VERSION ""

NS_ :

BS_:

BU_: MLM IBU_HS ILCU_RH MFSW DPSU ILCU_LH PSB APSU DPSS SWRC CGW PTGM DLBCU SCM DAU WPC IAU eCall PFSU RDC PSM

BO_ 3221225472 VECTOR__INDEPENDENT_SIG_MSG: 0 Vector__XXX
 SG_ SCC_NSCCOnOffSta : 0|2@1+ (1,0) [0|0] "" Vector__XXX
 SG_ SCC_ObjSta : 0|3@1+ (1,0) [0|0] "" Vector__XXX
 SG_ SCC_SnstvtyModRetVal : 0|3@1+ (1,0) [0|0] "" Vector__XXX
 SG_ APSS_GST_Byte0 : 0|8@1+ (1,0) [0|0] "" Vector__XXX
 SG_ APSS_GST_Byte1 : 0|8@1+ (1,0) [0|0] "" Vector__XXX
 SG_ APSS_GST_Byte2 : 0|8@1+ (1,0) [0|0] "" Vector__XXX
 SG_ APSS_GST_Byte3 : 0|8@1+ (1,0) [0|0] "" Vector__XXX
 SG_ APSS_GST_Byte4 : 0|8@1+ (1,0) [0|0] "" Vector__XXX
 SG_ APSS_GST_Byte5 : 0|8@1+ (1,0) [0|0] "" Vector__XXX
 SG_ APSS_GST_Byte6 : 0|8@1+ (1,0) [0|0] "" Vector__XXX
 SG_ APSS_GST_Byte7 : 0|8@1+ (1,0) [0|0] "" Vector__XXX
 SG_ eCall_GST_Byte0 : 0|8@1+ (1,0) [0|0] "" Vector__XXX
 SG_ eCall_GST_Byte1 : 0|8@1+ (1,0) [0|0] "" Vector__XXX
 SG_ eCall_GST_Byte2 : 0|8@1+ (1,0) [0|0] "" Vector__XXX
 SG_ eCall_GST_Byte3 : 0|8@1+ (1,0) [0|0] "" Vector__XXX
 SG_ eCall_GST_Byte4 : 0|8@1+ (1,0) [0|0] "" Vector__XXX
 SG_ eCall_GST_Byte5 : 0|8@1+ (1,0) [0|0] "" Vector__XXX
 SG_ eCall_GST_Byte6 : 0|8@1+ (1,0) [0|0] "" Vector__XXX
 SG_ eCall_GST_Byte7 : 0|8@1+ (1,0) [0|0] "" Vector__XXX
 SG_ SCC_TrgtDstVal : 0|11@1+ (0.1,0) [0|0] "m" Vector__XXX
 SG_ DATC_Crc5Val : 0|16@1+ (1,0) [0|0] "" Vector__XXX
 SG_ DATC_AlvCnt5Val : 0|8@1+ (1,0) [0|0] "" Vector__XXX
 SG_ DATC_TempDispUnitSta : 0|2@1+ (1,0) [0|0] "" Vector__XXX
 SG_ DATC_IntakeSta : 0|2@1+ (1,0) [0|0] "" Vector__XXX
 SG_ SWRC_Crc3Val : 0|8@1+ (1,0) [0|0] "" Vector__XXX
 SG_ SWRC_AlvCnt3Val : 0|4@1+ (1,0) [0|0] "" Vector__XXX
 SG_ SWRC_CrsSwSta : 0|3@1+ (1,0) [0|0] "" Vector__XXX
 SG_ SWRC_CrsMainSwSta : 0|2@1+ (1,0) [0|0] "" Vector__XXX
 SG_ SWRC_LFASwSta : 0|2@1+ (1,0) [0|0] "" Vector__XXX
 SG_ SWRC_PaddleUpSwSta : 0|2@1+ (1,0) [0|0] "" Vector__XXX
 SG_ SWRC_PaddleDnSwSta : 0|2@1+ (1,0) [0|0] "" Vector__XXX
 SG_ SWRC_Info : 0|2@1+ (1,0) [0|0] "" Vector__XXX
 SG_ GST_SCM_Byte0 : 0|8@1+ (1,0) [0|0] "" Vector__XXX
 SG_ GST_SCM_Byte1 : 0|8@1+ (1,0) [0|0] "" Vector__XXX
 SG_ GST_SCM_Byte2 : 0|8@1+ (1,0) [0|0] "" Vector__XXX
 SG_ GST_SCM_Byte3 : 0|8@1+ (1,0) [0|0] "" Vector__XXX
 SG_ GST_SCM_Byte4 : 0|8@1+ (1,0) [0|0] "" Vector__XXX
 SG_ GST_SCM_Byte5 : 0|8@1+ (1,0) [0|0] "" Vector__XXX
 SG_ GST_SCM_Byte6 : 0|8@1+ (1,0) [0|0] "" Vector__XXX
 SG_ GST_SCM_Byte7 : 0|8@1+ (1,0) [0|0] "" Vector__XXX
 SG_ GST_SWRC_Byte0 : 0|8@1+ (1,0) [0|0] "" Vector__XXX
 SG_ GST_SWRC_Byte1 : 0|8@1+ (1,0) [0|0] "" Vector__XXX
 SG_ GST_SWRC_Byte2 : 0|8@1+ (1,0) [0|0] "" Vector__XXX
 SG_ GST_SWRC_Byte3 : 0|8@1+ (1,0) [0|0] "" Vector__XXX
 SG_ GST_SWRC_Byte4 : 0|8@1+ (1,0) [0|0] "" Vector__XXX
 SG_ GST_SWRC_Byte5 : 0|8@1+ (1,0) [0|0] "" Vector__XXX
 SG_ GST_SWRC_Byte6 : 0|8@1+ (1,0) [0|0] "" Vector__XXX
 SG_ GST_SWRC_Byte7 : 0|8@1+ (1,0) [0|0] "" Vector__XXX
 SG_ GST_MFSW_Byte0 : 0|8@1+ (1,0) [0|0] "" Vector__XXX
 SG_ GST_MFSW_Byte1 : 0|8@1+ (1,0) [0|0] "" Vector__XXX
 SG_ GST_MFSW_Byte2 : 0|8@1+ (1,0) [0|0] "" Vector__XXX
 SG_ GST_MFSW_Byte3 : 0|8@1+ (1,0) [0|0] "" Vector__XXX
 SG_ GST_MFSW_Byte4 : 0|8@1+ (1,0) [0|0] "" Vector__XXX
 SG_ GST_MFSW_Byte5 : 0|8@1+ (1,0) [0|0] "" Vector__XXX
 SG_ GST_MFSW_Byte6 : 0|8@1+ (1,0) [0|0] "" Vector__XXX
 SG_ GST_MFSW_Byte7 : 0|8@1+ (1,0) [0|0] "" Vector__XXX
 SG_ GST_DAU_Byte0 : 0|8@1+ (1,0) [0|0] "" Vector__XXX
 SG_ GST_DAU_Byte1 : 0|8@1+ (1,0) [0|0] "" Vector__XXX
 SG_ GST_DAU_Byte2 : 0|8@1+ (1,0) [0|0] "" Vector__XXX
 SG_ GST_DAU_Byte3 : 0|8@1+ (1,0) [0|0] "" Vector__XXX
 SG_ GST_DAU_Byte4 : 0|8@1+ (1,0) [0|0] "" Vector__XXX
 SG_ GST_DAU_Byte5 : 0|8@1+ (1,0) [0|0] "" Vector__XXX
 SG_ GST_DAU_Byte6 : 0|8@1+ (1,0) [0|0] "" Vector__XXX
 SG_ GST_DAU_Byte7 : 0|8@1+ (1,0) [0|0] "" Vector__XXX
 SG_ GST_IBU_HS_Byte0 : 0|8@1+ (1,0) [0|0] "" Vector__XXX
 SG_ GST_IBU_HS_Byte1 : 0|8@1+ (1,0) [0|0] "" Vector__XXX
 SG_ GST_IBU_HS_Byte2 : 0|8@1+ (1,0) [0|0] "" Vector__XXX
 SG_ GST_IBU_HS_Byte3 : 0|8@1+ (1,0) [0|0] "" Vector__XXX
 SG_ GST_IBU_HS_Byte4 : 0|8@1+ (1,0) [0|0] "" Vector__XXX
 SG_ GST_IBU_HS_Byte5 : 0|8@1+ (1,0) [0|0] "" Vector__XXX
 SG_ GST_IBU_HS_Byte6 : 0|8@1+ (1,0) [0|0] "" Vector__XXX
 SG_ GST_IBU_HS_Byte7 : 0|8@1+ (1,0) [0|0] "" Vector__XXX
 SG_ GST_PSM_PSU_Byte0 : 0|8@1+ (1,0) [0|0] "" Vector__XXX
 SG_ GST_PSM_PSU_Byte1 : 0|8@1+ (1,0) [0|0] "" Vector__XXX
 SG_ GST_PSM_PSU_Byte2 : 0|8@1+ (1,0) [0|0] "" Vector__XXX
 SG_ GST_PSM_PSU_Byte3 : 0|8@1+ (1,0) [0|0] "" Vector__XXX
 SG_ GST_PSM_PSU_Byte4 : 0|8@1+ (1,0) [0|0] "" Vector__XXX
 SG_ GST_PSM_PSU_Byte5 : 0|8@1+ (1,0) [0|0] "" Vector__XXX
 SG_ GST_PSM_PSU_Byte6 : 0|8@1+ (1,0) [0|0] "" Vector__XXX
 SG_ GST_PSM_PSU_Byte7 : 0|8@1+ (1,0) [0|0] "" Vector__XXX
 SG_ BCM_Crc3Val : 0|8@1+ (1,0) [0|0] "" Vector__XXX
 SG_ BCM_AlvCnt3Val : 0|4@1+ (1,0) [0|0] "" Vector__XXX
 SG_ SBR_StBltWrngBzrSta : 0|3@1+ (1,0) [0|0] "" Vector__XXX
 SG_ SBR_DrvStBltIndSta : 0|2@1+ (1,0) [0|0] "" Vector__XXX
 SG_ SBR_RrLftStBltWrngIndSta : 0|2@1+ (1,0) [0|0] "" Vector__XXX
 SG_ SBR_RrRtStBltWrngIndSta : 0|2@1+ (1,0) [0|0] "" Vector__XXX
 SG_ SBR_RrCtrStBltIndSta : 0|2@1+ (1,0) [0|0] "" Vector__XXX
 SG_ SBR_3rdLftStBltWrngIndSta : 0|2@1+ (1,0) [0|0] "" Vector__XXX
 SG_ SBR_3rdRtStBltWrngIndSta : 0|2@1+ (1,0) [0|0] "" Vector__XXX
 SG_ SCM_GST_Byte0 : 0|8@1+ (1,0) [0|0] "" Vector__XXX
 SG_ SCM_GST_Byte1 : 0|8@1+ (1,0) [0|0] "" Vector__XXX
 SG_ SCM_GST_Byte2 : 0|8@1+ (1,0) [0|0] "" Vector__XXX
 SG_ SCM_GST_Byte3 : 0|8@1+ (1,0) [0|0] "" Vector__XXX
 SG_ SCM_GST_Byte4 : 0|8@1+ (1,0) [0|0] "" Vector__XXX
 SG_ SCM_GST_Byte5 : 0|8@1+ (1,0) [0|0] "" Vector__XXX
 SG_ SCM_GST_Byte6 : 0|8@1+ (1,0) [0|0] "" Vector__XXX
 SG_ SCM_GST_Byte7 : 0|8@1+ (1,0) [0|0] "" Vector__XXX
 SG_ BCM_Crc2Val : 0|8@1+ (1,0) [0|0] "" Vector__XXX
 SG_ BCM_AlvCnt2Val : 0|4@1+ (1,0) [0|0] "" Vector__XXX
 SG_ BAlarm_BglrAlrmCurrentSta : 0|4@1+ (1,0) [0|0] "" Vector__XXX
 SG_ BAlarm_BglrAlrmSta : 0|2@1+ (1,0) [0|0] "" Vector__XXX
 SG_ BAlarm_PncAlrmSta : 0|2@1+ (1,0) [0|0] "" Vector__XXX
 SG_ BAlarm_BrglrHrnRlySta : 0|2@1+ (1,0) [0|0] "" Vector__XXX
 SG_ BCM_AccInSta : 0|2@1+ (1,0) [0|0] "" Vector__XXX
 SG_ BCM_Ign1InSta : 0|2@1+ (1,0) [0|0] "" Vector__XXX
 SG_ BCM_Ign2InSta : 0|2@1+ (1,0) [0|0] "" Vector__XXX
 SG_ BCM_IgnSwSta : 0|3@1+ (1,0) [0|0] "" Vector__XXX
 SG_ SWRC_GST_Byte0 : 0|8@1+ (1,0) [0|0] "" Vector__XXX
 SG_ SWRC_GST_Byte1 : 0|8@1+ (1,0) [0|0] "" Vector__XXX
 SG_ SWRC_GST_Byte2 : 0|8@1+ (1,0) [0|0] "" Vector__XXX
 SG_ SWRC_GST_Byte3 : 0|8@1+ (1,0) [0|0] "" Vector__XXX
 SG_ SWRC_GST_Byte4 : 0|8@1+ (1,0) [0|0] "" Vector__XXX
 SG_ SWRC_GST_Byte5 : 0|8@1+ (1,0) [0|0] "" Vector__XXX
 SG_ SWRC_GST_Byte6 : 0|8@1+ (1,0) [0|0] "" Vector__XXX
 SG_ SWRC_GST_Byte7 : 0|8@1+ (1,0) [0|0] "" Vector__XXX
 SG_ MFSW_GST_Byte0 : 0|8@1+ (1,0) [0|0] "" Vector__XXX
 SG_ MFSW_GST_Byte1 : 0|8@1+ (1,0) [0|0] "" Vector__XXX
 SG_ MFSW_GST_Byte2 : 0|8@1+ (1,0) [0|0] "" Vector__XXX
 SG_ MFSW_GST_Byte3 : 0|8@1+ (1,0) [0|0] "" Vector__XXX
 SG_ MFSW_GST_Byte4 : 0|8@1+ (1,0) [0|0] "" Vector__XXX
 SG_ MFSW_GST_Byte5 : 0|8@1+ (1,0) [0|0] "" Vector__XXX
 SG_ MFSW_GST_Byte6 : 0|8@1+ (1,0) [0|0] "" Vector__XXX
 SG_ MFSW_GST_Byte7 : 0|8@1+ (1,0) [0|0] "" Vector__XXX
 SG_ BCM_Crc4Val : 0|8@1+ (1,0) [0|0] "" Vector__XXX
 SG_ BCM_AlvCnt4Val : 0|4@1+ (1,0) [0|0] "" Vector__XXX
 SG_ Warn_BzrWrngSta : 0|4@1+ (1,0) [0|0] "" Vector__XXX
 SG_ Warn_BCMWrngSta : 0|4@1+ (1,0) [0|0] "" Vector__XXX
 SG_ Warn_RrStRmndOpt : 0|2@1+ (1,0) [0|0] "" Vector__XXX
 SG_ Warn_RrStRmndAlrmOnReq : 0|2@1+ (1,0) [0|0] "" Vector__XXX
 SG_ Warn_RrStRmndSysSta : 0|2@1+ (1,0) [0|0] "" Vector__XXX
 SG_ Warn_RrStRmndAlrmInfo : 0|3@1+ (1,0) [0|0] "" Vector__XXX
 SG_ DAU_GST_Byte0 : 0|8@1+ (1,0) [0|0] "" Vector__XXX
 SG_ DAU_GST_Byte1 : 0|8@1+ (1,0) [0|0] "" Vector__XXX
 SG_ DAU_GST_Byte2 : 0|8@1+ (1,0) [0|0] "" Vector__XXX
 SG_ DAU_GST_Byte3 : 0|8@1+ (1,0) [0|0] "" Vector__XXX
 SG_ DAU_GST_Byte4 : 0|8@1+ (1,0) [0|0] "" Vector__XXX
 SG_ DAU_GST_Byte5 : 0|8@1+ (1,0) [0|0] "" Vector__XXX
 SG_ DAU_GST_Byte6 : 0|8@1+ (1,0) [0|0] "" Vector__XXX
 SG_ DAU_GST_Byte7 : 0|8@1+ (1,0) [0|0] "" Vector__XXX
 SG_ BCM_Crc5Val : 0|8@1+ (1,0) [0|0] "" Vector__XXX
 SG_ BCM_AlvCnt5Val : 0|4@1+ (1,0) [0|0] "" Vector__XXX
 SG_ PDW_OptTyp : 0|3@1+ (1,0) [0|0] "" Vector__XXX
 SG_ PDW_SysChkSndSta : 0|3@1+ (1,0) [0|0] "" Vector__XXX
 SG_ PDW_SwIndOnReq : 0|2@1+ (1,0) [0|0] "" Vector__XXX
 SG_ PDW_SysOnSta : 0|3@1+ (1,0) [0|0] "" Vector__XXX
 SG_ PDW_FrCtrWrngLvlDis : 0|3@1+ (1,0) [0|0] "" Vector__XXX
 SG_ PDW_FrCtrWrngSndSta : 0|3@1+ (1,0) [0|0] "" Vector__XXX
 SG_ PDW_FrLftWrngLvlDis : 0|3@1+ (1,0) [0|0] "" Vector__XXX
 SG_ PDW_FrLftWrngSndSta : 0|3@1+ (1,0) [0|0] "" Vector__XXX
 SG_ PDW_FrRtWrngLvlDis : 0|3@1+ (1,0) [0|0] "" Vector__XXX
 SG_ PDW_FrRtWrngSndSta : 0|3@1+ (1,0) [0|0] "" Vector__XXX
 SG_ PDW_FrSnsrWrngLvlSta : 0|3@1+ (1,0) [0|0] "" Vector__XXX
 SG_ IBU_HS_GST_Byte0 : 0|8@1+ (1,0) [0|0] "" Vector__XXX
 SG_ IBU_HS_GST_Byte1 : 0|8@1+ (1,0) [0|0] "" Vector__XXX
 SG_ IBU_HS_GST_Byte2 : 0|8@1+ (1,0) [0|0] "" Vector__XXX
 SG_ IBU_HS_GST_Byte3 : 0|8@1+ (1,0) [0|0] "" Vector__XXX
 SG_ IBU_HS_GST_Byte4 : 0|8@1+ (1,0) [0|0] "" Vector__XXX
 SG_ IBU_HS_GST_Byte5 : 0|8@1+ (1,0) [0|0] "" Vector__XXX
 SG_ IBU_HS_GST_Byte6 : 0|8@1+ (1,0) [0|0] "" Vector__XXX
 SG_ IBU_HS_GST_Byte7 : 0|8@1+ (1,0) [0|0] "" Vector__XXX
 SG_ PSM_PSU_GST_Byte0 : 0|8@1+ (1,0) [0|0] "" Vector__XXX
 SG_ PSM_PSU_GST_Byte1 : 0|8@1+ (1,0) [0|0] "" Vector__XXX
 SG_ PSM_PSU_GST_Byte2 : 0|8@1+ (1,0) [0|0] "" Vector__XXX
 SG_ PSM_PSU_GST_Byte3 : 0|8@1+ (1,0) [0|0] "" Vector__XXX
 SG_ PSM_PSU_GST_Byte4 : 0|8@1+ (1,0) [0|0] "" Vector__XXX
 SG_ PSM_PSU_GST_Byte5 : 0|8@1+ (1,0) [0|0] "" Vector__XXX
 SG_ PSM_PSU_GST_Byte6 : 0|8@1+ (1,0) [0|0] "" Vector__XXX
 SG_ PSM_PSU_GST_Byte7 : 0|8@1+ (1,0) [0|0] "" Vector__XXX
 SG_ BCM_Crc6Val : 0|8@1+ (1,0) [0|0] "" Vector__XXX
 SG_ BCM_AlvCnt6Val : 0|4@1+ (1,0) [0|0] "" Vector__XXX
 SG_ PDW_RrCtrWrngLvlDis : 0|3@1+ (1,0) [0|0] "" Vector__XXX
 SG_ PDW_RrCtrWrngSndSta : 0|3@1+ (1,0) [0|0] "" Vector__XXX
 SG_ PDW_RrLftWrngLvlDis : 0|3@1+ (1,0) [0|0] "" Vector__XXX
 SG_ PDW_RrLftWrngSndSta : 0|3@1+ (1,0) [0|0] "" Vector__XXX
 SG_ PDW_RrRtWrngLvlDis : 0|3@1+ (1,0) [0|0] "" Vector__XXX
 SG_ PDW_RrRtWrngSndSta : 0|3@1+ (1,0) [0|0] "" Vector__XXX
 SG_ PDW_RrSnsrWrngLvlSta : 0|3@1+ (1,0) [0|0] "" Vector__XXX
 SG_ GST_APSU_Byte0 : 0|8@1+ (1,0) [0|0] "" Vector__XXX
 SG_ GST_APSU_Byte1 : 0|8@1+ (1,0) [0|0] "" Vector__XXX
 SG_ GST_APSU_Byte2 : 0|8@1+ (1,0) [0|0] "" Vector__XXX
 SG_ GST_APSU_Byte3 : 0|8@1+ (1,0) [0|0] "" Vector__XXX
 SG_ GST_APSU_Byte4 : 0|8@1+ (1,0) [0|0] "" Vector__XXX
 SG_ GST_APSU_Byte5 : 0|8@1+ (1,0) [0|0] "" Vector__XXX
 SG_ GST_APSU_Byte6 : 0|8@1+ (1,0) [0|0] "" Vector__XXX
 SG_ GST_APSU_Byte7 : 0|8@1+ (1,0) [0|0] "" Vector__XXX
 SG_ APSU_GST_Byte0 : 0|8@1+ (1,0) [0|0] "" Vector__XXX
 SG_ APSU_GST_Byte1 : 0|8@1+ (1,0) [0|0] "" Vector__XXX
 SG_ APSU_GST_Byte2 : 0|8@1+ (1,0) [0|0] "" Vector__XXX
 SG_ APSU_GST_Byte3 : 0|8@1+ (1,0) [0|0] "" Vector__XXX
 SG_ APSU_GST_Byte4 : 0|8@1+ (1,0) [0|0] "" Vector__XXX
 SG_ APSU_GST_Byte5 : 0|8@1+ (1,0) [0|0] "" Vector__XXX
 SG_ APSU_GST_Byte6 : 0|8@1+ (1,0) [0|0] "" Vector__XXX
 SG_ APSU_GST_Byte7 : 0|8@1+ (1,0) [0|0] "" Vector__XXX
 SG_ EPB_Crc1Val : 0|16@1+ (1,0) [0|0] "" Vector__XXX
 SG_ EPB_AlvCnt1Val : 0|8@1+ (1,0) [0|0] "" Vector__XXX
 SG_ EPB_LmpStaDis : 0|4@1+ (1,0) [0|0] "" Vector__XXX
 SG_ EPB_FlrLmpStaDis : 0|4@1+ (1,0) [0|0] "" Vector__XXX
 SG_ EPB_OutDataDis : 0|8@1+ (1,0) [0|0] "" Vector__XXX
 SG_ EPB_AlrmReq : 0|2@1+ (1,0) [0|0] "" Vector__XXX
 SG_ EPB_SwPosSta : 0|2@1+ (1,0) [0|0] "" Vector__XXX
 SG_ EPB_RrBrkLtActvReq : 0|2@1+ (1,0) [0|0] "" Vector__XXX
 SG_ EPB_FrcErrSta : 0|2@1+ (1,0) [0|0] "" Vector__XXX
 SG_ EPB_DynmBrkFrcReqSigSta : 0|2@1+ (1,0) [0|0] "" Vector__XXX
 SG_ EPB_FrcSta : 0|3@1+ (1,0) [0|0] "" Vector__XXX
 SG_ EPB_FlSta : 0|3@1+ (1,0) [0|0] "" Vector__XXX
 SG_ EPB_EscReqAckSta : 0|2@1+ (1,0) [0|0] "" Vector__XXX
 SG_ EPB_DynmBrkFrcReq : 0|2@1+ (1,0) [0|0] "" Vector__XXX
 SG_ EPB_ActlFrcVal : 0|12@1+ (1,-1000) [0|0] "" Vector__XXX
 SG_ EPB_DynmBrkFrcDclReq : 0|8@1+ (0.01,0) [0|0] "g" Vector__XXX
 SG_ MFSW_Crc2Val : 0|8@1+ (1,0) [0|0] "" Vector__XXX
 SG_ MFSW_AlvCnt2Val : 0|4@1+ (1,0) [0|0] "" Vector__XXX
 SG_ Wiper_FrWiperSwSta : 0|3@1+ (1,0) [0|0] "" Vector__XXX
 SG_ Wiper_IntStepSta : 0|3@1+ (1,0) [0|0] "" Vector__XXX
 SG_ Wiper_MstSwSta : 0|2@1+ (1,0) [0|0] "" Vector__XXX
 SG_ Wiper_RrWiperSwSta : 0|2@1+ (1,0) [0|0] "" Vector__XXX
 SG_ Wiper_FrWiperWshSwSta : 0|2@1+ (1,0) [0|0] "" Vector__XXX
 SG_ Wiper_RrWiperWshSwSta : 0|2@1+ (1,0) [0|0] "" Vector__XXX
 SG_ MFSW_Info : 0|2@1+ (1,0) [0|0] "" Vector__XXX
 SG_ RCCA_Deccel_Req : 0|4@1+ (0.04,0) [0|0] "Sec" Vector__XXX
 SG_ RCCA_BrkCmdSta : 0|2@1+ (1,0) [0|0] "" Vector__XXX
 SG_ RCCA_LftWrngSta : 0|2@1+ (1,0) [0|0] "" Vector__XXX
 SG_ RCCA_RtWrngSta : 0|2@1+ (1,0) [0|0] "" Vector__XXX
 SG_ RCCA_FuncStat : 0|2@1+ (1,0) [0|0] "" Vector__XXX
 SG_ RCCA_Sta : 0|4@1+ (1,0) [0|0] "" Vector__XXX
 SG_ SEA_Sta : 0|4@1+ (1,0) [0|0] "" Vector__XXX
 SG_ SEA_OnOffEquipSta : 0|2@1+ (1,0) [0|0] "" Vector__XXX
 SG_ SEA_LftWrngSta : 0|2@1+ (1,0) [0|0] "" Vector__XXX
 SG_ SEA_RtWrngSta : 0|2@1+ (1,0) [0|0] "" Vector__XXX
 SG_ RR_C_RDR_Equip : 0|3@1+ (1,0) [0|0] "" Vector__XXX
 SG_ MFSW_Crc1Val : 0|8@1+ (1,0) [0|0] "" Vector__XXX
 SG_ MFSW_AlvCnt1Val : 0|4@1+ (1,0) [0|0] "" Vector__XXX
 SG_ Lamp_HdLmpHiSwSta : 0|2@1+ (1,0) [0|0] "" Vector__XXX
 SG_ Lamp_LtSwSta : 0|2@1+ (1,0) [0|0] "" Vector__XXX
 SG_ Lamp_PassingLmpSwSta : 0|2@1+ (1,0) [0|0] "" Vector__XXX
 SG_ Lamp_RrFogLmpSwSta : 0|2@1+ (1,0) [0|0] "" Vector__XXX
 SG_ Lamp_TrnSigLftSwSta : 0|2@1+ (1,0) [0|0] "" Vector__XXX
 SG_ Lamp_TrnSigRtSwSta : 0|2@1+ (1,0) [0|0] "" Vector__XXX
 SG_ Lamp_LaneChgTrnSigLftSwSta : 0|2@1+ (1,0) [0|0] "" Vector__XXX
 SG_ Lamp_LaneChgTrnSigRtSwSta : 0|2@1+ (1,0) [0|0] "" Vector__XXX
 SG_ RR_C_RDR_Crc1Val : 0|16@1+ (1,0) [0|0] "" Vector__XXX
 SG_ RR_C_RDR_AlvCnt1Val : 0|8@1+ (1,0) [0|0] "" Vector__XXX
 SG_ RCCW_Sta : 0|4@1+ (1,0) [0|0] "" Vector__XXX
 SG_ RCCW_OnOffEquipSt : 0|2@1+ (1,0) [0|0] "" Vector__XXX
 SG_ RCCW_LftIndSta : 0|2@1+ (1,0) [0|0] "" Vector__XXX
 SG_ RCCW_RtIndSta : 0|2@1+ (1,0) [0|0] "" Vector__XXX
 SG_ RCCW_LftSndWrngSta : 0|2@1+ (1,0) [0|0] "" Vector__XXX
 SG_ RCCW_RtSndWrngSta : 0|2@1+ (1,0) [0|0] "" Vector__XXX
 SG_ RCCW_LftWrngIndBriLvlVal : 0|8@1+ (1,0) [0|0] "" Vector__XXX
 SG_ RCCW_RtWrngIndBriLvlVal : 0|8@1+ (1,0) [0|0] "" Vector__XXX
 SG_ Destination_MLM : 0|8@1+ (1,0) [0|0] "" Vector__XXX
 SG_ NMSleepFlag_MLM : 0|2@1+ (1,0) [0|0] "" Vector__XXX
 SG_ NMCommandCode_MLM : 0|3@1+ (1,0) [0|0] "" Vector__XXX
 SG_ Destination_IBU_HS : 0|8@1+ (1,0) [0|0] "" Vector__XXX
 SG_ NMSleepFlag_IBU_HS : 0|2@1+ (1,0) [0|0] "" Vector__XXX
 SG_ NMCommandCode_IBU_HS : 0|3@1+ (1,0) [0|0] "" Vector__XXX
 SG_ Destination_ILCU_RH : 0|8@1+ (1,0) [0|0] "" Vector__XXX
 SG_ NMSleepFlag_ILCU_RH : 0|2@1+ (1,0) [0|0] "" Vector__XXX
 SG_ NMCommandCode_ILCU_RH : 0|3@1+ (1,0) [0|0] "" Vector__XXX
 SG_ Destination_MFSW : 0|8@1+ (1,0) [0|0] "" Vector__XXX
 SG_ NMSleepFlag_MFSW : 0|2@1+ (1,0) [0|0] "" Vector__XXX
 SG_ NMCommandCode_MFSW : 0|3@1+ (1,0) [0|0] "" Vector__XXX
 SG_ Destination_ILCU_LH : 0|8@1+ (1,0) [0|0] "" Vector__XXX
 SG_ NMSleepFlag_ILCU_LH : 0|2@1+ (1,0) [0|0] "" Vector__XXX
 SG_ NMCommandCode_ILCU_LH : 0|3@1+ (1,0) [0|0] "" Vector__XXX
 SG_ Destination_PSB : 0|8@1+ (1,0) [0|0] "" Vector__XXX
 SG_ NMSleepFlag_PSB : 0|2@1+ (1,0) [0|0] "" Vector__XXX
 SG_ NMCommandCode_PSB : 0|3@1+ (1,0) [0|0] "" Vector__XXX
 SG_ Destination_APSU : 0|8@1+ (1,0) [0|0] "" Vector__XXX
 SG_ NMSleepFlag_APSU : 0|2@1+ (1,0) [0|0] "" Vector__XXX
 SG_ NMCommandCode_APSU : 0|3@1+ (1,0) [0|0] "" Vector__XXX
 SG_ Destination_DPSS : 0|8@1+ (1,0) [0|0] "" Vector__XXX
 SG_ NMSleepFlag_DPSS : 0|2@1+ (1,0) [0|0] "" Vector__XXX
 SG_ NMCommandCode_DPSS : 0|3@1+ (1,0) [0|0] "" Vector__XXX
 SG_ Destination_SWRC : 0|8@1+ (1,0) [0|0] "" Vector__XXX
 SG_ NMSleepFlag_SWRC : 0|2@1+ (1,0) [0|0] "" Vector__XXX
 SG_ NMCommandCode_SWRC : 0|3@1+ (1,0) [0|0] "" Vector__XXX
 SG_ Destination_CGW : 0|8@1+ (1,0) [0|0] "" Vector__XXX
 SG_ NMSleepFlag_CGW : 0|2@1+ (1,0) [0|0] "" Vector__XXX
 SG_ NMCommandCode_CGW : 0|3@1+ (1,0) [0|0] "" Vector__XXX
 SG_ Destination_PTGM : 0|8@1+ (1,0) [0|0] "" Vector__XXX
 SG_ NMSleepFlag_PTGM : 0|2@1+ (1,0) [0|0] "" Vector__XXX
 SG_ NMCommandCode_PTGM : 0|3@1+ (1,0) [0|0] "" Vector__XXX
 SG_ Destination_DLBCU : 0|8@1+ (1,0) [0|0] "" Vector__XXX
 SG_ NMSleepFlag_DLBCU : 0|2@1+ (1,0) [0|0] "" Vector__XXX
 SG_ NMCommandCode_DLBCU : 0|3@1+ (1,0) [0|0] "" Vector__XXX
 SG_ Destination_SCM : 0|8@1+ (1,0) [0|0] "" Vector__XXX
 SG_ NMSleepFlag_SCM : 0|2@1+ (1,0) [0|0] "" Vector__XXX
 SG_ NMCommandCode_SCM : 0|3@1+ (1,0) [0|0] "" Vector__XXX
 SG_ Destination_DAU : 0|8@1+ (1,0) [0|0] "" Vector__XXX
 SG_ NMSleepFlag_DAU : 0|2@1+ (1,0) [0|0] "" Vector__XXX
 SG_ NMCommandCode_DAU : 0|3@1+ (1,0) [0|0] "" Vector__XXX
 SG_ Destination_WPC : 0|8@1+ (1,0) [0|0] "" Vector__XXX
 SG_ NMSleepFlag_WPC : 0|2@1+ (1,0) [0|0] "" Vector__XXX
 SG_ NMCommandCode_WPC : 0|3@1+ (1,0) [0|0] "" Vector__XXX
 SG_ Destination_IAU : 0|8@1+ (1,0) [0|0] "" Vector__XXX
 SG_ NMSleepFlag_IAU : 0|2@1+ (1,0) [0|0] "" Vector__XXX
 SG_ NMCommandCode_IAU : 0|3@1+ (1,0) [0|0] "" Vector__XXX
 SG_ Destination_PFSU : 0|8@1+ (1,0) [0|0] "" Vector__XXX
 SG_ NMSleepFlag_PFSU : 0|2@1+ (1,0) [0|0] "" Vector__XXX
 SG_ NMCommandCode_PFSU : 0|3@1+ (1,0) [0|0] "" Vector__XXX
 SG_ Destination_PSM : 0|8@1+ (1,0) [0|0] "" Vector__XXX
 SG_ NMSleepFlag_PSM : 0|2@1+ (1,0) [0|0] "" Vector__XXX
 SG_ NMCommandCode_PSM : 0|3@1+ (1,0) [0|0] "" Vector__XXX

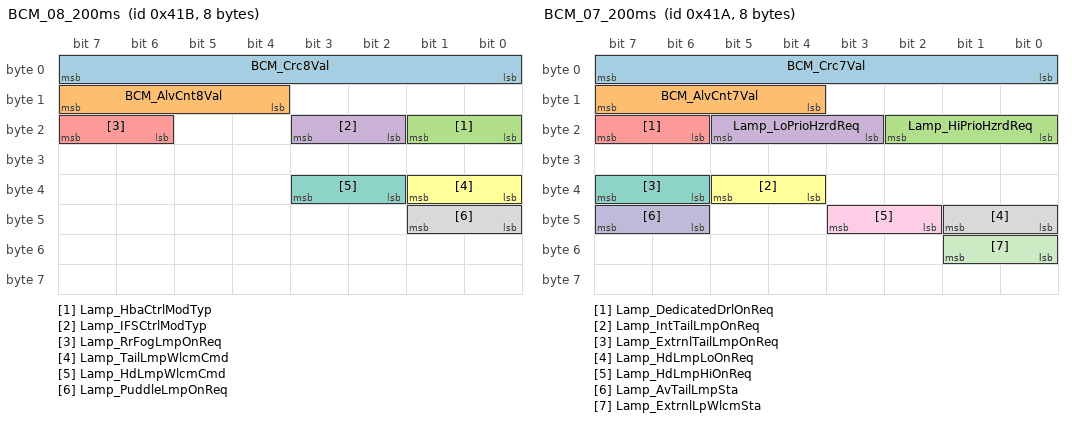
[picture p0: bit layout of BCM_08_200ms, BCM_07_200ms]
BO_ 1051 BCM_08_200ms: 8 IBU_HS
 SG_ BCM_Crc8Val : 0|8@1+ (1,0) [0|0] "" Vector__XXX
 SG_ BCM_AlvCnt8Val : 12|4@1+ (1,0) [0|0] "" Vector__XXX
 SG_ Lamp_HbaCtrlModTyp : 16|2@1+ (1,0) [0|0] ""  CGW
 SG_ Lamp_IFSCtrlModTyp : 18|2@1+ (1,0) [0|0] ""  ILCU_LH,ILCU_RH
 SG_ Lamp_RrFogLmpOnReq : 22|2@1+ (1,0) [0|0] ""  CGW
 SG_ Lamp_TailLmpWlcmCmd : 32|2@1+ (1,0) [0|0] ""  CGW
 SG_ Lamp_HdLmpWlcmCmd : 34|2@1+ (1,0) [0|0] ""  CGW
 SG_ Lamp_PuddleLmpOnReq : 40|2@1+ (1,0) [0|0] ""  DAU

BO_ 1050 BCM_07_200ms: 8 IBU_HS
 SG_ BCM_Crc7Val : 0|8@1+ (1,0) [0|0] ""  CGW
 SG_ BCM_AlvCnt7Val : 12|4@1+ (1,0) [0|0] ""  CGW
 SG_ Lamp_HiPrioHzrdReq : 16|3@1+ (1,0) [0|0] ""  CGW
 SG_ Lamp_LoPrioHzrdReq : 19|3@1+ (1,0) [0|0] ""  CGW
 SG_ Lamp_DedicatedDrlOnReq : 22|2@1+ (1,0) [0|0] ""  ILCU_LH,ILCU_RH
 SG_ Lamp_IntTailLmpOnReq : 36|2@1+ (1,0) [0|0] ""  MLM,CGW
 SG_ Lamp_ExtrnlTailLmpOnReq : 38|2@1+ (1,0) [0|0] ""  ILCU_LH,ILCU_RH,CGW
 SG_ Lamp_HdLmpLoOnReq : 40|2@1+ (1,0) [0|0] ""  ILCU_LH,ILCU_RH,CGW
 SG_ Lamp_HdLmpHiOnReq : 42|2@1+ (1,0) [0|0] ""  ILCU_LH,ILCU_RH,CGW
 SG_ Lamp_AvTailLmpSta : 46|2@1+ (1,0) [0|0] ""  CGW
 SG_ Lamp_ExtrnlLpWlcmSta : 48|2@1+ (1,0) [0|0] ""  ILCU_LH,ILCU_RH

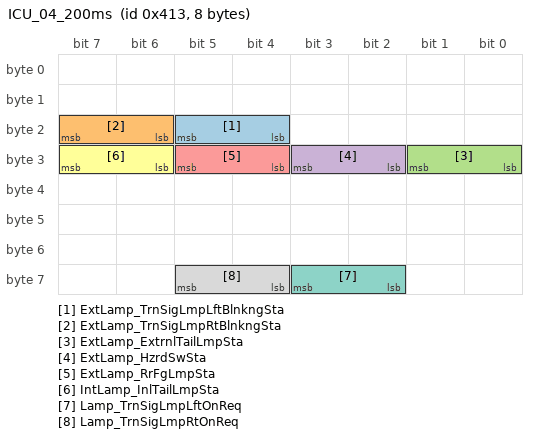
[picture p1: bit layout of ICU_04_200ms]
BO_ 1043 ICU_04_200ms: 8 CGW
 SG_ ExtLamp_TrnSigLmpLftBlnkngSta : 20|2@1+ (1,0) [0|0] "" Vector__XXX
 SG_ ExtLamp_TrnSigLmpRtBlnkngSta : 22|2@1+ (1,0) [0|0] "" Vector__XXX
 SG_ ExtLamp_ExtrnlTailLmpSta : 24|2@1+ (1,0) [0|0] "" Vector__XXX
 SG_ ExtLamp_HzrdSwSta : 26|2@1+ (1,0) [0|0] "" Vector__XXX
 SG_ ExtLamp_RrFgLmpSta : 28|2@1+ (1,0) [0|0] "" Vector__XXX
 SG_ IntLamp_InlTailLmpSta : 30|2@1+ (1,0) [0|0] ""  DAU,WPC,MFSW,SWRC
 SG_ Lamp_TrnSigLmpLftOnReq : 58|2@1+ (1,0) [0|0] ""  ILCU_LH,ILCU_RH
 SG_ Lamp_TrnSigLmpRtOnReq : 60|2@1+ (1,0) [0|0] ""  ILCU_LH,ILCU_RH

CM_ SG_ 3221225472 SCC_NSCCOnOffSta "SCC_NSCCOnOffStatus ##2G##SCC - SCC13 - NSCC_Zone_USM";
CM_ SG_ 3221225472 SCC_ObjSta "SCC_ObjectState";
CM_ SG_ 3221225472 SCC_SnstvtyModRetVal "SCC_SensitivityModeReturnValue ##2G##SCC - SCC13 - SCCDrvModeRValue";
CM_ SG_ 3221225472 SCC_TrgtDstVal "SCC_TargetDistanceValue";
CM_ SG_ 3221225472 DATC_Crc5Val "DATC_CyclicRedundancyCheck5Value";
CM_ SG_ 3221225472 DATC_AlvCnt5Val "DATC_AliveCounter5Value";
CM_ SG_ 3221225472 DATC_TempDispUnitSta "DATC_TemperatureDiplayUnitStatus";
CM_ SG_ 3221225472 DATC_IntakeSta "DATC_IntakeStatus";
CM_ SG_ 3221225472 SWRC_Crc3Val "SWRC_CyclicRedundancyCheck3Value";
CM_ SG_ 3221225472 SWRC_AlvCnt3Val "SWRC_AliveCounter3Value";
CM_ SG_ 3221225472 SWRC_CrsSwSta "SWRC_CruiseSwitchStatus";
CM_ SG_ 3221225472 SWRC_CrsMainSwSta "SWRC_CruiseMainSwitchStatus";
CM_ SG_ 3221225472 SWRC_LFASwSta "SWRC_LFASwitchStatus";
CM_ SG_ 3221225472 SWRC_PaddleUpSwSta "SWRC_PaddleUpSwitchStatus";
CM_ SG_ 3221225472 SWRC_PaddleDnSwSta "SWRC_PaddleDownSwitchStatus";
CM_ SG_ 3221225472 SWRC_Info "SWRC_Information_Type";
CM_ SG_ 3221225472 BCM_Crc3Val "BCM_CyclicRedundancyCheck3Value";
CM_ SG_ 3221225472 BCM_AlvCnt3Val "BCM_AliveCounter3Value";
CM_ SG_ 3221225472 SBR_StBltWrngBzrSta "SBR_SeatBeltWarningBuzzerStatus ##2G##BCM - BCMmsg32 - C_SeatBeltWngBuz";
CM_ SG_ 3221225472 SBR_DrvStBltIndSta "SBR_DriverSeatBeltIndicatorStatus ##2G##BCM - BCMmsg32 - C_DrvSeatBeltInd";
CM_ SG_ 3221225472 SBR_RrLftStBltWrngIndSta "SBR_RearLeftSeatBeltWarningIndicatorStatus ##2G##BCM - BCMmsg32 - C_RLSeatBeltInd";
CM_ SG_ 3221225472 SBR_RrRtStBltWrngIndSta "SBR_RearRightSeatBeltWarningIndicatorStatus ##2G##BCM - BCMmsg32 - C_RRSeatBeltInd";
CM_ SG_ 3221225472 SBR_RrCtrStBltIndSta "SBR_RearCenterSeatBeltIndicatorStatus ##2G##BCM - BCMmsg32 - C_RCSeatBeltInd";
CM_ SG_ 3221225472 SBR_3rdLftStBltWrngIndSta "SBR_3rdLeftSeatBeltWarningIndicatorStatus ##2G##BCM - BCMmsg32 - C_3LSeatBeltInd";
CM_ SG_ 3221225472 SBR_3rdRtStBltWrngIndSta "SBR_3rdRightSeatBeltWarningIndicatorStatus ##2G##BCM - BCMmsg32 - C_3RSeatBeltInd";
CM_ SG_ 3221225472 BCM_Crc2Val "BCM_CyclicRedundancyCheck2Value";
CM_ SG_ 3221225472 BCM_AlvCnt2Val "BCM_AliveCounter2Value";
CM_ SG_ 3221225472 BAlarm_BglrAlrmCurrentSta "BAlarm_BuglarAlarmCurrentStatus ##2G##BCM - BCMmsg17 - C_BAlarmState";
CM_ SG_ 3221225472 BAlarm_BglrAlrmSta "BAlarm_BuglarAlarmStatus ##2G##BCM - BCMmsg17 - C_BAState";
CM_ SG_ 3221225472 BAlarm_PncAlrmSta "BAlarm_PanicAlarmStatus ##2G##BCM - BCMmsg17 - C_PanicState";
CM_ SG_ 3221225472 BAlarm_BrglrHrnRlySta "BAlarm_BurglarHornRelayStatus ##2G##BCM - BCMmsg19 - C_BurglarHornRly";
CM_ SG_ 3221225472 BCM_AccInSta "BCM_AccInputStatus ##2G##BCM - BCMmsg17 - C_Acc";
CM_ SG_ 3221225472 BCM_Ign1InSta "BCM_Ignition1InputStatus ##2G##BCM - BCMmsg17 - C_Ign1";
CM_ SG_ 3221225472 BCM_Ign2InSta "BCM_Ignition1InputStatus ##2G##BCM - BCMmsg17 - C_Ign2";
CM_ SG_ 3221225472 BCM_IgnSwSta "BCM_IgnitionSwitchStatus ##2G##BCM - BCMmsg17 - C_IGNSw";
CM_ SG_ 3221225472 BCM_Crc4Val "BCM_CyclicRedundancyCheck4Value";
CM_ SG_ 3221225472 BCM_AlvCnt4Val "BCM_AliveCounter4Value";
CM_ SG_ 3221225472 Warn_BzrWrngSta "Warn_BuzzerWarningStatus ##2G##BCM - BCMmsg18 - C_WngBuz";
CM_ SG_ 3221225472 Warn_BCMWrngSta "Warn_BCMWarningStatus ##2G##BCM - BCMmsg19 - C_BCMWarning";
CM_ SG_ 3221225472 Warn_RrStRmndOpt "Warn_RearSeatReminderOption ##2G##BCM - BCMmsg22 - C_RrSeatRemindOpt";
CM_ SG_ 3221225472 Warn_RrStRmndAlrmOnReq "Warn_RearSeatReminderAlarmOnRequest ##2G##BCM - BCMmsg22 - C_RrSeatRemindAlarm";
CM_ SG_ 3221225472 Warn_RrStRmndSysSta "Warn_RearSeatReminderSystemStatus ##2G##BCM - BCMmsg22 - C_RrSeatRemindState";
CM_ SG_ 3221225472 Warn_RrStRmndAlrmInfo "Warn_RearSeatReminderAlarmInformaion ##2G##BCM - BCMmsg22 - C_RrSeatRemindInfo";
CM_ SG_ 3221225472 BCM_Crc5Val "BCM_CyclicRedundancyCheck5Value";
CM_ SG_ 3221225472 BCM_AlvCnt5Val "BCM_AliveCounter5Value";
CM_ SG_ 3221225472 PDW_OptTyp "PDW_OptionType ##2G##BCM - BCMmsg18 - C_PASOption";
CM_ SG_ 3221225472 PDW_SysChkSndSta "PDW_SystemCheckSoundStatus ##2G##BCM - BCMmsg18 - C_PASCheckSound";
CM_ SG_ 3221225472 PDW_SwIndOnReq "PDW_SwitchIndicatorOnRequest ##2G##BCM - BCMmsg18 - C_PASSwInd";
CM_ SG_ 3221225472 PDW_SysOnSta "PDW_SystemOnStatus ##2G##BCM - BCMmsg18 - C_PASSystemOn";
CM_ SG_ 3221225472 PDW_FrCtrWrngLvlDis "PDW_FrontCenterWarningLevelDisplay ##2G##BCM - BCMmsg18 - C_PASDisplayFCTR";
CM_ SG_ 3221225472 PDW_FrCtrWrngSndSta "PDW_FrontCenterWarningSoundStatus ##2G##BCM - BCMmsg23 - C_PasSpkrFCNTAlarm";
CM_ SG_ 3221225472 PDW_FrLftWrngLvlDis "PDW_FrontLeftWarningLevelDisplay ##2G##BCM - BCMmsg18 - C_PASDisplayFLH";
CM_ SG_ 3221225472 PDW_FrLftWrngSndSta "PDW_FrontLeftWarningSoundStatus ##2G##BCM - BCMmsg23 - C_PasSpkrFLHAlarm";
CM_ SG_ 3221225472 PDW_FrRtWrngLvlDis "PDW_FrontRightWarningLevelDisplay ##2G##BCM - BCMmsg18 - C_PASDisplayFRH";
CM_ SG_ 3221225472 PDW_FrRtWrngSndSta "PDW_FrontRightWarningSoundStatus ##2G##BCM - BCMmsg23 - C_PasSpkrFRHAlarm";
CM_ SG_ 3221225472 PDW_FrSnsrWrngLvlSta "PDW_FrontSensorWarningLevelStatus ##2G##BCM - BCMmsg18 - C_PASFsound";
CM_ SG_ 3221225472 BCM_Crc6Val "BCM_CyclicRedundancyCheck6Value";
CM_ SG_ 3221225472 BCM_AlvCnt6Val "BCM_AliveCounter6Value";
CM_ SG_ 3221225472 PDW_RrCtrWrngLvlDis "PDW_RearCenterWarningLevelDisplay ##2G##BCM - BCMmsg18 - C_PASDisplayRCTR";
CM_ SG_ 3221225472 PDW_RrCtrWrngSndSta "PDW_RearCenterWarningSoundStatus ##2G##BCM - BCMmsg23 - C_PasSpkrRCNTAlarm";
CM_ SG_ 3221225472 PDW_RrLftWrngLvlDis "PDW_RearLeftWarningLevelDisplay ##2G##BCM - BCMmsg18 - C_PASDisplayRLH";
CM_ SG_ 3221225472 PDW_RrLftWrngSndSta "PDW_RearLeftWarningSoundStatus ##2G##BCM - BCMmsg23 - C_PasSpkrRLHAlarm";
CM_ SG_ 3221225472 PDW_RrRtWrngLvlDis "PDW_RearRightWarningLevelDisplay ##2G##BCM - BCMmsg18 - C_PASDisplayRRH";
CM_ SG_ 3221225472 PDW_RrRtWrngSndSta "PDW_RearRightWarningSoundStatus ##2G##BCM - BCMmsg23 - C_PasSpkrRRHAlarm";
CM_ SG_ 3221225472 PDW_RrSnsrWrngLvlSta "PDW_RearSensorWarningLevelStatus ##2G##BCM - BCMmsg18 - C_PASRsound";
CM_ SG_ 3221225472 EPB_Crc1Val "EPB_CyclicRedundancyCheck1Value";
CM_ SG_ 3221225472 EPB_AlvCnt1Val "EPB_AliveCounter1Value";
CM_ SG_ 3221225472 EPB_LmpStaDis "EPB_LampStateDisplay ##2G##EPB - EPB11 - EPB_I_LAMP";
CM_ SG_ 3221225472 EPB_FlrLmpStaDis "EPB_FailureLampStateDisplay ##2G##EPB - EPB11 - EPB_F_LAMP";
CM_ SG_ 3221225472 EPB_OutDataDis "EPB_OutputDataDisplay ##2G##EPB - EPB11 - EPB_CLU";
CM_ SG_ 3221225472 EPB_AlrmReq "EPB_AlarmRequest ##2G##EPB - EPB11 - EPB_ALARM";
CM_ SG_ 3221225472 EPB_SwPosSta "EPB_SwitchPositionStatus ##2G##EPB - EPB11 - EPB_SWITCH";
CM_ SG_ 3221225472 EPB_RrBrkLtActvReq "EPB_RearBrakeLightActivationRequest ##2G##EPB - EPB11 - EPB_RBL";
CM_ SG_ 3221225472 EPB_FrcErrSta "EPB_ForceErrorStatus ##2G##EPB - EPB11 - EPB_FRC_ERR";
CM_ SG_ 3221225472 EPB_DynmBrkFrcReqSigSta "EPB_DynamicBrakingForceRequestSignalStatus ##2G##EPB - EPB11 - EPB_DBF_STAT";
CM_ SG_ 3221225472 EPB_FrcSta "EPB_ForceStatus ##2G##EPB - EPB11 - EPB_STATUS";
CM_ SG_ 3221225472 EPB_FlSta "EPB_FailStatus ##2G##EPB - EPB11 - EPB_FAIL";
CM_ SG_ 3221225472 EPB_EscReqAckSta "EPB_EscRequestAcknowledgeStatus ##2G##EPB - EPB11 - ESP_ACK";
CM_ SG_ 3221225472 EPB_DynmBrkFrcReq "EPB_DynamicBrakingForceRequest ##2G##EPB - EPB11 - EPB_DBF_REQ";
CM_ SG_ 3221225472 EPB_ActlFrcVal "EPB_ActualForceValue ##2G##EPB - EPB11 - EPB_FORCE";
CM_ SG_ 3221225472 EPB_DynmBrkFrcDclReq "EPB_DynamicBrakingForceDecelerationRequest ##2G##EPB - EPB11 - EPB_DBF_DECEL";
CM_ SG_ 3221225472 MFSW_Crc2Val "MFSW_CyclicRedundancyCheck2Value";
CM_ SG_ 3221225472 MFSW_AlvCnt2Val "MFSW_AliveCounter2Value";
CM_ SG_ 3221225472 Wiper_FrWiperSwSta "Wiper_FrontWiperSwitchStatus";
CM_ SG_ 3221225472 Wiper_IntStepSta "Wiper_IntermittentStepStatus";
CM_ SG_ 3221225472 Wiper_MstSwSta "Wiper_MistSwitchStatus";
CM_ SG_ 3221225472 Wiper_RrWiperSwSta "Wiper_RearWiperSwitchStatus";
CM_ SG_ 3221225472 Wiper_FrWiperWshSwSta "Wiper_FrontWiperWasherSwitchStatus";
CM_ SG_ 3221225472 Wiper_RrWiperWshSwSta "Wiper_RearWiperWasherSwitchStatus";
CM_ SG_ 3221225472 MFSW_Info "MFSW_Information_Type";
CM_ SG_ 3221225472 RCCA_Deccel_Req "RCCA_Deccel_Requirement ##2G##BCW - BCA11 - CF_RCCA_Decel_Req";
CM_ SG_ 3221225472 RCCA_BrkCmdSta "RCCA_BrakeCommandStatus ##2G##BCW - BCA11 - RCCA_Brake_Command";
CM_ SG_ 3221225472 RCCA_LftWrngSta "RCCA_LeftWarningStatus ##2G##BCW - BCA11 - CF_RCCA_WarnLh";
CM_ SG_ 3221225472 RCCA_RtWrngSta "RCCA_RightWarningStatus ##2G##BCW - BCA11 - CF_RCCA_WarnRh";
CM_ SG_ 3221225472 RCCA_FuncStat "RCCA_FunctionStatus ##2G##BCW - BCA11 - CF_RCCA_FuncState";
CM_ SG_ 3221225472 RCCA_Sta "RCCA_Status";
CM_ SG_ 3221225472 SEA_Sta "SEA_Status";
CM_ SG_ 3221225472 SEA_OnOffEquipSta "SEA_OnOffEquipmentStatus ##2G##BCW - BCW12 - CF_SEA_USM";
CM_ SG_ 3221225472 SEA_LftWrngSta "SEA_LeftWarningStatus ##2G##BCW - BCA11 - CF_SEA_Warn_Lh";
CM_ SG_ 3221225472 SEA_RtWrngSta "SEA_RightWarningStatus ##2G##BCW - BCA11 - CF_SEA_Warn_Rh";
CM_ SG_ 3221225472 RR_C_RDR_Equip "RR_C_RDR_Equip";
CM_ SG_ 3221225472 MFSW_Crc1Val "MFSW_CyclicRedundancyCheck1Value";
CM_ SG_ 3221225472 MFSW_AlvCnt1Val "MFSW_AliveCounter1Value";
CM_ SG_ 3221225472 Lamp_HdLmpHiSwSta "Lamp_HeadLampHighSwitchStatus";
CM_ SG_ 3221225472 Lamp_LtSwSta "Lamp_LightSwitchStatus";
CM_ SG_ 3221225472 Lamp_PassingLmpSwSta "Lamp_PassingLampSwitchStatus";
CM_ SG_ 3221225472 Lamp_RrFogLmpSwSta "Lamp_RearFogLampSwitchStatus";
CM_ SG_ 3221225472 Lamp_TrnSigLftSwSta "Lamp_TurnSignalLeftSwitchStatus";
CM_ SG_ 3221225472 Lamp_TrnSigRtSwSta "Lamp_TurnSignalRightSwitchStatus";
CM_ SG_ 3221225472 Lamp_LaneChgTrnSigLftSwSta "Lamp_LaneChangeTurnSignalLeftSwitchStatus";
CM_ SG_ 3221225472 Lamp_LaneChgTrnSigRtSwSta "Lamp_LaneChangeTurnSignalRightSwitchStatus";
CM_ SG_ 3221225472 RR_C_RDR_Crc1Val "RR_C_RDR_CyclicRedundancyCheck1Value";
CM_ SG_ 3221225472 RR_C_RDR_AlvCnt1Val "RR_C_RDR_AliveCounter1Value";
CM_ SG_ 3221225472 RCCW_Sta "RCCW_Status ##2G##BCW - BCW11 - CF_RCCW_Stat";
CM_ SG_ 3221225472 RCCW_OnOffEquipSt "RCCW_OnOffEquipmentStatus ##2G##BCW - BCW12 - CF_RCCW_USM";
CM_ SG_ 3221225472 RCCW_LftIndSta "RCCW_LeftIndicatorStatus ##2G##BCW - BCW11 - CF_RCCW_IndLeft";
CM_ SG_ 3221225472 RCCW_RtIndSta "RCCW_RightIndicatorStatus ##2G##BCW - BCW11 - CF_RCCW_IndRight";
CM_ SG_ 3221225472 RCCW_LftSndWrngSta "RCCW_LeftSoundWarningStatus ##2G##BCW - BCW11 - CF_RL_SndWan";
CM_ SG_ 3221225472 RCCW_RtSndWrngSta "RCCW_RightSoundWarningStatus ##2G##BCW - BCW11 - CF_RR_SndWan";
CM_ SG_ 3221225472 RCCW_LftWrngIndBriLvlVal "RCCW_LeftWarningIndicatorBrightnessLevelValue ##2G##BCW - BCW11 - CF_RCCW_IndBriLeft";
CM_ SG_ 3221225472 RCCW_RtWrngIndBriLvlVal "RCCW_RightWarningIndicatorBrightnessLevelValue ##2G##BCW - BCW11 - CF_RCCW_IndBriRight";
CM_ BO_ 1051 "[PE] Periodic and On Event";
CM_ SG_ 1051 BCM_Crc8Val "BCM_CyclicRedundancyCheck8Value";
CM_ SG_ 1051 BCM_AlvCnt8Val "BCM_AliveCounter8Value";
CM_ SG_ 1051 Lamp_HbaCtrlModTyp "Lamp_HbaControlModeType ##2G##BCM - BCMmsg22 - C_HBAControlMode";
CM_ SG_ 1051 Lamp_IFSCtrlModTyp "Lamp_IFSControlModeType ##2G##BCM - BCMmsg22 - C_IFSControlMode";
CM_ SG_ 1051 Lamp_RrFogLmpOnReq "Lamp_RearFogLampOnRequest ##2G##BCM - BCMmsg19 - C_RearFogOn";
CM_ SG_ 1051 Lamp_TailLmpWlcmCmd "Lamp_TailLampWelcomeOnCommand ##2G##BCM - BCMmsg19 - C_TailWelcomeCmd";
CM_ SG_ 1051 Lamp_HdLmpWlcmCmd "Lamp_HeadLampWelcomeOnCommand ##2G##BCM - BCMmsg19 - C_HLpWelcomeCmd";
CM_ SG_ 1051 Lamp_PuddleLmpOnReq "Lamp_PuddleLampOnRequest ##2G##BCM - BCMmsg19 - C_PuddleLpOn";
CM_ BO_ 1050 "[PE] Periodic and On Event";
CM_ SG_ 1050 BCM_Crc7Val "BCM_CyclicRedundancyCheck7Value";
CM_ SG_ 1050 BCM_AlvCnt7Val "BCM_AliveCounter7Value";
CM_ SG_ 1050 Lamp_HiPrioHzrdReq "Lamp_HighPriorityHazardRequest ##2G##BCM - BCMmsg19 - C_HazardFromBCMHigh";
CM_ SG_ 1050 Lamp_LoPrioHzrdReq "Lamp_LowPriorityHazardStatus ##2G##BCM - BCMmsg19 - C_HazardfromBCMLow";
CM_ SG_ 1050 Lamp_DedicatedDrlOnReq "Lamp_DedicatedDrlOnRequest ##2G##BCM - BCMmsg19 - C_DedicatedDRLOn";
CM_ SG_ 1050 Lamp_IntTailLmpOnReq "Lamp_InternalTailLampOnRequest ##2G##BCM - BCMmsg19 - C_IntTailOn";
CM_ SG_ 1050 Lamp_ExtrnlTailLmpOnReq "Lamp_ExternalTailLampOnRequest ##2G##BCM - BCMmsg19 - C_ExtTailOn";
CM_ SG_ 1050 Lamp_HdLmpLoOnReq "Lamp_HeadLampLowOnRequest ##2G##BCM - BCMmsg19 - C_HLpLowOn";
CM_ SG_ 1050 Lamp_HdLmpHiOnReq "Lamp_HeadLampHighOnRequest ##2G##BCM - BCMmsg19 - C_HLpHighOn";
CM_ SG_ 1050 Lamp_AvTailLmpSta "Lamp_AvTailLampStatus ##2G##BCM - BCMmsg18 - C_AvTail";
CM_ SG_ 1050 Lamp_ExtrnlLpWlcmSta "Lamp_ExternalLampWelcomeStatus ##2G##BCM - BCMmsg19 - C_ExtLampWelcomeStatus";
CM_ BO_ 1043 "[PE] Periodic and On Event";
CM_ SG_ 1043 ExtLamp_TrnSigLmpLftBlnkngSta "ExtLamp_TurnSignalLampLeftBlinkingStatus ##2G## -  - CF_Gway_TurnSigLh,C_TSigLhAct";
CM_ SG_ 1043 ExtLamp_TrnSigLmpRtBlnkngSta "ExtLamp_TurnSignalLampRightBlinkingStatus ##2G## -  - CF_Gway_TurnSigRh,C_TSigRhAct";
CM_ SG_ 1043 ExtLamp_ExtrnlTailLmpSta "ExtLamp_ExternalTailLampStatus ##2G## -  - C_ExtTailAct,CF_Gway_ExtTailAct";
CM_ SG_ 1043 ExtLamp_HzrdSwSta "ExtLamp_HazardSwitchStatus ##2G## -  - C_HazardSw,CF_Gway_HazardSw";
CM_ SG_ 1043 ExtLamp_RrFgLmpSta "ExtLamp_RearFogLampStatus ##2G## -  - C_RearFogAct,CF_Gway_RearFogAct";
CM_ SG_ 1043 IntLamp_InlTailLmpSta "IntLamp_InternalTailLampStatus ##2G## -  - C_IntTailAct,CF_Gway_IntTailAct";
CM_ SG_ 1043 Lamp_TrnSigLmpLftOnReq "Lamp_TurnSignalLampLeftOnRequest ##2G## -  - Lamp_TsigLmpFrtLftOnReq";
CM_ SG_ 1043 Lamp_TrnSigLmpRtOnReq "Lamp_TurnSignalLampRightOnRequest ##2G## -  - Lamp_TSigLmpRtLftOnReq";
BA_DEF_ BO_  "UsrMsgIDSforwardDeviation" INT 0 100;
BA_DEF_ BO_  "UsrMsgIDSbackwardDeviation" INT 50 1000;
BA_DEF_ BO_  "GenMsgCycleTime" INT 0 2000;
BA_DEF_ BO_  "GenMsgStartDelayTime" INT 0 2000;
BA_DEF_ BO_  "GenMsgSendType" ENUM  "Cyclic ","NotUsed ","NotUsed ","NotUsed ","NotUsed ","NotUsed ","NotUsed ","IfActive ","NoMsgSendType ","NotUsed","vector_leerstring";
BA_DEF_ BO_  "GenMsgCycleTimeFast" INT 0 500;
BA_DEF_ BO_  "GenMsgILSupport" ENUM  "No","Yes";
BA_DEF_ BO_  "GenMsgNrOfRepetition" INT 0 3;
BA_DEF_ BO_  "VFrameFormat" ENUM  "StandardCAN","ExtendedCAN","reserved","reserved","reserved","reserved","reserved","reserved","reserved","reserved","reserved","reserved","reserved","reserved","StandardCAN_FD","ExtendedCAN_FD";
BA_DEF_ SG_  "UserSigValidity" ENUM  "B+","ACC","IG","IG1","IG2","IG3","IG1 or IG2","IG1 or IG3","Undef";
BA_DEF_ SG_  "GenSigTimeoutTime" INT 0 7000;
BA_DEF_ SG_  "UsrSigTimeoutValue" STRING ;
BA_DEF_ SG_  "UsrSigPurpose" ENUM  "Undef","FN","DIAG","DEV","NM";
BA_DEF_ SG_  "GenSigStartValue" INT 0 1215752192;
BA_DEF_ SG_  "NetworkRequest" ENUM  "Yes","No";
BA_DEF_ SG_  "NetworkRequestHoldingTime" INT 0 65535;
BA_DEF_ SG_  "Description" STRING ;
BA_DEF_ SG_  "Version" STRING ;
BA_DEF_ SG_  "GenSigEnvVarType" ENUM  "Int","Float","Undef";
BA_DEF_ SG_  "GenSigSendType" ENUM  "Cyclic			","OnWrite			","OnWriteWithRepetition			","OnChange			","OnChangeWithRepetition			","IfActive			","IfActiveWithRepetition			","NoSigSendType			","OnChangeAndIfActive			","OnChangeAndIfActiveWithRepetition";
BA_DEF_ SG_  "GwSigLatencyTime" INT 0 65536;
BA_DEF_ SG_  "GwSigMissingSourceType" ENUM  "Undef","OldValue","DefaultValue","InitialValue";
BA_DEF_ SG_  "NWM-WakeupAllowed" ENUM  "<n.a.>";
BA_DEF_ SG_  "RoutingFactor" INT 1 1215752192;
BA_DEF_DEF_  "UsrMsgIDSforwardDeviation" 10;
BA_DEF_DEF_  "UsrMsgIDSbackwardDeviation" 100;
BA_DEF_DEF_  "GenMsgCycleTime" 200;
BA_DEF_DEF_  "GenMsgStartDelayTime" 0;
BA_DEF_DEF_  "GenMsgSendType" "NoMsgSendType ";
BA_DEF_DEF_  "GenMsgCycleTimeFast" 40;
BA_DEF_DEF_  "GenMsgILSupport" "Yes";
BA_DEF_DEF_  "GenMsgNrOfRepetition" 3;
BA_DEF_DEF_  "VFrameFormat" "StandardCAN";
BA_DEF_DEF_  "UserSigValidity" "IG";
BA_DEF_DEF_  "GenSigTimeoutTime" 500;
BA_DEF_DEF_  "UsrSigTimeoutValue" "Undef";
BA_DEF_DEF_  "UsrSigPurpose" "FN";
BA_DEF_DEF_  "GenSigStartValue" 0;
BA_DEF_DEF_  "NetworkRequest" "No";
BA_DEF_DEF_  "NetworkRequestHoldingTime" 0;
BA_DEF_DEF_  "Description" "";
BA_DEF_DEF_  "Version" "";
BA_DEF_DEF_  "GenSigEnvVarType" "Undef";
BA_DEF_DEF_  "GenSigSendType" "NoSigSendType			";
BA_DEF_DEF_  "GwSigLatencyTime" 40;
BA_DEF_DEF_  "GwSigMissingSourceType" "Undef";
BA_DEF_DEF_  "NWM-WakeupAllowed" "<n.a.>";
BA_DEF_DEF_  "RoutingFactor" 1;
BA_ "GenMsgSendType" BO_ 1051 0;
BA_ "GenMsgSendType" BO_ 1050 0;
BA_ "GenMsgSendType" BO_ 1043 0;
BA_ "Description" SG_ 3221225472 SCC_NSCCOnOffSta "This signal describes the on/off status of NSCC-Z/C/R and HDA Auto-set function. 



NSCC-Z/C/R  and HDA auto-set on/off 상태 정보";
BA_ "UserSigValidity" SG_ 3221225472 SCC_NSCCOnOffSta 3;
BA_ "GenSigTimeoutTime" SG_ 3221225472 SCC_NSCCOnOffSta 1500;
BA_ "RoutingFactor" SG_ 3221225472 SCC_NSCCOnOffSta 5;
BA_ "Version" SG_ 3221225472 SCC_NSCCOnOffSta "17.12.00";
BA_ "Description" SG_ 3221225472 SCC_ObjSta "This signal represents the state of in-path object and information of controllable state.

- 자차선상의 전방 차량 인식 여부 및 제어 가능 상태 정보";
BA_ "UserSigValidity" SG_ 3221225472 SCC_ObjSta 3;
BA_ "GenSigTimeoutTime" SG_ 3221225472 SCC_ObjSta 1500;
BA_ "RoutingFactor" SG_ 3221225472 SCC_ObjSta 5;
BA_ "Version" SG_ 3221225472 SCC_ObjSta "18.01.07";
BA_ "Description" SG_ 3221225472 SCC_SnstvtyModRetVal "This signal is SCC sensitive set mode switch info return value to cluster

- SCC 민감도 설정 관련 USM 설정 스위치 정보의 리턴 값";
BA_ "GenSigStartValue" SG_ 3221225472 SCC_SnstvtyModRetVal 2;
BA_ "UserSigValidity" SG_ 3221225472 SCC_SnstvtyModRetVal 3;
BA_ "GenSigTimeoutTime" SG_ 3221225472 SCC_SnstvtyModRetVal 1500;
BA_ "RoutingFactor" SG_ 3221225472 SCC_SnstvtyModRetVal 5;
BA_ "Version" SG_ 3221225472 SCC_SnstvtyModRetVal "17.12.00";
BA_ "UsrSigPurpose" SG_ 3221225472 APSS_GST_Byte0 2;
BA_ "GenSigSendType" SG_ 3221225472 APSS_GST_Byte0 2;
BA_ "UserSigValidity" SG_ 3221225472 APSS_GST_Byte0 0;
BA_ "GenSigTimeoutTime" SG_ 3221225472 APSS_GST_Byte0 0;
BA_ "NetworkRequest" SG_ 3221225472 APSS_GST_Byte0 0;
BA_ "NetworkRequestHoldingTime" SG_ 3221225472 APSS_GST_Byte0 5000;
BA_ "Version" SG_ 3221225472 APSS_GST_Byte0 "18.03.03";
BA_ "UsrSigPurpose" SG_ 3221225472 APSS_GST_Byte1 2;
BA_ "GenSigSendType" SG_ 3221225472 APSS_GST_Byte1 2;
BA_ "UserSigValidity" SG_ 3221225472 APSS_GST_Byte1 0;
BA_ "GenSigTimeoutTime" SG_ 3221225472 APSS_GST_Byte1 0;
BA_ "NetworkRequest" SG_ 3221225472 APSS_GST_Byte1 0;
BA_ "NetworkRequestHoldingTime" SG_ 3221225472 APSS_GST_Byte1 5000;
BA_ "Version" SG_ 3221225472 APSS_GST_Byte1 "18.03.03";
BA_ "UsrSigPurpose" SG_ 3221225472 APSS_GST_Byte2 2;
BA_ "GenSigSendType" SG_ 3221225472 APSS_GST_Byte2 2;
BA_ "UserSigValidity" SG_ 3221225472 APSS_GST_Byte2 0;
BA_ "GenSigTimeoutTime" SG_ 3221225472 APSS_GST_Byte2 0;
BA_ "NetworkRequest" SG_ 3221225472 APSS_GST_Byte2 0;
BA_ "NetworkRequestHoldingTime" SG_ 3221225472 APSS_GST_Byte2 5000;
BA_ "Version" SG_ 3221225472 APSS_GST_Byte2 "18.03.03";
BA_ "UsrSigPurpose" SG_ 3221225472 APSS_GST_Byte3 2;
BA_ "GenSigSendType" SG_ 3221225472 APSS_GST_Byte3 2;
BA_ "UserSigValidity" SG_ 3221225472 APSS_GST_Byte3 0;
BA_ "GenSigTimeoutTime" SG_ 3221225472 APSS_GST_Byte3 0;
BA_ "NetworkRequest" SG_ 3221225472 APSS_GST_Byte3 0;
BA_ "NetworkRequestHoldingTime" SG_ 3221225472 APSS_GST_Byte3 5000;
BA_ "Version" SG_ 3221225472 APSS_GST_Byte3 "18.03.03";
BA_ "UsrSigPurpose" SG_ 3221225472 APSS_GST_Byte4 2;
BA_ "GenSigSendType" SG_ 3221225472 APSS_GST_Byte4 2;
BA_ "UserSigValidity" SG_ 3221225472 APSS_GST_Byte4 0;
BA_ "GenSigTimeoutTime" SG_ 3221225472 APSS_GST_Byte4 0;
BA_ "NetworkRequest" SG_ 3221225472 APSS_GST_Byte4 0;
BA_ "NetworkRequestHoldingTime" SG_ 3221225472 APSS_GST_Byte4 5000;
BA_ "Version" SG_ 3221225472 APSS_GST_Byte4 "18.03.03";
BA_ "UsrSigPurpose" SG_ 3221225472 APSS_GST_Byte5 2;
BA_ "GenSigSendType" SG_ 3221225472 APSS_GST_Byte5 2;
BA_ "UserSigValidity" SG_ 3221225472 APSS_GST_Byte5 0;
BA_ "GenSigTimeoutTime" SG_ 3221225472 APSS_GST_Byte5 0;
BA_ "NetworkRequest" SG_ 3221225472 APSS_GST_Byte5 0;
BA_ "NetworkRequestHoldingTime" SG_ 3221225472 APSS_GST_Byte5 5000;
BA_ "Version" SG_ 3221225472 APSS_GST_Byte5 "18.03.03";
BA_ "UsrSigPurpose" SG_ 3221225472 APSS_GST_Byte6 2;
BA_ "GenSigSendType" SG_ 3221225472 APSS_GST_Byte6 2;
BA_ "UserSigValidity" SG_ 3221225472 APSS_GST_Byte6 0;
BA_ "GenSigTimeoutTime" SG_ 3221225472 APSS_GST_Byte6 0;
BA_ "NetworkRequest" SG_ 3221225472 APSS_GST_Byte6 0;
BA_ "NetworkRequestHoldingTime" SG_ 3221225472 APSS_GST_Byte6 5000;
BA_ "Version" SG_ 3221225472 APSS_GST_Byte6 "18.03.03";
BA_ "UsrSigPurpose" SG_ 3221225472 APSS_GST_Byte7 2;
BA_ "GenSigSendType" SG_ 3221225472 APSS_GST_Byte7 2;
BA_ "UserSigValidity" SG_ 3221225472 APSS_GST_Byte7 0;
BA_ "GenSigTimeoutTime" SG_ 3221225472 APSS_GST_Byte7 0;
BA_ "NetworkRequest" SG_ 3221225472 APSS_GST_Byte7 0;
BA_ "NetworkRequestHoldingTime" SG_ 3221225472 APSS_GST_Byte7 5000;
BA_ "Version" SG_ 3221225472 APSS_GST_Byte7 "18.03.03";
BA_ "UsrSigPurpose" SG_ 3221225472 eCall_GST_Byte0 2;
BA_ "GenSigSendType" SG_ 3221225472 eCall_GST_Byte0 2;
BA_ "UserSigValidity" SG_ 3221225472 eCall_GST_Byte0 0;
BA_ "GenSigTimeoutTime" SG_ 3221225472 eCall_GST_Byte0 0;
BA_ "NetworkRequest" SG_ 3221225472 eCall_GST_Byte0 0;
BA_ "NetworkRequestHoldingTime" SG_ 3221225472 eCall_GST_Byte0 5000;
BA_ "Version" SG_ 3221225472 eCall_GST_Byte0 "18.01.09";
BA_ "UsrSigPurpose" SG_ 3221225472 eCall_GST_Byte1 2;
BA_ "GenSigSendType" SG_ 3221225472 eCall_GST_Byte1 2;
BA_ "UserSigValidity" SG_ 3221225472 eCall_GST_Byte1 0;
BA_ "GenSigTimeoutTime" SG_ 3221225472 eCall_GST_Byte1 0;
BA_ "NetworkRequest" SG_ 3221225472 eCall_GST_Byte1 0;
BA_ "NetworkRequestHoldingTime" SG_ 3221225472 eCall_GST_Byte1 5000;
BA_ "Version" SG_ 3221225472 eCall_GST_Byte1 "18.01.09";
BA_ "UsrSigPurpose" SG_ 3221225472 eCall_GST_Byte2 2;
BA_ "GenSigSendType" SG_ 3221225472 eCall_GST_Byte2 2;
BA_ "UserSigValidity" SG_ 3221225472 eCall_GST_Byte2 0;
BA_ "GenSigTimeoutTime" SG_ 3221225472 eCall_GST_Byte2 0;
BA_ "NetworkRequest" SG_ 3221225472 eCall_GST_Byte2 0;
BA_ "NetworkRequestHoldingTime" SG_ 3221225472 eCall_GST_Byte2 5000;
BA_ "Version" SG_ 3221225472 eCall_GST_Byte2 "18.01.09";
BA_ "UsrSigPurpose" SG_ 3221225472 eCall_GST_Byte3 2;
BA_ "GenSigSendType" SG_ 3221225472 eCall_GST_Byte3 2;
BA_ "UserSigValidity" SG_ 3221225472 eCall_GST_Byte3 0;
BA_ "GenSigTimeoutTime" SG_ 3221225472 eCall_GST_Byte3 0;
BA_ "NetworkRequest" SG_ 3221225472 eCall_GST_Byte3 0;
BA_ "NetworkRequestHoldingTime" SG_ 3221225472 eCall_GST_Byte3 5000;
BA_ "Version" SG_ 3221225472 eCall_GST_Byte3 "18.01.09";
BA_ "UsrSigPurpose" SG_ 3221225472 eCall_GST_Byte4 2;
BA_ "GenSigSendType" SG_ 3221225472 eCall_GST_Byte4 2;
BA_ "UserSigValidity" SG_ 3221225472 eCall_GST_Byte4 0;
BA_ "GenSigTimeoutTime" SG_ 3221225472 eCall_GST_Byte4 0;
BA_ "NetworkRequest" SG_ 3221225472 eCall_GST_Byte4 0;
BA_ "NetworkRequestHoldingTime" SG_ 3221225472 eCall_GST_Byte4 5000;
BA_ "Version" SG_ 3221225472 eCall_GST_Byte4 "18.01.09";
BA_ "UsrSigPurpose" SG_ 3221225472 eCall_GST_Byte5 2;
BA_ "GenSigSendType" SG_ 3221225472 eCall_GST_Byte5 2;
BA_ "UserSigValidity" SG_ 3221225472 eCall_GST_Byte5 0;
BA_ "GenSigTimeoutTime" SG_ 3221225472 eCall_GST_Byte5 0;
BA_ "NetworkRequest" SG_ 3221225472 eCall_GST_Byte5 0;
BA_ "NetworkRequestHoldingTime" SG_ 3221225472 eCall_GST_Byte5 5000;
BA_ "Version" SG_ 3221225472 eCall_GST_Byte5 "18.01.09";
BA_ "UsrSigPurpose" SG_ 3221225472 eCall_GST_Byte6 2;
BA_ "GenSigSendType" SG_ 3221225472 eCall_GST_Byte6 2;
BA_ "UserSigValidity" SG_ 3221225472 eCall_GST_Byte6 0;
BA_ "GenSigTimeoutTime" SG_ 3221225472 eCall_GST_Byte6 0;
BA_ "NetworkRequest" SG_ 3221225472 eCall_GST_Byte6 0;
BA_ "NetworkRequestHoldingTime" SG_ 3221225472 eCall_GST_Byte6 5000;
BA_ "Version" SG_ 3221225472 eCall_GST_Byte6 "18.01.09";
BA_ "UsrSigPurpose" SG_ 3221225472 eCall_GST_Byte7 2;
BA_ "GenSigSendType" SG_ 3221225472 eCall_GST_Byte7 2;
BA_ "UserSigValidity" SG_ 3221225472 eCall_GST_Byte7 0;
BA_ "GenSigTimeoutTime" SG_ 3221225472 eCall_GST_Byte7 0;
BA_ "NetworkRequest" SG_ 3221225472 eCall_GST_Byte7 0;
BA_ "NetworkRequestHoldingTime" SG_ 3221225472 eCall_GST_Byte7 5000;
BA_ "Version" SG_ 3221225472 eCall_GST_Byte7 "18.01.09";
BA_ "Description" SG_ 3221225472 SCC_TrgtDstVal "This signal provides the target distance for SCC fallowing control.

- SCC 거리 제어를 위한 목표 차간 거리 정보";
BA_ "GenSigStartValue" SG_ 3221225472 SCC_TrgtDstVal 2047;
BA_ "UserSigValidity" SG_ 3221225472 SCC_TrgtDstVal 3;
BA_ "GenSigTimeoutTime" SG_ 3221225472 SCC_TrgtDstVal 1500;
BA_ "RoutingFactor" SG_ 3221225472 SCC_TrgtDstVal 5;
BA_ "Version" SG_ 3221225472 SCC_TrgtDstVal "18.01.07";
BA_ "Description" SG_ 3221225472 DATC_Crc5Val "The CRC checking process calculates the CRC over the entire data block, including the CRC result.

- CRC Polynomial (0x1021) , Initial Value : 0xFFFF, XOR value : 0x0000

- The mathematical expression to 16 bit CRC polynomial is given here. G(x) = x16 + ";
BA_ "GenSigSendType" SG_ 3221225472 DATC_Crc5Val 4;
BA_ "GenSigStartValue" SG_ 3221225472 DATC_Crc5Val 65535;
BA_ "UserSigValidity" SG_ 3221225472 DATC_Crc5Val 3;
BA_ "GenSigTimeoutTime" SG_ 3221225472 DATC_Crc5Val 1500;
BA_ "Version" SG_ 3221225472 DATC_Crc5Val "17.12.03";
BA_ "Description" SG_ 3221225472 DATC_AlvCnt5Val "For the first transmission request for a data element the counter shall be initialized with 0 and shall be incremented by 1

for every subsequent send request. When the counter reaches the maximum value(0xFF), then it shall restart with ? for the next se";
BA_ "GenSigSendType" SG_ 3221225472 DATC_AlvCnt5Val 4;
BA_ "UserSigValidity" SG_ 3221225472 DATC_AlvCnt5Val 3;
BA_ "GenSigTimeoutTime" SG_ 3221225472 DATC_AlvCnt5Val 1500;
BA_ "Version" SG_ 3221225472 DATC_AlvCnt5Val "17.12.03";
BA_ "Description" SG_ 3221225472 DATC_TempDispUnitSta "This signal indicates Temp unit of HTR Control (℃, ℉).";
BA_ "GenSigSendType" SG_ 3221225472 DATC_TempDispUnitSta 4;
BA_ "UserSigValidity" SG_ 3221225472 DATC_TempDispUnitSta 6;
BA_ "GenSigTimeoutTime" SG_ 3221225472 DATC_TempDispUnitSta 1500;
BA_ "Version" SG_ 3221225472 DATC_TempDispUnitSta "17.11.00";
BA_ "Description" SG_ 3221225472 DATC_IntakeSta "This signal indicates Intake status (REC or FRE).";
BA_ "GenSigSendType" SG_ 3221225472 DATC_IntakeSta 4;
BA_ "UserSigValidity" SG_ 3221225472 DATC_IntakeSta 7;
BA_ "GenSigTimeoutTime" SG_ 3221225472 DATC_IntakeSta 1500;
BA_ "Version" SG_ 3221225472 DATC_IntakeSta "17.11.00";
BA_ "Description" SG_ 3221225472 SWRC_Crc3Val "The CRC checking process calculates the CRC over the entire data block, including the CRC result CRC Polynomial (0x1D) ,

Initial Value : 0x00, XOR value : 0x00

The mathematical expression to 8 bit CRC polynomial is given here. G(x) = x8 + x4 + x3 + x2 ";
BA_ "GenSigStartValue" SG_ 3221225472 SWRC_Crc3Val 255;
BA_ "UserSigValidity" SG_ 3221225472 SWRC_Crc3Val 3;
BA_ "Version" SG_ 3221225472 SWRC_Crc3Val "17.11.00";
BA_ "Description" SG_ 3221225472 SWRC_AlvCnt3Val "For the first transmission request for a data element the counter shall be initialized with 0 and shall be incremented by 1

for every subsequent send request. When the counter reaches the maximum value(0xE), then it shall restart with ? for the next sen";
BA_ "UserSigValidity" SG_ 3221225472 SWRC_AlvCnt3Val 3;
BA_ "Version" SG_ 3221225472 SWRC_AlvCnt3Val "17.11.00";
BA_ "Description" SG_ 3221225472 SWRC_CrsSwSta "Cruise switch status

C-CAN Gateway needed";
BA_ "UserSigValidity" SG_ 3221225472 SWRC_CrsSwSta 3;
BA_ "Version" SG_ 3221225472 SWRC_CrsSwSta "18.01.00";
BA_ "Description" SG_ 3221225472 SWRC_CrsMainSwSta "Cruise on/off switch

C-CAN Gateway needed";
BA_ "UserSigValidity" SG_ 3221225472 SWRC_CrsMainSwSta 3;
BA_ "Version" SG_ 3221225472 SWRC_CrsMainSwSta "17.11.00";
BA_ "Description" SG_ 3221225472 SWRC_LFASwSta "LFA on/off switch

C-CAN Gateway needed";
BA_ "UserSigValidity" SG_ 3221225472 SWRC_LFASwSta 3;
BA_ "Version" SG_ 3221225472 SWRC_LFASwSta "17.11.00";
BA_ "Description" SG_ 3221225472 SWRC_PaddleUpSwSta "Paddle Up switch

C-CAN Gateway needed";
BA_ "UserSigValidity" SG_ 3221225472 SWRC_PaddleUpSwSta 3;
BA_ "Version" SG_ 3221225472 SWRC_PaddleUpSwSta "17.11.00";
BA_ "Description" SG_ 3221225472 SWRC_PaddleDnSwSta "Paddle Down switch

C-CAN Gateway needed";
BA_ "UserSigValidity" SG_ 3221225472 SWRC_PaddleDnSwSta 3;
BA_ "Version" SG_ 3221225472 SWRC_PaddleDnSwSta "17.11.00";
BA_ "Description" SG_ 3221225472 SWRC_Info "Steering Wheel Remocon switch information 

This signal is used to determine 'CAN type SWRX' is applied or not in this vehicle.



0x0 : CAN type SWRC is Not Applied

0x1 : CAN type SWRC Applied";
BA_ "UserSigValidity" SG_ 3221225472 SWRC_Info 3;
BA_ "Version" SG_ 3221225472 SWRC_Info "17.11.00";
BA_ "UsrSigPurpose" SG_ 3221225472 GST_SCM_Byte0 2;
BA_ "GenSigSendType" SG_ 3221225472 GST_SCM_Byte0 2;
BA_ "UserSigValidity" SG_ 3221225472 GST_SCM_Byte0 0;
BA_ "GenSigTimeoutTime" SG_ 3221225472 GST_SCM_Byte0 0;
BA_ "NetworkRequest" SG_ 3221225472 GST_SCM_Byte0 0;
BA_ "NetworkRequestHoldingTime" SG_ 3221225472 GST_SCM_Byte0 5000;
BA_ "Version" SG_ 3221225472 GST_SCM_Byte0 "18.01.09";
BA_ "UsrSigPurpose" SG_ 3221225472 GST_SCM_Byte1 2;
BA_ "GenSigSendType" SG_ 3221225472 GST_SCM_Byte1 2;
BA_ "UserSigValidity" SG_ 3221225472 GST_SCM_Byte1 0;
BA_ "GenSigTimeoutTime" SG_ 3221225472 GST_SCM_Byte1 0;
BA_ "NetworkRequest" SG_ 3221225472 GST_SCM_Byte1 0;
BA_ "NetworkRequestHoldingTime" SG_ 3221225472 GST_SCM_Byte1 5000;
BA_ "Version" SG_ 3221225472 GST_SCM_Byte1 "18.01.09";
BA_ "UsrSigPurpose" SG_ 3221225472 GST_SCM_Byte2 2;
BA_ "GenSigSendType" SG_ 3221225472 GST_SCM_Byte2 2;
BA_ "UserSigValidity" SG_ 3221225472 GST_SCM_Byte2 0;
BA_ "GenSigTimeoutTime" SG_ 3221225472 GST_SCM_Byte2 0;
BA_ "NetworkRequest" SG_ 3221225472 GST_SCM_Byte2 0;
BA_ "NetworkRequestHoldingTime" SG_ 3221225472 GST_SCM_Byte2 5000;
BA_ "Version" SG_ 3221225472 GST_SCM_Byte2 "18.01.09";
BA_ "UsrSigPurpose" SG_ 3221225472 GST_SCM_Byte3 2;
BA_ "GenSigSendType" SG_ 3221225472 GST_SCM_Byte3 2;
BA_ "UserSigValidity" SG_ 3221225472 GST_SCM_Byte3 0;
BA_ "GenSigTimeoutTime" SG_ 3221225472 GST_SCM_Byte3 0;
BA_ "NetworkRequest" SG_ 3221225472 GST_SCM_Byte3 0;
BA_ "NetworkRequestHoldingTime" SG_ 3221225472 GST_SCM_Byte3 5000;
BA_ "Version" SG_ 3221225472 GST_SCM_Byte3 "18.01.09";
BA_ "UsrSigPurpose" SG_ 3221225472 GST_SCM_Byte4 2;
BA_ "GenSigSendType" SG_ 3221225472 GST_SCM_Byte4 2;
BA_ "UserSigValidity" SG_ 3221225472 GST_SCM_Byte4 0;
BA_ "GenSigTimeoutTime" SG_ 3221225472 GST_SCM_Byte4 0;
BA_ "NetworkRequest" SG_ 3221225472 GST_SCM_Byte4 0;
BA_ "NetworkRequestHoldingTime" SG_ 3221225472 GST_SCM_Byte4 5000;
BA_ "Version" SG_ 3221225472 GST_SCM_Byte4 "18.01.09";
BA_ "UsrSigPurpose" SG_ 3221225472 GST_SCM_Byte5 2;
BA_ "GenSigSendType" SG_ 3221225472 GST_SCM_Byte5 2;
BA_ "UserSigValidity" SG_ 3221225472 GST_SCM_Byte5 0;
BA_ "GenSigTimeoutTime" SG_ 3221225472 GST_SCM_Byte5 0;
BA_ "NetworkRequest" SG_ 3221225472 GST_SCM_Byte5 0;
BA_ "NetworkRequestHoldingTime" SG_ 3221225472 GST_SCM_Byte5 5000;
BA_ "Version" SG_ 3221225472 GST_SCM_Byte5 "18.01.09";
BA_ "UsrSigPurpose" SG_ 3221225472 GST_SCM_Byte6 2;
BA_ "GenSigSendType" SG_ 3221225472 GST_SCM_Byte6 2;
BA_ "UserSigValidity" SG_ 3221225472 GST_SCM_Byte6 0;
BA_ "GenSigTimeoutTime" SG_ 3221225472 GST_SCM_Byte6 0;
BA_ "NetworkRequest" SG_ 3221225472 GST_SCM_Byte6 0;
BA_ "NetworkRequestHoldingTime" SG_ 3221225472 GST_SCM_Byte6 5000;
BA_ "Version" SG_ 3221225472 GST_SCM_Byte6 "18.01.09";
BA_ "UsrSigPurpose" SG_ 3221225472 GST_SCM_Byte7 2;
BA_ "GenSigSendType" SG_ 3221225472 GST_SCM_Byte7 2;
BA_ "UserSigValidity" SG_ 3221225472 GST_SCM_Byte7 0;
BA_ "GenSigTimeoutTime" SG_ 3221225472 GST_SCM_Byte7 0;
BA_ "NetworkRequest" SG_ 3221225472 GST_SCM_Byte7 0;
BA_ "NetworkRequestHoldingTime" SG_ 3221225472 GST_SCM_Byte7 5000;
BA_ "Version" SG_ 3221225472 GST_SCM_Byte7 "18.01.09";
BA_ "UsrSigPurpose" SG_ 3221225472 GST_SWRC_Byte0 2;
BA_ "GenSigSendType" SG_ 3221225472 GST_SWRC_Byte0 2;
BA_ "UserSigValidity" SG_ 3221225472 GST_SWRC_Byte0 0;
BA_ "GenSigTimeoutTime" SG_ 3221225472 GST_SWRC_Byte0 0;
BA_ "NetworkRequest" SG_ 3221225472 GST_SWRC_Byte0 0;
BA_ "NetworkRequestHoldingTime" SG_ 3221225472 GST_SWRC_Byte0 5000;
BA_ "Version" SG_ 3221225472 GST_SWRC_Byte0 "18.01.09";
BA_ "UsrSigPurpose" SG_ 3221225472 GST_SWRC_Byte1 2;
BA_ "GenSigSendType" SG_ 3221225472 GST_SWRC_Byte1 2;
BA_ "UserSigValidity" SG_ 3221225472 GST_SWRC_Byte1 0;
BA_ "GenSigTimeoutTime" SG_ 3221225472 GST_SWRC_Byte1 0;
BA_ "NetworkRequest" SG_ 3221225472 GST_SWRC_Byte1 0;
BA_ "NetworkRequestHoldingTime" SG_ 3221225472 GST_SWRC_Byte1 5000;
BA_ "Version" SG_ 3221225472 GST_SWRC_Byte1 "18.01.09";
BA_ "UsrSigPurpose" SG_ 3221225472 GST_SWRC_Byte2 2;
BA_ "GenSigSendType" SG_ 3221225472 GST_SWRC_Byte2 2;
BA_ "UserSigValidity" SG_ 3221225472 GST_SWRC_Byte2 0;
BA_ "GenSigTimeoutTime" SG_ 3221225472 GST_SWRC_Byte2 0;
BA_ "NetworkRequest" SG_ 3221225472 GST_SWRC_Byte2 0;
BA_ "NetworkRequestHoldingTime" SG_ 3221225472 GST_SWRC_Byte2 5000;
BA_ "Version" SG_ 3221225472 GST_SWRC_Byte2 "18.01.09";
BA_ "UsrSigPurpose" SG_ 3221225472 GST_SWRC_Byte3 2;
BA_ "GenSigSendType" SG_ 3221225472 GST_SWRC_Byte3 2;
BA_ "UserSigValidity" SG_ 3221225472 GST_SWRC_Byte3 0;
BA_ "GenSigTimeoutTime" SG_ 3221225472 GST_SWRC_Byte3 0;
BA_ "NetworkRequest" SG_ 3221225472 GST_SWRC_Byte3 0;
BA_ "NetworkRequestHoldingTime" SG_ 3221225472 GST_SWRC_Byte3 5000;
BA_ "Version" SG_ 3221225472 GST_SWRC_Byte3 "18.01.09";
BA_ "UsrSigPurpose" SG_ 3221225472 GST_SWRC_Byte4 2;
BA_ "GenSigSendType" SG_ 3221225472 GST_SWRC_Byte4 2;
BA_ "UserSigValidity" SG_ 3221225472 GST_SWRC_Byte4 0;
BA_ "GenSigTimeoutTime" SG_ 3221225472 GST_SWRC_Byte4 0;
BA_ "NetworkRequest" SG_ 3221225472 GST_SWRC_Byte4 0;
BA_ "NetworkRequestHoldingTime" SG_ 3221225472 GST_SWRC_Byte4 5000;
BA_ "Version" SG_ 3221225472 GST_SWRC_Byte4 "18.01.09";
BA_ "UsrSigPurpose" SG_ 3221225472 GST_SWRC_Byte5 2;
BA_ "GenSigSendType" SG_ 3221225472 GST_SWRC_Byte5 2;
BA_ "UserSigValidity" SG_ 3221225472 GST_SWRC_Byte5 0;
BA_ "GenSigTimeoutTime" SG_ 3221225472 GST_SWRC_Byte5 0;
BA_ "NetworkRequest" SG_ 3221225472 GST_SWRC_Byte5 0;
BA_ "NetworkRequestHoldingTime" SG_ 3221225472 GST_SWRC_Byte5 5000;
BA_ "Version" SG_ 3221225472 GST_SWRC_Byte5 "18.01.09";
BA_ "UsrSigPurpose" SG_ 3221225472 GST_SWRC_Byte6 2;
BA_ "GenSigSendType" SG_ 3221225472 GST_SWRC_Byte6 2;
BA_ "UserSigValidity" SG_ 3221225472 GST_SWRC_Byte6 0;
BA_ "GenSigTimeoutTime" SG_ 3221225472 GST_SWRC_Byte6 0;
BA_ "NetworkRequest" SG_ 3221225472 GST_SWRC_Byte6 0;
BA_ "NetworkRequestHoldingTime" SG_ 3221225472 GST_SWRC_Byte6 5000;
BA_ "Version" SG_ 3221225472 GST_SWRC_Byte6 "18.01.09";
BA_ "UsrSigPurpose" SG_ 3221225472 GST_SWRC_Byte7 2;
BA_ "GenSigSendType" SG_ 3221225472 GST_SWRC_Byte7 2;
BA_ "UserSigValidity" SG_ 3221225472 GST_SWRC_Byte7 0;
BA_ "GenSigTimeoutTime" SG_ 3221225472 GST_SWRC_Byte7 0;
BA_ "NetworkRequest" SG_ 3221225472 GST_SWRC_Byte7 0;
BA_ "NetworkRequestHoldingTime" SG_ 3221225472 GST_SWRC_Byte7 5000;
BA_ "Version" SG_ 3221225472 GST_SWRC_Byte7 "18.01.09";
BA_ "UsrSigPurpose" SG_ 3221225472 GST_MFSW_Byte0 2;
BA_ "GenSigSendType" SG_ 3221225472 GST_MFSW_Byte0 2;
BA_ "UserSigValidity" SG_ 3221225472 GST_MFSW_Byte0 0;
BA_ "GenSigTimeoutTime" SG_ 3221225472 GST_MFSW_Byte0 0;
BA_ "NetworkRequest" SG_ 3221225472 GST_MFSW_Byte0 0;
BA_ "NetworkRequestHoldingTime" SG_ 3221225472 GST_MFSW_Byte0 5000;
BA_ "Version" SG_ 3221225472 GST_MFSW_Byte0 "18.01.09";
BA_ "UsrSigPurpose" SG_ 3221225472 GST_MFSW_Byte1 2;
BA_ "GenSigSendType" SG_ 3221225472 GST_MFSW_Byte1 2;
BA_ "UserSigValidity" SG_ 3221225472 GST_MFSW_Byte1 0;
BA_ "GenSigTimeoutTime" SG_ 3221225472 GST_MFSW_Byte1 0;
BA_ "NetworkRequest" SG_ 3221225472 GST_MFSW_Byte1 0;
BA_ "NetworkRequestHoldingTime" SG_ 3221225472 GST_MFSW_Byte1 5000;
BA_ "Version" SG_ 3221225472 GST_MFSW_Byte1 "18.01.09";
BA_ "UsrSigPurpose" SG_ 3221225472 GST_MFSW_Byte2 2;
BA_ "GenSigSendType" SG_ 3221225472 GST_MFSW_Byte2 2;
BA_ "UserSigValidity" SG_ 3221225472 GST_MFSW_Byte2 0;
BA_ "GenSigTimeoutTime" SG_ 3221225472 GST_MFSW_Byte2 0;
BA_ "NetworkRequest" SG_ 3221225472 GST_MFSW_Byte2 0;
BA_ "NetworkRequestHoldingTime" SG_ 3221225472 GST_MFSW_Byte2 5000;
BA_ "Version" SG_ 3221225472 GST_MFSW_Byte2 "18.01.09";
BA_ "UsrSigPurpose" SG_ 3221225472 GST_MFSW_Byte3 2;
BA_ "GenSigSendType" SG_ 3221225472 GST_MFSW_Byte3 2;
BA_ "UserSigValidity" SG_ 3221225472 GST_MFSW_Byte3 0;
BA_ "GenSigTimeoutTime" SG_ 3221225472 GST_MFSW_Byte3 0;
BA_ "NetworkRequest" SG_ 3221225472 GST_MFSW_Byte3 0;
BA_ "NetworkRequestHoldingTime" SG_ 3221225472 GST_MFSW_Byte3 5000;
BA_ "Version" SG_ 3221225472 GST_MFSW_Byte3 "18.01.09";
BA_ "UsrSigPurpose" SG_ 3221225472 GST_MFSW_Byte4 2;
BA_ "GenSigSendType" SG_ 3221225472 GST_MFSW_Byte4 2;
BA_ "UserSigValidity" SG_ 3221225472 GST_MFSW_Byte4 0;
BA_ "GenSigTimeoutTime" SG_ 3221225472 GST_MFSW_Byte4 0;
BA_ "NetworkRequest" SG_ 3221225472 GST_MFSW_Byte4 0;
BA_ "NetworkRequestHoldingTime" SG_ 3221225472 GST_MFSW_Byte4 5000;
BA_ "Version" SG_ 3221225472 GST_MFSW_Byte4 "18.01.09";
BA_ "UsrSigPurpose" SG_ 3221225472 GST_MFSW_Byte5 2;
BA_ "GenSigSendType" SG_ 3221225472 GST_MFSW_Byte5 2;
BA_ "UserSigValidity" SG_ 3221225472 GST_MFSW_Byte5 0;
BA_ "GenSigTimeoutTime" SG_ 3221225472 GST_MFSW_Byte5 0;
BA_ "NetworkRequest" SG_ 3221225472 GST_MFSW_Byte5 0;
BA_ "NetworkRequestHoldingTime" SG_ 3221225472 GST_MFSW_Byte5 5000;
BA_ "Version" SG_ 3221225472 GST_MFSW_Byte5 "18.01.09";
BA_ "UsrSigPurpose" SG_ 3221225472 GST_MFSW_Byte6 2;
BA_ "GenSigSendType" SG_ 3221225472 GST_MFSW_Byte6 2;
BA_ "UserSigValidity" SG_ 3221225472 GST_MFSW_Byte6 0;
BA_ "GenSigTimeoutTime" SG_ 3221225472 GST_MFSW_Byte6 0;
BA_ "NetworkRequest" SG_ 3221225472 GST_MFSW_Byte6 0;
BA_ "NetworkRequestHoldingTime" SG_ 3221225472 GST_MFSW_Byte6 5000;
BA_ "Version" SG_ 3221225472 GST_MFSW_Byte6 "18.01.09";
BA_ "UsrSigPurpose" SG_ 3221225472 GST_MFSW_Byte7 2;
BA_ "GenSigSendType" SG_ 3221225472 GST_MFSW_Byte7 2;
BA_ "UserSigValidity" SG_ 3221225472 GST_MFSW_Byte7 0;
BA_ "GenSigTimeoutTime" SG_ 3221225472 GST_MFSW_Byte7 0;
BA_ "NetworkRequest" SG_ 3221225472 GST_MFSW_Byte7 0;
BA_ "NetworkRequestHoldingTime" SG_ 3221225472 GST_MFSW_Byte7 5000;
BA_ "Version" SG_ 3221225472 GST_MFSW_Byte7 "18.01.09";
BA_ "UsrSigPurpose" SG_ 3221225472 GST_DAU_Byte0 2;
BA_ "GenSigSendType" SG_ 3221225472 GST_DAU_Byte0 2;
BA_ "UserSigValidity" SG_ 3221225472 GST_DAU_Byte0 0;
BA_ "GenSigTimeoutTime" SG_ 3221225472 GST_DAU_Byte0 0;
BA_ "NetworkRequest" SG_ 3221225472 GST_DAU_Byte0 0;
BA_ "NetworkRequestHoldingTime" SG_ 3221225472 GST_DAU_Byte0 5000;
BA_ "Version" SG_ 3221225472 GST_DAU_Byte0 "18.01.09";
BA_ "UsrSigPurpose" SG_ 3221225472 GST_DAU_Byte1 2;
BA_ "GenSigSendType" SG_ 3221225472 GST_DAU_Byte1 2;
BA_ "UserSigValidity" SG_ 3221225472 GST_DAU_Byte1 0;
BA_ "GenSigTimeoutTime" SG_ 3221225472 GST_DAU_Byte1 0;
BA_ "NetworkRequest" SG_ 3221225472 GST_DAU_Byte1 0;
BA_ "NetworkRequestHoldingTime" SG_ 3221225472 GST_DAU_Byte1 5000;
BA_ "Version" SG_ 3221225472 GST_DAU_Byte1 "18.01.09";
BA_ "UsrSigPurpose" SG_ 3221225472 GST_DAU_Byte2 2;
BA_ "GenSigSendType" SG_ 3221225472 GST_DAU_Byte2 2;
BA_ "UserSigValidity" SG_ 3221225472 GST_DAU_Byte2 0;
BA_ "GenSigTimeoutTime" SG_ 3221225472 GST_DAU_Byte2 0;
BA_ "NetworkRequest" SG_ 3221225472 GST_DAU_Byte2 0;
BA_ "NetworkRequestHoldingTime" SG_ 3221225472 GST_DAU_Byte2 5000;
BA_ "Version" SG_ 3221225472 GST_DAU_Byte2 "18.01.09";
BA_ "UsrSigPurpose" SG_ 3221225472 GST_DAU_Byte3 2;
BA_ "GenSigSendType" SG_ 3221225472 GST_DAU_Byte3 2;
BA_ "UserSigValidity" SG_ 3221225472 GST_DAU_Byte3 0;
BA_ "GenSigTimeoutTime" SG_ 3221225472 GST_DAU_Byte3 0;
BA_ "NetworkRequest" SG_ 3221225472 GST_DAU_Byte3 0;
BA_ "NetworkRequestHoldingTime" SG_ 3221225472 GST_DAU_Byte3 5000;
BA_ "Version" SG_ 3221225472 GST_DAU_Byte3 "18.01.09";
BA_ "UsrSigPurpose" SG_ 3221225472 GST_DAU_Byte4 2;
BA_ "GenSigSendType" SG_ 3221225472 GST_DAU_Byte4 2;
BA_ "UserSigValidity" SG_ 3221225472 GST_DAU_Byte4 0;
BA_ "GenSigTimeoutTime" SG_ 3221225472 GST_DAU_Byte4 0;
BA_ "NetworkRequest" SG_ 3221225472 GST_DAU_Byte4 0;
BA_ "NetworkRequestHoldingTime" SG_ 3221225472 GST_DAU_Byte4 5000;
BA_ "Version" SG_ 3221225472 GST_DAU_Byte4 "18.01.09";
BA_ "UsrSigPurpose" SG_ 3221225472 GST_DAU_Byte5 2;
BA_ "GenSigSendType" SG_ 3221225472 GST_DAU_Byte5 2;
BA_ "UserSigValidity" SG_ 3221225472 GST_DAU_Byte5 0;
BA_ "GenSigTimeoutTime" SG_ 3221225472 GST_DAU_Byte5 0;
BA_ "NetworkRequest" SG_ 3221225472 GST_DAU_Byte5 0;
BA_ "NetworkRequestHoldingTime" SG_ 3221225472 GST_DAU_Byte5 5000;
BA_ "Version" SG_ 3221225472 GST_DAU_Byte5 "18.01.09";
BA_ "UsrSigPurpose" SG_ 3221225472 GST_DAU_Byte6 2;
BA_ "GenSigSendType" SG_ 3221225472 GST_DAU_Byte6 2;
BA_ "UserSigValidity" SG_ 3221225472 GST_DAU_Byte6 0;
BA_ "GenSigTimeoutTime" SG_ 3221225472 GST_DAU_Byte6 0;
BA_ "NetworkRequest" SG_ 3221225472 GST_DAU_Byte6 0;
BA_ "NetworkRequestHoldingTime" SG_ 3221225472 GST_DAU_Byte6 5000;
BA_ "Version" SG_ 3221225472 GST_DAU_Byte6 "18.01.09";
BA_ "UsrSigPurpose" SG_ 3221225472 GST_DAU_Byte7 2;
BA_ "GenSigSendType" SG_ 3221225472 GST_DAU_Byte7 2;
BA_ "UserSigValidity" SG_ 3221225472 GST_DAU_Byte7 0;
BA_ "GenSigTimeoutTime" SG_ 3221225472 GST_DAU_Byte7 0;
BA_ "NetworkRequest" SG_ 3221225472 GST_DAU_Byte7 0;
BA_ "NetworkRequestHoldingTime" SG_ 3221225472 GST_DAU_Byte7 5000;
BA_ "Version" SG_ 3221225472 GST_DAU_Byte7 "18.01.09";
BA_ "UsrSigPurpose" SG_ 3221225472 GST_IBU_HS_Byte0 2;
BA_ "GenSigSendType" SG_ 3221225472 GST_IBU_HS_Byte0 2;
BA_ "UserSigValidity" SG_ 3221225472 GST_IBU_HS_Byte0 0;
BA_ "GenSigTimeoutTime" SG_ 3221225472 GST_IBU_HS_Byte0 0;
BA_ "NetworkRequest" SG_ 3221225472 GST_IBU_HS_Byte0 0;
BA_ "NetworkRequestHoldingTime" SG_ 3221225472 GST_IBU_HS_Byte0 5000;
BA_ "Version" SG_ 3221225472 GST_IBU_HS_Byte0 "18.01.09";
BA_ "UsrSigPurpose" SG_ 3221225472 GST_IBU_HS_Byte1 2;
BA_ "GenSigSendType" SG_ 3221225472 GST_IBU_HS_Byte1 2;
BA_ "UserSigValidity" SG_ 3221225472 GST_IBU_HS_Byte1 0;
BA_ "GenSigTimeoutTime" SG_ 3221225472 GST_IBU_HS_Byte1 0;
BA_ "NetworkRequest" SG_ 3221225472 GST_IBU_HS_Byte1 0;
BA_ "NetworkRequestHoldingTime" SG_ 3221225472 GST_IBU_HS_Byte1 5000;
BA_ "Version" SG_ 3221225472 GST_IBU_HS_Byte1 "18.01.09";
BA_ "UsrSigPurpose" SG_ 3221225472 GST_IBU_HS_Byte2 2;
BA_ "GenSigSendType" SG_ 3221225472 GST_IBU_HS_Byte2 2;
BA_ "UserSigValidity" SG_ 3221225472 GST_IBU_HS_Byte2 0;
BA_ "GenSigTimeoutTime" SG_ 3221225472 GST_IBU_HS_Byte2 0;
BA_ "NetworkRequest" SG_ 3221225472 GST_IBU_HS_Byte2 0;
BA_ "NetworkRequestHoldingTime" SG_ 3221225472 GST_IBU_HS_Byte2 5000;
BA_ "Version" SG_ 3221225472 GST_IBU_HS_Byte2 "18.01.09";
BA_ "UsrSigPurpose" SG_ 3221225472 GST_IBU_HS_Byte3 2;
BA_ "GenSigSendType" SG_ 3221225472 GST_IBU_HS_Byte3 2;
BA_ "UserSigValidity" SG_ 3221225472 GST_IBU_HS_Byte3 0;
BA_ "GenSigTimeoutTime" SG_ 3221225472 GST_IBU_HS_Byte3 0;
BA_ "NetworkRequest" SG_ 3221225472 GST_IBU_HS_Byte3 0;
BA_ "NetworkRequestHoldingTime" SG_ 3221225472 GST_IBU_HS_Byte3 5000;
BA_ "Version" SG_ 3221225472 GST_IBU_HS_Byte3 "18.01.09";
BA_ "UsrSigPurpose" SG_ 3221225472 GST_IBU_HS_Byte4 2;
BA_ "GenSigSendType" SG_ 3221225472 GST_IBU_HS_Byte4 2;
BA_ "UserSigValidity" SG_ 3221225472 GST_IBU_HS_Byte4 0;
BA_ "GenSigTimeoutTime" SG_ 3221225472 GST_IBU_HS_Byte4 0;
BA_ "NetworkRequest" SG_ 3221225472 GST_IBU_HS_Byte4 0;
BA_ "NetworkRequestHoldingTime" SG_ 3221225472 GST_IBU_HS_Byte4 5000;
BA_ "Version" SG_ 3221225472 GST_IBU_HS_Byte4 "18.01.09";
BA_ "UsrSigPurpose" SG_ 3221225472 GST_IBU_HS_Byte5 2;
BA_ "GenSigSendType" SG_ 3221225472 GST_IBU_HS_Byte5 2;
BA_ "UserSigValidity" SG_ 3221225472 GST_IBU_HS_Byte5 0;
BA_ "GenSigTimeoutTime" SG_ 3221225472 GST_IBU_HS_Byte5 0;
BA_ "NetworkRequest" SG_ 3221225472 GST_IBU_HS_Byte5 0;
BA_ "NetworkRequestHoldingTime" SG_ 3221225472 GST_IBU_HS_Byte5 5000;
BA_ "Version" SG_ 3221225472 GST_IBU_HS_Byte5 "18.01.09";
BA_ "UsrSigPurpose" SG_ 3221225472 GST_IBU_HS_Byte6 2;
BA_ "GenSigSendType" SG_ 3221225472 GST_IBU_HS_Byte6 2;
BA_ "UserSigValidity" SG_ 3221225472 GST_IBU_HS_Byte6 0;
BA_ "GenSigTimeoutTime" SG_ 3221225472 GST_IBU_HS_Byte6 0;
BA_ "NetworkRequest" SG_ 3221225472 GST_IBU_HS_Byte6 0;
BA_ "NetworkRequestHoldingTime" SG_ 3221225472 GST_IBU_HS_Byte6 5000;
BA_ "Version" SG_ 3221225472 GST_IBU_HS_Byte6 "18.01.09";
BA_ "UsrSigPurpose" SG_ 3221225472 GST_IBU_HS_Byte7 2;
BA_ "GenSigSendType" SG_ 3221225472 GST_IBU_HS_Byte7 2;
BA_ "UserSigValidity" SG_ 3221225472 GST_IBU_HS_Byte7 0;
BA_ "GenSigTimeoutTime" SG_ 3221225472 GST_IBU_HS_Byte7 0;
BA_ "NetworkRequest" SG_ 3221225472 GST_IBU_HS_Byte7 0;
BA_ "NetworkRequestHoldingTime" SG_ 3221225472 GST_IBU_HS_Byte7 5000;
BA_ "Version" SG_ 3221225472 GST_IBU_HS_Byte7 "18.01.09";
BA_ "UsrSigPurpose" SG_ 3221225472 GST_PSM_PSU_Byte0 2;
BA_ "GenSigSendType" SG_ 3221225472 GST_PSM_PSU_Byte0 2;
BA_ "UserSigValidity" SG_ 3221225472 GST_PSM_PSU_Byte0 0;
BA_ "GenSigTimeoutTime" SG_ 3221225472 GST_PSM_PSU_Byte0 0;
BA_ "NetworkRequest" SG_ 3221225472 GST_PSM_PSU_Byte0 0;
BA_ "NetworkRequestHoldingTime" SG_ 3221225472 GST_PSM_PSU_Byte0 5000;
BA_ "Version" SG_ 3221225472 GST_PSM_PSU_Byte0 "18.01.09";
BA_ "UsrSigPurpose" SG_ 3221225472 GST_PSM_PSU_Byte1 2;
BA_ "GenSigSendType" SG_ 3221225472 GST_PSM_PSU_Byte1 2;
BA_ "UserSigValidity" SG_ 3221225472 GST_PSM_PSU_Byte1 0;
BA_ "GenSigTimeoutTime" SG_ 3221225472 GST_PSM_PSU_Byte1 0;
BA_ "NetworkRequest" SG_ 3221225472 GST_PSM_PSU_Byte1 0;
BA_ "NetworkRequestHoldingTime" SG_ 3221225472 GST_PSM_PSU_Byte1 5000;
BA_ "Version" SG_ 3221225472 GST_PSM_PSU_Byte1 "18.01.09";
BA_ "UsrSigPurpose" SG_ 3221225472 GST_PSM_PSU_Byte2 2;
BA_ "GenSigSendType" SG_ 3221225472 GST_PSM_PSU_Byte2 2;
BA_ "UserSigValidity" SG_ 3221225472 GST_PSM_PSU_Byte2 0;
BA_ "GenSigTimeoutTime" SG_ 3221225472 GST_PSM_PSU_Byte2 0;
BA_ "NetworkRequest" SG_ 3221225472 GST_PSM_PSU_Byte2 0;
BA_ "NetworkRequestHoldingTime" SG_ 3221225472 GST_PSM_PSU_Byte2 5000;
BA_ "Version" SG_ 3221225472 GST_PSM_PSU_Byte2 "18.01.09";
BA_ "UsrSigPurpose" SG_ 3221225472 GST_PSM_PSU_Byte3 2;
BA_ "GenSigSendType" SG_ 3221225472 GST_PSM_PSU_Byte3 2;
BA_ "UserSigValidity" SG_ 3221225472 GST_PSM_PSU_Byte3 0;
BA_ "GenSigTimeoutTime" SG_ 3221225472 GST_PSM_PSU_Byte3 0;
BA_ "NetworkRequest" SG_ 3221225472 GST_PSM_PSU_Byte3 0;
BA_ "NetworkRequestHoldingTime" SG_ 3221225472 GST_PSM_PSU_Byte3 5000;
BA_ "Version" SG_ 3221225472 GST_PSM_PSU_Byte3 "18.01.09";
BA_ "UsrSigPurpose" SG_ 3221225472 GST_PSM_PSU_Byte4 2;
BA_ "GenSigSendType" SG_ 3221225472 GST_PSM_PSU_Byte4 2;
BA_ "UserSigValidity" SG_ 3221225472 GST_PSM_PSU_Byte4 0;
BA_ "GenSigTimeoutTime" SG_ 3221225472 GST_PSM_PSU_Byte4 0;
BA_ "NetworkRequest" SG_ 3221225472 GST_PSM_PSU_Byte4 0;
BA_ "NetworkRequestHoldingTime" SG_ 3221225472 GST_PSM_PSU_Byte4 5000;
BA_ "Version" SG_ 3221225472 GST_PSM_PSU_Byte4 "18.01.09";
BA_ "UsrSigPurpose" SG_ 3221225472 GST_PSM_PSU_Byte5 2;
BA_ "GenSigSendType" SG_ 3221225472 GST_PSM_PSU_Byte5 2;
BA_ "UserSigValidity" SG_ 3221225472 GST_PSM_PSU_Byte5 0;
BA_ "GenSigTimeoutTime" SG_ 3221225472 GST_PSM_PSU_Byte5 0;
BA_ "NetworkRequest" SG_ 3221225472 GST_PSM_PSU_Byte5 0;
BA_ "NetworkRequestHoldingTime" SG_ 3221225472 GST_PSM_PSU_Byte5 5000;
BA_ "Version" SG_ 3221225472 GST_PSM_PSU_Byte5 "18.01.09";
BA_ "UsrSigPurpose" SG_ 3221225472 GST_PSM_PSU_Byte6 2;
BA_ "GenSigSendType" SG_ 3221225472 GST_PSM_PSU_Byte6 2;
BA_ "UserSigValidity" SG_ 3221225472 GST_PSM_PSU_Byte6 0;
BA_ "GenSigTimeoutTime" SG_ 3221225472 GST_PSM_PSU_Byte6 0;
BA_ "NetworkRequest" SG_ 3221225472 GST_PSM_PSU_Byte6 0;
BA_ "NetworkRequestHoldingTime" SG_ 3221225472 GST_PSM_PSU_Byte6 5000;
BA_ "Version" SG_ 3221225472 GST_PSM_PSU_Byte6 "18.01.09";
BA_ "UsrSigPurpose" SG_ 3221225472 GST_PSM_PSU_Byte7 2;
BA_ "GenSigSendType" SG_ 3221225472 GST_PSM_PSU_Byte7 2;
BA_ "UserSigValidity" SG_ 3221225472 GST_PSM_PSU_Byte7 0;
BA_ "GenSigTimeoutTime" SG_ 3221225472 GST_PSM_PSU_Byte7 0;
BA_ "NetworkRequest" SG_ 3221225472 GST_PSM_PSU_Byte7 0;
BA_ "NetworkRequestHoldingTime" SG_ 3221225472 GST_PSM_PSU_Byte7 5000;
BA_ "Version" SG_ 3221225472 GST_PSM_PSU_Byte7 "18.01.09";
BA_ "Description" SG_ 3221225472 BCM_Crc3Val "The CRC checking process calculates the CRC over the entire data block, including the CRC result CRC Polynomial (0x1D) ,

Initial Value : 0x00, XOR value : 0x00

The mathematical expression to 8 bit CRC polynomial is given here. G(x) = x8 + x4 + x3 + x2 ";
BA_ "GenSigSendType" SG_ 3221225472 BCM_Crc3Val 4;
BA_ "GenSigStartValue" SG_ 3221225472 BCM_Crc3Val 255;
BA_ "UserSigValidity" SG_ 3221225472 BCM_Crc3Val 0;
BA_ "GenSigTimeoutTime" SG_ 3221225472 BCM_Crc3Val 1500;
BA_ "Version" SG_ 3221225472 BCM_Crc3Val "17.11.00";
BA_ "Description" SG_ 3221225472 BCM_AlvCnt3Val "For the first transmission request for a data element the counter shall be initialized with 0 and shall be incremented by 1

for every subsequent send request. When the counter reaches the maximum value(0xE), then it shall restart with ? for the next sen";
BA_ "GenSigSendType" SG_ 3221225472 BCM_AlvCnt3Val 4;
BA_ "UserSigValidity" SG_ 3221225472 BCM_AlvCnt3Val 0;
BA_ "GenSigTimeoutTime" SG_ 3221225472 BCM_AlvCnt3Val 1500;
BA_ "Version" SG_ 3221225472 BCM_AlvCnt3Val "17.11.00";
BA_ "Description" SG_ 3221225472 SBR_StBltWrngBzrSta "-Seat belt Warning (Reminder) buzzer";
BA_ "GenSigSendType" SG_ 3221225472 SBR_StBltWrngBzrSta 4;
BA_ "UserSigValidity" SG_ 3221225472 SBR_StBltWrngBzrSta 0;
BA_ "GenSigTimeoutTime" SG_ 3221225472 SBR_StBltWrngBzrSta 1500;
BA_ "NetworkRequest" SG_ 3221225472 SBR_StBltWrngBzrSta 0;
BA_ "NetworkRequestHoldingTime" SG_ 3221225472 SBR_StBltWrngBzrSta 5000;
BA_ "Version" SG_ 3221225472 SBR_StBltWrngBzrSta "17.12.00";
BA_ "GenSigSendType" SG_ 3221225472 SBR_DrvStBltIndSta 4;
BA_ "UserSigValidity" SG_ 3221225472 SBR_DrvStBltIndSta 0;
BA_ "GenSigTimeoutTime" SG_ 3221225472 SBR_DrvStBltIndSta 1500;
BA_ "NetworkRequest" SG_ 3221225472 SBR_DrvStBltIndSta 0;
BA_ "NetworkRequestHoldingTime" SG_ 3221225472 SBR_DrvStBltIndSta 5000;
BA_ "Version" SG_ 3221225472 SBR_DrvStBltIndSta "17.12.00";
BA_ "GenSigSendType" SG_ 3221225472 SBR_RrLftStBltWrngIndSta 4;
BA_ "UserSigValidity" SG_ 3221225472 SBR_RrLftStBltWrngIndSta 0;
BA_ "GenSigTimeoutTime" SG_ 3221225472 SBR_RrLftStBltWrngIndSta 1500;
BA_ "NetworkRequest" SG_ 3221225472 SBR_RrLftStBltWrngIndSta 0;
BA_ "NetworkRequestHoldingTime" SG_ 3221225472 SBR_RrLftStBltWrngIndSta 5000;
BA_ "Version" SG_ 3221225472 SBR_RrLftStBltWrngIndSta "17.12.00";
BA_ "GenSigSendType" SG_ 3221225472 SBR_RrRtStBltWrngIndSta 4;
BA_ "UserSigValidity" SG_ 3221225472 SBR_RrRtStBltWrngIndSta 0;
BA_ "GenSigTimeoutTime" SG_ 3221225472 SBR_RrRtStBltWrngIndSta 1500;
BA_ "NetworkRequest" SG_ 3221225472 SBR_RrRtStBltWrngIndSta 0;
BA_ "NetworkRequestHoldingTime" SG_ 3221225472 SBR_RrRtStBltWrngIndSta 5000;
BA_ "Version" SG_ 3221225472 SBR_RrRtStBltWrngIndSta "17.12.00";
BA_ "GenSigSendType" SG_ 3221225472 SBR_RrCtrStBltIndSta 4;
BA_ "UserSigValidity" SG_ 3221225472 SBR_RrCtrStBltIndSta 0;
BA_ "GenSigTimeoutTime" SG_ 3221225472 SBR_RrCtrStBltIndSta 1500;
BA_ "NetworkRequest" SG_ 3221225472 SBR_RrCtrStBltIndSta 0;
BA_ "NetworkRequestHoldingTime" SG_ 3221225472 SBR_RrCtrStBltIndSta 5000;
BA_ "Version" SG_ 3221225472 SBR_RrCtrStBltIndSta "17.12.00";
BA_ "Description" SG_ 3221225472 SBR_3rdLftStBltWrngIndSta "This signal is used for control the 3th Row Left Seatbelt indicator function.";
BA_ "GenSigSendType" SG_ 3221225472 SBR_3rdLftStBltWrngIndSta 4;
BA_ "UserSigValidity" SG_ 3221225472 SBR_3rdLftStBltWrngIndSta 0;
BA_ "GenSigTimeoutTime" SG_ 3221225472 SBR_3rdLftStBltWrngIndSta 1500;
BA_ "NetworkRequest" SG_ 3221225472 SBR_3rdLftStBltWrngIndSta 0;
BA_ "NetworkRequestHoldingTime" SG_ 3221225472 SBR_3rdLftStBltWrngIndSta 5000;
BA_ "Version" SG_ 3221225472 SBR_3rdLftStBltWrngIndSta "17.12.00";
BA_ "Description" SG_ 3221225472 SBR_3rdRtStBltWrngIndSta "This signal is used for control the 3th Row Right Seatbelt indicator function.";
BA_ "GenSigSendType" SG_ 3221225472 SBR_3rdRtStBltWrngIndSta 4;
BA_ "UserSigValidity" SG_ 3221225472 SBR_3rdRtStBltWrngIndSta 0;
BA_ "GenSigTimeoutTime" SG_ 3221225472 SBR_3rdRtStBltWrngIndSta 1500;
BA_ "NetworkRequest" SG_ 3221225472 SBR_3rdRtStBltWrngIndSta 0;
BA_ "NetworkRequestHoldingTime" SG_ 3221225472 SBR_3rdRtStBltWrngIndSta 5000;
BA_ "Version" SG_ 3221225472 SBR_3rdRtStBltWrngIndSta "17.12.00";
BA_ "UsrSigPurpose" SG_ 3221225472 SCM_GST_Byte0 2;
BA_ "GenSigSendType" SG_ 3221225472 SCM_GST_Byte0 2;
BA_ "UserSigValidity" SG_ 3221225472 SCM_GST_Byte0 0;
BA_ "GenSigTimeoutTime" SG_ 3221225472 SCM_GST_Byte0 0;
BA_ "NetworkRequest" SG_ 3221225472 SCM_GST_Byte0 0;
BA_ "NetworkRequestHoldingTime" SG_ 3221225472 SCM_GST_Byte0 5000;
BA_ "Version" SG_ 3221225472 SCM_GST_Byte0 "18.01.09";
BA_ "UsrSigPurpose" SG_ 3221225472 SCM_GST_Byte1 2;
BA_ "GenSigSendType" SG_ 3221225472 SCM_GST_Byte1 2;
BA_ "UserSigValidity" SG_ 3221225472 SCM_GST_Byte1 0;
BA_ "GenSigTimeoutTime" SG_ 3221225472 SCM_GST_Byte1 0;
BA_ "NetworkRequest" SG_ 3221225472 SCM_GST_Byte1 0;
BA_ "NetworkRequestHoldingTime" SG_ 3221225472 SCM_GST_Byte1 5000;
BA_ "Version" SG_ 3221225472 SCM_GST_Byte1 "18.01.09";
BA_ "UsrSigPurpose" SG_ 3221225472 SCM_GST_Byte2 2;
BA_ "GenSigSendType" SG_ 3221225472 SCM_GST_Byte2 2;
BA_ "UserSigValidity" SG_ 3221225472 SCM_GST_Byte2 0;
BA_ "GenSigTimeoutTime" SG_ 3221225472 SCM_GST_Byte2 0;
BA_ "NetworkRequest" SG_ 3221225472 SCM_GST_Byte2 0;
BA_ "NetworkRequestHoldingTime" SG_ 3221225472 SCM_GST_Byte2 5000;
BA_ "Version" SG_ 3221225472 SCM_GST_Byte2 "18.01.09";
BA_ "UsrSigPurpose" SG_ 3221225472 SCM_GST_Byte3 2;
BA_ "GenSigSendType" SG_ 3221225472 SCM_GST_Byte3 2;
BA_ "UserSigValidity" SG_ 3221225472 SCM_GST_Byte3 0;
BA_ "GenSigTimeoutTime" SG_ 3221225472 SCM_GST_Byte3 0;
BA_ "NetworkRequest" SG_ 3221225472 SCM_GST_Byte3 0;
BA_ "NetworkRequestHoldingTime" SG_ 3221225472 SCM_GST_Byte3 5000;
BA_ "Version" SG_ 3221225472 SCM_GST_Byte3 "18.01.09";
BA_ "UsrSigPurpose" SG_ 3221225472 SCM_GST_Byte4 2;
BA_ "GenSigSendType" SG_ 3221225472 SCM_GST_Byte4 2;
BA_ "UserSigValidity" SG_ 3221225472 SCM_GST_Byte4 0;
BA_ "GenSigTimeoutTime" SG_ 3221225472 SCM_GST_Byte4 0;
BA_ "NetworkRequest" SG_ 3221225472 SCM_GST_Byte4 0;
BA_ "NetworkRequestHoldingTime" SG_ 3221225472 SCM_GST_Byte4 5000;
BA_ "Version" SG_ 3221225472 SCM_GST_Byte4 "18.01.09";
BA_ "UsrSigPurpose" SG_ 3221225472 SCM_GST_Byte5 2;
BA_ "GenSigSendType" SG_ 3221225472 SCM_GST_Byte5 2;
BA_ "UserSigValidity" SG_ 3221225472 SCM_GST_Byte5 0;
BA_ "GenSigTimeoutTime" SG_ 3221225472 SCM_GST_Byte5 0;
BA_ "NetworkRequest" SG_ 3221225472 SCM_GST_Byte5 0;
BA_ "NetworkRequestHoldingTime" SG_ 3221225472 SCM_GST_Byte5 5000;
BA_ "Version" SG_ 3221225472 SCM_GST_Byte5 "18.01.09";
BA_ "UsrSigPurpose" SG_ 3221225472 SCM_GST_Byte6 2;
BA_ "GenSigSendType" SG_ 3221225472 SCM_GST_Byte6 2;
BA_ "UserSigValidity" SG_ 3221225472 SCM_GST_Byte6 0;
BA_ "GenSigTimeoutTime" SG_ 3221225472 SCM_GST_Byte6 0;
BA_ "NetworkRequest" SG_ 3221225472 SCM_GST_Byte6 0;
BA_ "NetworkRequestHoldingTime" SG_ 3221225472 SCM_GST_Byte6 5000;
BA_ "Version" SG_ 3221225472 SCM_GST_Byte6 "18.01.09";
BA_ "UsrSigPurpose" SG_ 3221225472 SCM_GST_Byte7 2;
BA_ "GenSigSendType" SG_ 3221225472 SCM_GST_Byte7 2;
BA_ "UserSigValidity" SG_ 3221225472 SCM_GST_Byte7 0;
BA_ "GenSigTimeoutTime" SG_ 3221225472 SCM_GST_Byte7 0;
BA_ "NetworkRequest" SG_ 3221225472 SCM_GST_Byte7 0;
BA_ "NetworkRequestHoldingTime" SG_ 3221225472 SCM_GST_Byte7 5000;
BA_ "Version" SG_ 3221225472 SCM_GST_Byte7 "18.01.09";
BA_ "Description" SG_ 3221225472 BCM_Crc2Val "The CRC checking process calculates the CRC over the entire data block, including the CRC result CRC Polynomial (0x1D) ,

Initial Value : 0x00, XOR value : 0x00

The mathematical expression to 8 bit CRC polynomial is given here. G(x) = x8 + x4 + x3 + x2 ";
BA_ "GenSigSendType" SG_ 3221225472 BCM_Crc2Val 4;
BA_ "GenSigStartValue" SG_ 3221225472 BCM_Crc2Val 255;
BA_ "UserSigValidity" SG_ 3221225472 BCM_Crc2Val 0;
BA_ "GenSigTimeoutTime" SG_ 3221225472 BCM_Crc2Val 1500;
BA_ "Version" SG_ 3221225472 BCM_Crc2Val "17.11.00";
BA_ "Description" SG_ 3221225472 BCM_AlvCnt2Val "For the first transmission request for a data element the counter shall be initialized with 0 and shall be incremented by 1

for every subsequent send request. When the counter reaches the maximum value(0xE), then it shall restart with ? for the next sen";
BA_ "GenSigSendType" SG_ 3221225472 BCM_AlvCnt2Val 4;
BA_ "UserSigValidity" SG_ 3221225472 BCM_AlvCnt2Val 0;
BA_ "GenSigTimeoutTime" SG_ 3221225472 BCM_AlvCnt2Val 1500;
BA_ "Version" SG_ 3221225472 BCM_AlvCnt2Val "17.11.00";
BA_ "GenSigSendType" SG_ 3221225472 BAlarm_BglrAlrmCurrentSta 4;
BA_ "UserSigValidity" SG_ 3221225472 BAlarm_BglrAlrmCurrentSta 0;
BA_ "GenSigTimeoutTime" SG_ 3221225472 BAlarm_BglrAlrmCurrentSta 1500;
BA_ "NetworkRequest" SG_ 3221225472 BAlarm_BglrAlrmCurrentSta 0;
BA_ "NetworkRequestHoldingTime" SG_ 3221225472 BAlarm_BglrAlrmCurrentSta 5000;
BA_ "Version" SG_ 3221225472 BAlarm_BglrAlrmCurrentSta "17.12.00";
BA_ "GenSigSendType" SG_ 3221225472 BAlarm_BglrAlrmSta 4;
BA_ "UserSigValidity" SG_ 3221225472 BAlarm_BglrAlrmSta 0;
BA_ "GenSigTimeoutTime" SG_ 3221225472 BAlarm_BglrAlrmSta 1500;
BA_ "NetworkRequest" SG_ 3221225472 BAlarm_BglrAlrmSta 0;
BA_ "NetworkRequestHoldingTime" SG_ 3221225472 BAlarm_BglrAlrmSta 5000;
BA_ "Version" SG_ 3221225472 BAlarm_BglrAlrmSta "17.12.00";
BA_ "Description" SG_ 3221225472 BAlarm_PncAlrmSta "-For TeleCranking Panic Function

-This signal send to IBOX";
BA_ "GenSigSendType" SG_ 3221225472 BAlarm_PncAlrmSta 4;
BA_ "UserSigValidity" SG_ 3221225472 BAlarm_PncAlrmSta 0;
BA_ "GenSigTimeoutTime" SG_ 3221225472 BAlarm_PncAlrmSta 1500;
BA_ "NetworkRequest" SG_ 3221225472 BAlarm_PncAlrmSta 0;
BA_ "NetworkRequestHoldingTime" SG_ 3221225472 BAlarm_PncAlrmSta 5000;
BA_ "Version" SG_ 3221225472 BAlarm_PncAlrmSta "17.12.00";
BA_ "GenSigSendType" SG_ 3221225472 BAlarm_BrglrHrnRlySta 4;
BA_ "UserSigValidity" SG_ 3221225472 BAlarm_BrglrHrnRlySta 0;
BA_ "GenSigTimeoutTime" SG_ 3221225472 BAlarm_BrglrHrnRlySta 1500;
BA_ "NetworkRequest" SG_ 3221225472 BAlarm_BrglrHrnRlySta 0;
BA_ "NetworkRequestHoldingTime" SG_ 3221225472 BAlarm_BrglrHrnRlySta 5000;
BA_ "Version" SG_ 3221225472 BAlarm_BrglrHrnRlySta "17.12.00";
BA_ "GenSigSendType" SG_ 3221225472 BCM_AccInSta 4;
BA_ "UserSigValidity" SG_ 3221225472 BCM_AccInSta 0;
BA_ "GenSigTimeoutTime" SG_ 3221225472 BCM_AccInSta 1500;
BA_ "NetworkRequest" SG_ 3221225472 BCM_AccInSta 0;
BA_ "NetworkRequestHoldingTime" SG_ 3221225472 BCM_AccInSta 5000;
BA_ "Version" SG_ 3221225472 BCM_AccInSta "17.12.00";
BA_ "GenSigSendType" SG_ 3221225472 BCM_Ign1InSta 4;
BA_ "UserSigValidity" SG_ 3221225472 BCM_Ign1InSta 0;
BA_ "GenSigTimeoutTime" SG_ 3221225472 BCM_Ign1InSta 1500;
BA_ "NetworkRequest" SG_ 3221225472 BCM_Ign1InSta 0;
BA_ "NetworkRequestHoldingTime" SG_ 3221225472 BCM_Ign1InSta 5000;
BA_ "Version" SG_ 3221225472 BCM_Ign1InSta "17.12.00";
BA_ "GenSigSendType" SG_ 3221225472 BCM_Ign2InSta 4;
BA_ "UserSigValidity" SG_ 3221225472 BCM_Ign2InSta 0;
BA_ "GenSigTimeoutTime" SG_ 3221225472 BCM_Ign2InSta 1500;
BA_ "NetworkRequest" SG_ 3221225472 BCM_Ign2InSta 0;
BA_ "NetworkRequestHoldingTime" SG_ 3221225472 BCM_Ign2InSta 5000;
BA_ "Version" SG_ 3221225472 BCM_Ign2InSta "17.12.00";
BA_ "GenSigSendType" SG_ 3221225472 BCM_IgnSwSta 4;
BA_ "UserSigValidity" SG_ 3221225472 BCM_IgnSwSta 0;
BA_ "GenSigTimeoutTime" SG_ 3221225472 BCM_IgnSwSta 1500;
BA_ "NetworkRequest" SG_ 3221225472 BCM_IgnSwSta 0;
BA_ "NetworkRequestHoldingTime" SG_ 3221225472 BCM_IgnSwSta 5000;
BA_ "Version" SG_ 3221225472 BCM_IgnSwSta "17.12.00";
BA_ "UsrSigPurpose" SG_ 3221225472 SWRC_GST_Byte0 2;
BA_ "GenSigSendType" SG_ 3221225472 SWRC_GST_Byte0 2;
BA_ "UserSigValidity" SG_ 3221225472 SWRC_GST_Byte0 0;
BA_ "GenSigTimeoutTime" SG_ 3221225472 SWRC_GST_Byte0 0;
BA_ "NetworkRequest" SG_ 3221225472 SWRC_GST_Byte0 0;
BA_ "NetworkRequestHoldingTime" SG_ 3221225472 SWRC_GST_Byte0 5000;
BA_ "Version" SG_ 3221225472 SWRC_GST_Byte0 "18.01.09";
BA_ "UsrSigPurpose" SG_ 3221225472 SWRC_GST_Byte1 2;
BA_ "GenSigSendType" SG_ 3221225472 SWRC_GST_Byte1 2;
BA_ "UserSigValidity" SG_ 3221225472 SWRC_GST_Byte1 0;
BA_ "GenSigTimeoutTime" SG_ 3221225472 SWRC_GST_Byte1 0;
BA_ "NetworkRequest" SG_ 3221225472 SWRC_GST_Byte1 0;
BA_ "NetworkRequestHoldingTime" SG_ 3221225472 SWRC_GST_Byte1 5000;
BA_ "Version" SG_ 3221225472 SWRC_GST_Byte1 "18.01.09";
BA_ "UsrSigPurpose" SG_ 3221225472 SWRC_GST_Byte2 2;
BA_ "GenSigSendType" SG_ 3221225472 SWRC_GST_Byte2 2;
BA_ "UserSigValidity" SG_ 3221225472 SWRC_GST_Byte2 0;
BA_ "GenSigTimeoutTime" SG_ 3221225472 SWRC_GST_Byte2 0;
BA_ "NetworkRequest" SG_ 3221225472 SWRC_GST_Byte2 0;
BA_ "NetworkRequestHoldingTime" SG_ 3221225472 SWRC_GST_Byte2 5000;
BA_ "Version" SG_ 3221225472 SWRC_GST_Byte2 "18.01.09";
BA_ "UsrSigPurpose" SG_ 3221225472 SWRC_GST_Byte3 2;
BA_ "GenSigSendType" SG_ 3221225472 SWRC_GST_Byte3 2;
BA_ "UserSigValidity" SG_ 3221225472 SWRC_GST_Byte3 0;
BA_ "GenSigTimeoutTime" SG_ 3221225472 SWRC_GST_Byte3 0;
BA_ "NetworkRequest" SG_ 3221225472 SWRC_GST_Byte3 0;
BA_ "NetworkRequestHoldingTime" SG_ 3221225472 SWRC_GST_Byte3 5000;
BA_ "Version" SG_ 3221225472 SWRC_GST_Byte3 "18.01.09";
BA_ "UsrSigPurpose" SG_ 3221225472 SWRC_GST_Byte4 2;
BA_ "GenSigSendType" SG_ 3221225472 SWRC_GST_Byte4 2;
BA_ "UserSigValidity" SG_ 3221225472 SWRC_GST_Byte4 0;
BA_ "GenSigTimeoutTime" SG_ 3221225472 SWRC_GST_Byte4 0;
BA_ "NetworkRequest" SG_ 3221225472 SWRC_GST_Byte4 0;
BA_ "NetworkRequestHoldingTime" SG_ 3221225472 SWRC_GST_Byte4 5000;
BA_ "Version" SG_ 3221225472 SWRC_GST_Byte4 "18.01.09";
BA_ "UsrSigPurpose" SG_ 3221225472 SWRC_GST_Byte5 2;
BA_ "GenSigSendType" SG_ 3221225472 SWRC_GST_Byte5 2;
BA_ "UserSigValidity" SG_ 3221225472 SWRC_GST_Byte5 0;
BA_ "GenSigTimeoutTime" SG_ 3221225472 SWRC_GST_Byte5 0;
BA_ "NetworkRequest" SG_ 3221225472 SWRC_GST_Byte5 0;
BA_ "NetworkRequestHoldingTime" SG_ 3221225472 SWRC_GST_Byte5 5000;
BA_ "Version" SG_ 3221225472 SWRC_GST_Byte5 "18.01.09";
BA_ "UsrSigPurpose" SG_ 3221225472 SWRC_GST_Byte6 2;
BA_ "GenSigSendType" SG_ 3221225472 SWRC_GST_Byte6 2;
BA_ "UserSigValidity" SG_ 3221225472 SWRC_GST_Byte6 0;
BA_ "GenSigTimeoutTime" SG_ 3221225472 SWRC_GST_Byte6 0;
BA_ "NetworkRequest" SG_ 3221225472 SWRC_GST_Byte6 0;
BA_ "NetworkRequestHoldingTime" SG_ 3221225472 SWRC_GST_Byte6 5000;
BA_ "Version" SG_ 3221225472 SWRC_GST_Byte6 "18.01.09";
BA_ "UsrSigPurpose" SG_ 3221225472 SWRC_GST_Byte7 2;
BA_ "GenSigSendType" SG_ 3221225472 SWRC_GST_Byte7 2;
BA_ "UserSigValidity" SG_ 3221225472 SWRC_GST_Byte7 0;
BA_ "GenSigTimeoutTime" SG_ 3221225472 SWRC_GST_Byte7 0;
BA_ "NetworkRequest" SG_ 3221225472 SWRC_GST_Byte7 0;
BA_ "NetworkRequestHoldingTime" SG_ 3221225472 SWRC_GST_Byte7 5000;
BA_ "Version" SG_ 3221225472 SWRC_GST_Byte7 "18.01.09";
BA_ "UsrSigPurpose" SG_ 3221225472 MFSW_GST_Byte0 2;
BA_ "GenSigSendType" SG_ 3221225472 MFSW_GST_Byte0 2;
BA_ "UserSigValidity" SG_ 3221225472 MFSW_GST_Byte0 0;
BA_ "GenSigTimeoutTime" SG_ 3221225472 MFSW_GST_Byte0 0;
BA_ "NetworkRequest" SG_ 3221225472 MFSW_GST_Byte0 0;
BA_ "NetworkRequestHoldingTime" SG_ 3221225472 MFSW_GST_Byte0 5000;
BA_ "Version" SG_ 3221225472 MFSW_GST_Byte0 "18.01.09";
BA_ "UsrSigPurpose" SG_ 3221225472 MFSW_GST_Byte1 2;
BA_ "GenSigSendType" SG_ 3221225472 MFSW_GST_Byte1 2;
BA_ "UserSigValidity" SG_ 3221225472 MFSW_GST_Byte1 0;
BA_ "GenSigTimeoutTime" SG_ 3221225472 MFSW_GST_Byte1 0;
BA_ "NetworkRequest" SG_ 3221225472 MFSW_GST_Byte1 0;
BA_ "NetworkRequestHoldingTime" SG_ 3221225472 MFSW_GST_Byte1 5000;
BA_ "Version" SG_ 3221225472 MFSW_GST_Byte1 "18.01.09";
BA_ "UsrSigPurpose" SG_ 3221225472 MFSW_GST_Byte2 2;
BA_ "GenSigSendType" SG_ 3221225472 MFSW_GST_Byte2 2;
BA_ "UserSigValidity" SG_ 3221225472 MFSW_GST_Byte2 0;
BA_ "GenSigTimeoutTime" SG_ 3221225472 MFSW_GST_Byte2 0;
BA_ "NetworkRequest" SG_ 3221225472 MFSW_GST_Byte2 0;
BA_ "NetworkRequestHoldingTime" SG_ 3221225472 MFSW_GST_Byte2 5000;
BA_ "Version" SG_ 3221225472 MFSW_GST_Byte2 "18.01.09";
BA_ "UsrSigPurpose" SG_ 3221225472 MFSW_GST_Byte3 2;
BA_ "GenSigSendType" SG_ 3221225472 MFSW_GST_Byte3 2;
BA_ "UserSigValidity" SG_ 3221225472 MFSW_GST_Byte3 0;
BA_ "GenSigTimeoutTime" SG_ 3221225472 MFSW_GST_Byte3 0;
BA_ "NetworkRequest" SG_ 3221225472 MFSW_GST_Byte3 0;
BA_ "NetworkRequestHoldingTime" SG_ 3221225472 MFSW_GST_Byte3 5000;
BA_ "Version" SG_ 3221225472 MFSW_GST_Byte3 "18.01.09";
BA_ "UsrSigPurpose" SG_ 3221225472 MFSW_GST_Byte4 2;
BA_ "GenSigSendType" SG_ 3221225472 MFSW_GST_Byte4 2;
BA_ "UserSigValidity" SG_ 3221225472 MFSW_GST_Byte4 0;
BA_ "GenSigTimeoutTime" SG_ 3221225472 MFSW_GST_Byte4 0;
BA_ "NetworkRequest" SG_ 3221225472 MFSW_GST_Byte4 0;
BA_ "NetworkRequestHoldingTime" SG_ 3221225472 MFSW_GST_Byte4 5000;
BA_ "Version" SG_ 3221225472 MFSW_GST_Byte4 "18.01.09";
BA_ "UsrSigPurpose" SG_ 3221225472 MFSW_GST_Byte5 2;
BA_ "GenSigSendType" SG_ 3221225472 MFSW_GST_Byte5 2;
BA_ "UserSigValidity" SG_ 3221225472 MFSW_GST_Byte5 0;
BA_ "GenSigTimeoutTime" SG_ 3221225472 MFSW_GST_Byte5 0;
BA_ "NetworkRequest" SG_ 3221225472 MFSW_GST_Byte5 0;
BA_ "NetworkRequestHoldingTime" SG_ 3221225472 MFSW_GST_Byte5 5000;
BA_ "Version" SG_ 3221225472 MFSW_GST_Byte5 "18.01.09";
BA_ "UsrSigPurpose" SG_ 3221225472 MFSW_GST_Byte6 2;
BA_ "GenSigSendType" SG_ 3221225472 MFSW_GST_Byte6 2;
BA_ "UserSigValidity" SG_ 3221225472 MFSW_GST_Byte6 0;
BA_ "GenSigTimeoutTime" SG_ 3221225472 MFSW_GST_Byte6 0;
BA_ "NetworkRequest" SG_ 3221225472 MFSW_GST_Byte6 0;
BA_ "NetworkRequestHoldingTime" SG_ 3221225472 MFSW_GST_Byte6 5000;
BA_ "Version" SG_ 3221225472 MFSW_GST_Byte6 "18.01.09";
BA_ "UsrSigPurpose" SG_ 3221225472 MFSW_GST_Byte7 2;
BA_ "GenSigSendType" SG_ 3221225472 MFSW_GST_Byte7 2;
BA_ "UserSigValidity" SG_ 3221225472 MFSW_GST_Byte7 0;
BA_ "GenSigTimeoutTime" SG_ 3221225472 MFSW_GST_Byte7 0;
BA_ "NetworkRequest" SG_ 3221225472 MFSW_GST_Byte7 0;
BA_ "NetworkRequestHoldingTime" SG_ 3221225472 MFSW_GST_Byte7 5000;
BA_ "Version" SG_ 3221225472 MFSW_GST_Byte7 "18.01.09";
BA_ "Description" SG_ 3221225472 BCM_Crc4Val "The CRC checking process calculates the CRC over the entire data block, including the CRC result CRC Polynomial (0x1D) ,

Initial Value : 0x00, XOR value : 0x00

The mathematical expression to 8 bit CRC polynomial is given here. G(x) = x8 + x4 + x3 + x2 ";
BA_ "GenSigSendType" SG_ 3221225472 BCM_Crc4Val 4;
BA_ "GenSigStartValue" SG_ 3221225472 BCM_Crc4Val 255;
BA_ "UserSigValidity" SG_ 3221225472 BCM_Crc4Val 0;
BA_ "GenSigTimeoutTime" SG_ 3221225472 BCM_Crc4Val 1500;
BA_ "Version" SG_ 3221225472 BCM_Crc4Val "17.11.00";
BA_ "Description" SG_ 3221225472 BCM_AlvCnt4Val "For the first transmission request for a data element the counter shall be initialized with 0 and shall be incremented by 1

for every subsequent send request. When the counter reaches the maximum value(0xE), then it shall restart with ? for the next sen";
BA_ "GenSigSendType" SG_ 3221225472 BCM_AlvCnt4Val 4;
BA_ "UserSigValidity" SG_ 3221225472 BCM_AlvCnt4Val 0;
BA_ "GenSigTimeoutTime" SG_ 3221225472 BCM_AlvCnt4Val 1500;
BA_ "Version" SG_ 3221225472 BCM_AlvCnt4Val "17.11.00";
BA_ "Description" SG_ 3221225472 Warn_BzrWrngSta "-(Old)C_WngBuzzer";
BA_ "GenSigSendType" SG_ 3221225472 Warn_BzrWrngSta 4;
BA_ "UserSigValidity" SG_ 3221225472 Warn_BzrWrngSta 0;
BA_ "GenSigTimeoutTime" SG_ 3221225472 Warn_BzrWrngSta 1500;
BA_ "NetworkRequest" SG_ 3221225472 Warn_BzrWrngSta 0;
BA_ "NetworkRequestHoldingTime" SG_ 3221225472 Warn_BzrWrngSta 5000;
BA_ "Version" SG_ 3221225472 Warn_BzrWrngSta "17.12.00";
BA_ "Description" SG_ 3221225472 Warn_BCMWrngSta "Warning command og BCM";
BA_ "GenSigSendType" SG_ 3221225472 Warn_BCMWrngSta 4;
BA_ "UserSigValidity" SG_ 3221225472 Warn_BCMWrngSta 0;
BA_ "GenSigTimeoutTime" SG_ 3221225472 Warn_BCMWrngSta 1500;
BA_ "NetworkRequest" SG_ 3221225472 Warn_BCMWrngSta 0;
BA_ "NetworkRequestHoldingTime" SG_ 3221225472 Warn_BCMWrngSta 5000;
BA_ "Version" SG_ 3221225472 Warn_BCMWrngSta "17.12.00";
BA_ "Description" SG_ 3221225472 Warn_RrStRmndOpt "Rear Seat Reminder System Appled Option";
BA_ "GenSigSendType" SG_ 3221225472 Warn_RrStRmndOpt 4;
BA_ "UserSigValidity" SG_ 3221225472 Warn_RrStRmndOpt 0;
BA_ "GenSigTimeoutTime" SG_ 3221225472 Warn_RrStRmndOpt 1500;
BA_ "NetworkRequest" SG_ 3221225472 Warn_RrStRmndOpt 0;
BA_ "NetworkRequestHoldingTime" SG_ 3221225472 Warn_RrStRmndOpt 5000;
BA_ "Version" SG_ 3221225472 Warn_RrStRmndOpt "17.12.00";
BA_ "Description" SG_ 3221225472 Warn_RrStRmndAlrmOnReq "Rear Seat Reminder Alarm State";
BA_ "GenSigSendType" SG_ 3221225472 Warn_RrStRmndAlrmOnReq 4;
BA_ "UserSigValidity" SG_ 3221225472 Warn_RrStRmndAlrmOnReq 0;
BA_ "GenSigTimeoutTime" SG_ 3221225472 Warn_RrStRmndAlrmOnReq 1500;
BA_ "NetworkRequest" SG_ 3221225472 Warn_RrStRmndAlrmOnReq 0;
BA_ "NetworkRequestHoldingTime" SG_ 3221225472 Warn_RrStRmndAlrmOnReq 5000;
BA_ "Version" SG_ 3221225472 Warn_RrStRmndAlrmOnReq "17.12.00";
BA_ "Description" SG_ 3221225472 Warn_RrStRmndSysSta "Rear Seat Reminder Alarm System Enable(On)/Disable(Off) state";
BA_ "GenSigSendType" SG_ 3221225472 Warn_RrStRmndSysSta 4;
BA_ "UserSigValidity" SG_ 3221225472 Warn_RrStRmndSysSta 0;
BA_ "GenSigTimeoutTime" SG_ 3221225472 Warn_RrStRmndSysSta 1500;
BA_ "NetworkRequest" SG_ 3221225472 Warn_RrStRmndSysSta 0;
BA_ "NetworkRequestHoldingTime" SG_ 3221225472 Warn_RrStRmndSysSta 5000;
BA_ "Version" SG_ 3221225472 Warn_RrStRmndSysSta "17.12.00";
BA_ "Description" SG_ 3221225472 Warn_RrStRmndAlrmInfo "Rear Seat Reminder Warning request signal";
BA_ "GenSigSendType" SG_ 3221225472 Warn_RrStRmndAlrmInfo 4;
BA_ "UserSigValidity" SG_ 3221225472 Warn_RrStRmndAlrmInfo 0;
BA_ "GenSigTimeoutTime" SG_ 3221225472 Warn_RrStRmndAlrmInfo 1500;
BA_ "NetworkRequest" SG_ 3221225472 Warn_RrStRmndAlrmInfo 0;
BA_ "NetworkRequestHoldingTime" SG_ 3221225472 Warn_RrStRmndAlrmInfo 5000;
BA_ "Version" SG_ 3221225472 Warn_RrStRmndAlrmInfo "17.12.00";
BA_ "UsrSigPurpose" SG_ 3221225472 DAU_GST_Byte0 2;
BA_ "GenSigSendType" SG_ 3221225472 DAU_GST_Byte0 2;
BA_ "UserSigValidity" SG_ 3221225472 DAU_GST_Byte0 0;
BA_ "GenSigTimeoutTime" SG_ 3221225472 DAU_GST_Byte0 0;
BA_ "NetworkRequest" SG_ 3221225472 DAU_GST_Byte0 0;
BA_ "NetworkRequestHoldingTime" SG_ 3221225472 DAU_GST_Byte0 5000;
BA_ "Version" SG_ 3221225472 DAU_GST_Byte0 "18.01.09";
BA_ "UsrSigPurpose" SG_ 3221225472 DAU_GST_Byte1 2;
BA_ "GenSigSendType" SG_ 3221225472 DAU_GST_Byte1 2;
BA_ "UserSigValidity" SG_ 3221225472 DAU_GST_Byte1 0;
BA_ "GenSigTimeoutTime" SG_ 3221225472 DAU_GST_Byte1 0;
BA_ "NetworkRequest" SG_ 3221225472 DAU_GST_Byte1 0;
BA_ "NetworkRequestHoldingTime" SG_ 3221225472 DAU_GST_Byte1 5000;
BA_ "Version" SG_ 3221225472 DAU_GST_Byte1 "18.01.09";
BA_ "UsrSigPurpose" SG_ 3221225472 DAU_GST_Byte2 2;
BA_ "GenSigSendType" SG_ 3221225472 DAU_GST_Byte2 2;
BA_ "UserSigValidity" SG_ 3221225472 DAU_GST_Byte2 0;
BA_ "GenSigTimeoutTime" SG_ 3221225472 DAU_GST_Byte2 0;
BA_ "NetworkRequest" SG_ 3221225472 DAU_GST_Byte2 0;
BA_ "NetworkRequestHoldingTime" SG_ 3221225472 DAU_GST_Byte2 5000;
BA_ "Version" SG_ 3221225472 DAU_GST_Byte2 "18.01.09";
BA_ "UsrSigPurpose" SG_ 3221225472 DAU_GST_Byte3 2;
BA_ "GenSigSendType" SG_ 3221225472 DAU_GST_Byte3 2;
BA_ "UserSigValidity" SG_ 3221225472 DAU_GST_Byte3 0;
BA_ "GenSigTimeoutTime" SG_ 3221225472 DAU_GST_Byte3 0;
BA_ "NetworkRequest" SG_ 3221225472 DAU_GST_Byte3 0;
BA_ "NetworkRequestHoldingTime" SG_ 3221225472 DAU_GST_Byte3 5000;
BA_ "Version" SG_ 3221225472 DAU_GST_Byte3 "18.01.09";
BA_ "UsrSigPurpose" SG_ 3221225472 DAU_GST_Byte4 2;
BA_ "GenSigSendType" SG_ 3221225472 DAU_GST_Byte4 2;
BA_ "UserSigValidity" SG_ 3221225472 DAU_GST_Byte4 0;
BA_ "GenSigTimeoutTime" SG_ 3221225472 DAU_GST_Byte4 0;
BA_ "NetworkRequest" SG_ 3221225472 DAU_GST_Byte4 0;
BA_ "NetworkRequestHoldingTime" SG_ 3221225472 DAU_GST_Byte4 5000;
BA_ "Version" SG_ 3221225472 DAU_GST_Byte4 "18.01.09";
BA_ "UsrSigPurpose" SG_ 3221225472 DAU_GST_Byte5 2;
BA_ "GenSigSendType" SG_ 3221225472 DAU_GST_Byte5 2;
BA_ "UserSigValidity" SG_ 3221225472 DAU_GST_Byte5 0;
BA_ "GenSigTimeoutTime" SG_ 3221225472 DAU_GST_Byte5 0;
BA_ "NetworkRequest" SG_ 3221225472 DAU_GST_Byte5 0;
BA_ "NetworkRequestHoldingTime" SG_ 3221225472 DAU_GST_Byte5 5000;
BA_ "Version" SG_ 3221225472 DAU_GST_Byte5 "18.01.09";
BA_ "UsrSigPurpose" SG_ 3221225472 DAU_GST_Byte6 2;
BA_ "GenSigSendType" SG_ 3221225472 DAU_GST_Byte6 2;
BA_ "UserSigValidity" SG_ 3221225472 DAU_GST_Byte6 0;
BA_ "GenSigTimeoutTime" SG_ 3221225472 DAU_GST_Byte6 0;
BA_ "NetworkRequest" SG_ 3221225472 DAU_GST_Byte6 0;
BA_ "NetworkRequestHoldingTime" SG_ 3221225472 DAU_GST_Byte6 5000;
BA_ "Version" SG_ 3221225472 DAU_GST_Byte6 "18.01.09";
BA_ "UsrSigPurpose" SG_ 3221225472 DAU_GST_Byte7 2;
BA_ "GenSigSendType" SG_ 3221225472 DAU_GST_Byte7 2;
BA_ "UserSigValidity" SG_ 3221225472 DAU_GST_Byte7 0;
BA_ "GenSigTimeoutTime" SG_ 3221225472 DAU_GST_Byte7 0;
BA_ "NetworkRequest" SG_ 3221225472 DAU_GST_Byte7 0;
BA_ "NetworkRequestHoldingTime" SG_ 3221225472 DAU_GST_Byte7 5000;
BA_ "Version" SG_ 3221225472 DAU_GST_Byte7 "18.01.09";
BA_ "Description" SG_ 3221225472 BCM_Crc5Val "The CRC checking process calculates the CRC over the entire data block, including the CRC result CRC Polynomial (0x1D) ,

Initial Value : 0x00, XOR value : 0x00

The mathematical expression to 8 bit CRC polynomial is given here. G(x) = x8 + x4 + x3 + x2 ";
BA_ "GenSigSendType" SG_ 3221225472 BCM_Crc5Val 4;
BA_ "GenSigStartValue" SG_ 3221225472 BCM_Crc5Val 255;
BA_ "UserSigValidity" SG_ 3221225472 BCM_Crc5Val 0;
BA_ "GenSigTimeoutTime" SG_ 3221225472 BCM_Crc5Val 1500;
BA_ "Version" SG_ 3221225472 BCM_Crc5Val "17.11.00";
BA_ "Description" SG_ 3221225472 BCM_AlvCnt5Val "For the first transmission request for a data element the counter shall be initialized with 0 and shall be incremented by 1

for every subsequent send request. When the counter reaches the maximum value(0xE), then it shall restart with ? for the next sen";
BA_ "GenSigSendType" SG_ 3221225472 BCM_AlvCnt5Val 4;
BA_ "UserSigValidity" SG_ 3221225472 BCM_AlvCnt5Val 0;
BA_ "GenSigTimeoutTime" SG_ 3221225472 BCM_AlvCnt5Val 1500;
BA_ "Version" SG_ 3221225472 BCM_AlvCnt5Val "17.11.00";
BA_ "Description" SG_ 3221225472 PDW_OptTyp "this signal means PDW Option (Non, PDW-R, PDW-FR)";
BA_ "GenSigSendType" SG_ 3221225472 PDW_OptTyp 4;
BA_ "UserSigValidity" SG_ 3221225472 PDW_OptTyp 3;
BA_ "GenSigTimeoutTime" SG_ 3221225472 PDW_OptTyp 1500;
BA_ "NetworkRequest" SG_ 3221225472 PDW_OptTyp 0;
BA_ "NetworkRequestHoldingTime" SG_ 3221225472 PDW_OptTyp 5000;
BA_ "Version" SG_ 3221225472 PDW_OptTyp "17.12.00";
BA_ "Description" SG_ 3221225472 PDW_SysChkSndSta "-PDW System state check sound";
BA_ "GenSigSendType" SG_ 3221225472 PDW_SysChkSndSta 4;
BA_ "UserSigValidity" SG_ 3221225472 PDW_SysChkSndSta 0;
BA_ "GenSigTimeoutTime" SG_ 3221225472 PDW_SysChkSndSta 1500;
BA_ "NetworkRequest" SG_ 3221225472 PDW_SysChkSndSta 0;
BA_ "NetworkRequestHoldingTime" SG_ 3221225472 PDW_SysChkSndSta 5000;
BA_ "Version" SG_ 3221225472 PDW_SysChkSndSta "17.12.00";
BA_ "Description" SG_ 3221225472 PDW_SwIndOnReq "-PDW Switch Indicator On/Off Request

This signal is used for PDW-R and PDW-F/R";
BA_ "GenSigSendType" SG_ 3221225472 PDW_SwIndOnReq 4;
BA_ "UserSigValidity" SG_ 3221225472 PDW_SwIndOnReq 0;
BA_ "GenSigTimeoutTime" SG_ 3221225472 PDW_SwIndOnReq 1500;
BA_ "NetworkRequest" SG_ 3221225472 PDW_SwIndOnReq 0;
BA_ "NetworkRequestHoldingTime" SG_ 3221225472 PDW_SwIndOnReq 5000;
BA_ "Version" SG_ 3221225472 PDW_SwIndOnReq "18.03.05";
BA_ "Description" SG_ 3221225472 PDW_SysOnSta "-PDW System operating status";
BA_ "GenSigSendType" SG_ 3221225472 PDW_SysOnSta 4;
BA_ "UserSigValidity" SG_ 3221225472 PDW_SysOnSta 0;
BA_ "GenSigTimeoutTime" SG_ 3221225472 PDW_SysOnSta 1500;
BA_ "NetworkRequest" SG_ 3221225472 PDW_SysOnSta 0;
BA_ "NetworkRequestHoldingTime" SG_ 3221225472 PDW_SysOnSta 5000;
BA_ "Version" SG_ 3221225472 PDW_SysOnSta "17.12.00";
BA_ "Description" SG_ 3221225472 PDW_FrCtrWrngLvlDis "-Front center display";
BA_ "GenSigSendType" SG_ 3221225472 PDW_FrCtrWrngLvlDis 4;
BA_ "UserSigValidity" SG_ 3221225472 PDW_FrCtrWrngLvlDis 0;
BA_ "GenSigTimeoutTime" SG_ 3221225472 PDW_FrCtrWrngLvlDis 1500;
BA_ "NetworkRequest" SG_ 3221225472 PDW_FrCtrWrngLvlDis 0;
BA_ "NetworkRequestHoldingTime" SG_ 3221225472 PDW_FrCtrWrngLvlDis 5000;
BA_ "Version" SG_ 3221225472 PDW_FrCtrWrngLvlDis "17.12.00";
BA_ "Description" SG_ 3221225472 PDW_FrCtrWrngSndSta "-Pas Warning Sound for AMP Speaker output";
BA_ "GenSigSendType" SG_ 3221225472 PDW_FrCtrWrngSndSta 4;
BA_ "UserSigValidity" SG_ 3221225472 PDW_FrCtrWrngSndSta 0;
BA_ "GenSigTimeoutTime" SG_ 3221225472 PDW_FrCtrWrngSndSta 1500;
BA_ "NetworkRequest" SG_ 3221225472 PDW_FrCtrWrngSndSta 0;
BA_ "NetworkRequestHoldingTime" SG_ 3221225472 PDW_FrCtrWrngSndSta 5000;
BA_ "Version" SG_ 3221225472 PDW_FrCtrWrngSndSta "17.12.00";
BA_ "Description" SG_ 3221225472 PDW_FrLftWrngLvlDis "-Front Left display";
BA_ "GenSigSendType" SG_ 3221225472 PDW_FrLftWrngLvlDis 4;
BA_ "UserSigValidity" SG_ 3221225472 PDW_FrLftWrngLvlDis 0;
BA_ "GenSigTimeoutTime" SG_ 3221225472 PDW_FrLftWrngLvlDis 1500;
BA_ "NetworkRequest" SG_ 3221225472 PDW_FrLftWrngLvlDis 0;
BA_ "NetworkRequestHoldingTime" SG_ 3221225472 PDW_FrLftWrngLvlDis 5000;
BA_ "Version" SG_ 3221225472 PDW_FrLftWrngLvlDis "17.12.00";
BA_ "Description" SG_ 3221225472 PDW_FrLftWrngSndSta "-Pas Warning Sound for AMP Speaker output";
BA_ "GenSigSendType" SG_ 3221225472 PDW_FrLftWrngSndSta 4;
BA_ "UserSigValidity" SG_ 3221225472 PDW_FrLftWrngSndSta 0;
BA_ "GenSigTimeoutTime" SG_ 3221225472 PDW_FrLftWrngSndSta 1500;
BA_ "NetworkRequest" SG_ 3221225472 PDW_FrLftWrngSndSta 0;
BA_ "NetworkRequestHoldingTime" SG_ 3221225472 PDW_FrLftWrngSndSta 5000;
BA_ "Version" SG_ 3221225472 PDW_FrLftWrngSndSta "17.12.00";
BA_ "Description" SG_ 3221225472 PDW_FrRtWrngLvlDis "-Front Right display";
BA_ "GenSigSendType" SG_ 3221225472 PDW_FrRtWrngLvlDis 4;
BA_ "UserSigValidity" SG_ 3221225472 PDW_FrRtWrngLvlDis 0;
BA_ "GenSigTimeoutTime" SG_ 3221225472 PDW_FrRtWrngLvlDis 1500;
BA_ "NetworkRequest" SG_ 3221225472 PDW_FrRtWrngLvlDis 0;
BA_ "NetworkRequestHoldingTime" SG_ 3221225472 PDW_FrRtWrngLvlDis 5000;
BA_ "Version" SG_ 3221225472 PDW_FrRtWrngLvlDis "17.12.00";
BA_ "Description" SG_ 3221225472 PDW_FrRtWrngSndSta "-Pas Warning Sound for AMP Speaker output";
BA_ "GenSigSendType" SG_ 3221225472 PDW_FrRtWrngSndSta 4;
BA_ "UserSigValidity" SG_ 3221225472 PDW_FrRtWrngSndSta 0;
BA_ "GenSigTimeoutTime" SG_ 3221225472 PDW_FrRtWrngSndSta 1500;
BA_ "NetworkRequest" SG_ 3221225472 PDW_FrRtWrngSndSta 0;
BA_ "NetworkRequestHoldingTime" SG_ 3221225472 PDW_FrRtWrngSndSta 5000;
BA_ "Version" SG_ 3221225472 PDW_FrRtWrngSndSta "17.12.00";
BA_ "Description" SG_ 3221225472 PDW_FrSnsrWrngLvlSta "-Front Sensor warning";
BA_ "GenSigSendType" SG_ 3221225472 PDW_FrSnsrWrngLvlSta 4;
BA_ "UserSigValidity" SG_ 3221225472 PDW_FrSnsrWrngLvlSta 0;
BA_ "GenSigTimeoutTime" SG_ 3221225472 PDW_FrSnsrWrngLvlSta 1500;
BA_ "NetworkRequest" SG_ 3221225472 PDW_FrSnsrWrngLvlSta 0;
BA_ "NetworkRequestHoldingTime" SG_ 3221225472 PDW_FrSnsrWrngLvlSta 5000;
BA_ "Version" SG_ 3221225472 PDW_FrSnsrWrngLvlSta "17.12.00";
BA_ "UsrSigPurpose" SG_ 3221225472 IBU_HS_GST_Byte0 2;
BA_ "GenSigSendType" SG_ 3221225472 IBU_HS_GST_Byte0 2;
BA_ "UserSigValidity" SG_ 3221225472 IBU_HS_GST_Byte0 0;
BA_ "GenSigTimeoutTime" SG_ 3221225472 IBU_HS_GST_Byte0 0;
BA_ "NetworkRequest" SG_ 3221225472 IBU_HS_GST_Byte0 0;
BA_ "NetworkRequestHoldingTime" SG_ 3221225472 IBU_HS_GST_Byte0 5000;
BA_ "Version" SG_ 3221225472 IBU_HS_GST_Byte0 "18.01.09";
BA_ "UsrSigPurpose" SG_ 3221225472 IBU_HS_GST_Byte1 2;
BA_ "GenSigSendType" SG_ 3221225472 IBU_HS_GST_Byte1 2;
BA_ "UserSigValidity" SG_ 3221225472 IBU_HS_GST_Byte1 0;
BA_ "GenSigTimeoutTime" SG_ 3221225472 IBU_HS_GST_Byte1 0;
BA_ "NetworkRequest" SG_ 3221225472 IBU_HS_GST_Byte1 0;
BA_ "NetworkRequestHoldingTime" SG_ 3221225472 IBU_HS_GST_Byte1 5000;
BA_ "Version" SG_ 3221225472 IBU_HS_GST_Byte1 "18.01.09";
BA_ "UsrSigPurpose" SG_ 3221225472 IBU_HS_GST_Byte2 2;
BA_ "GenSigSendType" SG_ 3221225472 IBU_HS_GST_Byte2 2;
BA_ "UserSigValidity" SG_ 3221225472 IBU_HS_GST_Byte2 0;
BA_ "GenSigTimeoutTime" SG_ 3221225472 IBU_HS_GST_Byte2 0;
BA_ "NetworkRequest" SG_ 3221225472 IBU_HS_GST_Byte2 0;
BA_ "NetworkRequestHoldingTime" SG_ 3221225472 IBU_HS_GST_Byte2 5000;
BA_ "Version" SG_ 3221225472 IBU_HS_GST_Byte2 "18.01.09";
BA_ "UsrSigPurpose" SG_ 3221225472 IBU_HS_GST_Byte3 2;
BA_ "GenSigSendType" SG_ 3221225472 IBU_HS_GST_Byte3 2;
BA_ "UserSigValidity" SG_ 3221225472 IBU_HS_GST_Byte3 0;
BA_ "GenSigTimeoutTime" SG_ 3221225472 IBU_HS_GST_Byte3 0;
BA_ "NetworkRequest" SG_ 3221225472 IBU_HS_GST_Byte3 0;
BA_ "NetworkRequestHoldingTime" SG_ 3221225472 IBU_HS_GST_Byte3 5000;
BA_ "Version" SG_ 3221225472 IBU_HS_GST_Byte3 "18.01.09";
BA_ "UsrSigPurpose" SG_ 3221225472 IBU_HS_GST_Byte4 2;
BA_ "GenSigSendType" SG_ 3221225472 IBU_HS_GST_Byte4 2;
BA_ "UserSigValidity" SG_ 3221225472 IBU_HS_GST_Byte4 0;
BA_ "GenSigTimeoutTime" SG_ 3221225472 IBU_HS_GST_Byte4 0;
BA_ "NetworkRequest" SG_ 3221225472 IBU_HS_GST_Byte4 0;
BA_ "NetworkRequestHoldingTime" SG_ 3221225472 IBU_HS_GST_Byte4 5000;
BA_ "Version" SG_ 3221225472 IBU_HS_GST_Byte4 "18.01.09";
BA_ "UsrSigPurpose" SG_ 3221225472 IBU_HS_GST_Byte5 2;
BA_ "GenSigSendType" SG_ 3221225472 IBU_HS_GST_Byte5 2;
BA_ "UserSigValidity" SG_ 3221225472 IBU_HS_GST_Byte5 0;
BA_ "GenSigTimeoutTime" SG_ 3221225472 IBU_HS_GST_Byte5 0;
BA_ "NetworkRequest" SG_ 3221225472 IBU_HS_GST_Byte5 0;
BA_ "NetworkRequestHoldingTime" SG_ 3221225472 IBU_HS_GST_Byte5 5000;
BA_ "Version" SG_ 3221225472 IBU_HS_GST_Byte5 "18.01.09";
BA_ "UsrSigPurpose" SG_ 3221225472 IBU_HS_GST_Byte6 2;
BA_ "GenSigSendType" SG_ 3221225472 IBU_HS_GST_Byte6 2;
BA_ "UserSigValidity" SG_ 3221225472 IBU_HS_GST_Byte6 0;
BA_ "GenSigTimeoutTime" SG_ 3221225472 IBU_HS_GST_Byte6 0;
BA_ "NetworkRequest" SG_ 3221225472 IBU_HS_GST_Byte6 0;
BA_ "NetworkRequestHoldingTime" SG_ 3221225472 IBU_HS_GST_Byte6 5000;
BA_ "Version" SG_ 3221225472 IBU_HS_GST_Byte6 "18.01.09";
BA_ "UsrSigPurpose" SG_ 3221225472 IBU_HS_GST_Byte7 2;
BA_ "GenSigSendType" SG_ 3221225472 IBU_HS_GST_Byte7 2;
BA_ "UserSigValidity" SG_ 3221225472 IBU_HS_GST_Byte7 0;
BA_ "GenSigTimeoutTime" SG_ 3221225472 IBU_HS_GST_Byte7 0;
BA_ "NetworkRequest" SG_ 3221225472 IBU_HS_GST_Byte7 0;
BA_ "NetworkRequestHoldingTime" SG_ 3221225472 IBU_HS_GST_Byte7 5000;
BA_ "Version" SG_ 3221225472 IBU_HS_GST_Byte7 "18.01.09";
BA_ "UsrSigPurpose" SG_ 3221225472 PSM_PSU_GST_Byte0 2;
BA_ "GenSigSendType" SG_ 3221225472 PSM_PSU_GST_Byte0 2;
BA_ "UserSigValidity" SG_ 3221225472 PSM_PSU_GST_Byte0 0;
BA_ "GenSigTimeoutTime" SG_ 3221225472 PSM_PSU_GST_Byte0 0;
BA_ "NetworkRequest" SG_ 3221225472 PSM_PSU_GST_Byte0 0;
BA_ "NetworkRequestHoldingTime" SG_ 3221225472 PSM_PSU_GST_Byte0 5000;
BA_ "Version" SG_ 3221225472 PSM_PSU_GST_Byte0 "18.01.09";
BA_ "UsrSigPurpose" SG_ 3221225472 PSM_PSU_GST_Byte1 2;
BA_ "GenSigSendType" SG_ 3221225472 PSM_PSU_GST_Byte1 2;
BA_ "UserSigValidity" SG_ 3221225472 PSM_PSU_GST_Byte1 0;
BA_ "GenSigTimeoutTime" SG_ 3221225472 PSM_PSU_GST_Byte1 0;
BA_ "NetworkRequest" SG_ 3221225472 PSM_PSU_GST_Byte1 0;
BA_ "NetworkRequestHoldingTime" SG_ 3221225472 PSM_PSU_GST_Byte1 5000;
BA_ "Version" SG_ 3221225472 PSM_PSU_GST_Byte1 "18.01.09";
BA_ "UsrSigPurpose" SG_ 3221225472 PSM_PSU_GST_Byte2 2;
BA_ "GenSigSendType" SG_ 3221225472 PSM_PSU_GST_Byte2 2;
BA_ "UserSigValidity" SG_ 3221225472 PSM_PSU_GST_Byte2 0;
BA_ "GenSigTimeoutTime" SG_ 3221225472 PSM_PSU_GST_Byte2 0;
BA_ "NetworkRequest" SG_ 3221225472 PSM_PSU_GST_Byte2 0;
BA_ "NetworkRequestHoldingTime" SG_ 3221225472 PSM_PSU_GST_Byte2 5000;
BA_ "Version" SG_ 3221225472 PSM_PSU_GST_Byte2 "18.01.09";
BA_ "UsrSigPurpose" SG_ 3221225472 PSM_PSU_GST_Byte3 2;
BA_ "GenSigSendType" SG_ 3221225472 PSM_PSU_GST_Byte3 2;
BA_ "UserSigValidity" SG_ 3221225472 PSM_PSU_GST_Byte3 0;
BA_ "GenSigTimeoutTime" SG_ 3221225472 PSM_PSU_GST_Byte3 0;
BA_ "NetworkRequest" SG_ 3221225472 PSM_PSU_GST_Byte3 0;
BA_ "NetworkRequestHoldingTime" SG_ 3221225472 PSM_PSU_GST_Byte3 5000;
BA_ "Version" SG_ 3221225472 PSM_PSU_GST_Byte3 "18.01.09";
BA_ "UsrSigPurpose" SG_ 3221225472 PSM_PSU_GST_Byte4 2;
BA_ "GenSigSendType" SG_ 3221225472 PSM_PSU_GST_Byte4 2;
BA_ "UserSigValidity" SG_ 3221225472 PSM_PSU_GST_Byte4 0;
BA_ "GenSigTimeoutTime" SG_ 3221225472 PSM_PSU_GST_Byte4 0;
BA_ "NetworkRequest" SG_ 3221225472 PSM_PSU_GST_Byte4 0;
BA_ "NetworkRequestHoldingTime" SG_ 3221225472 PSM_PSU_GST_Byte4 5000;
BA_ "Version" SG_ 3221225472 PSM_PSU_GST_Byte4 "18.01.09";
BA_ "UsrSigPurpose" SG_ 3221225472 PSM_PSU_GST_Byte5 2;
BA_ "GenSigSendType" SG_ 3221225472 PSM_PSU_GST_Byte5 2;
BA_ "UserSigValidity" SG_ 3221225472 PSM_PSU_GST_Byte5 0;
BA_ "GenSigTimeoutTime" SG_ 3221225472 PSM_PSU_GST_Byte5 0;
BA_ "NetworkRequest" SG_ 3221225472 PSM_PSU_GST_Byte5 0;
BA_ "NetworkRequestHoldingTime" SG_ 3221225472 PSM_PSU_GST_Byte5 5000;
BA_ "Version" SG_ 3221225472 PSM_PSU_GST_Byte5 "18.01.09";
BA_ "UsrSigPurpose" SG_ 3221225472 PSM_PSU_GST_Byte6 2;
BA_ "GenSigSendType" SG_ 3221225472 PSM_PSU_GST_Byte6 2;
BA_ "UserSigValidity" SG_ 3221225472 PSM_PSU_GST_Byte6 0;
BA_ "GenSigTimeoutTime" SG_ 3221225472 PSM_PSU_GST_Byte6 0;
BA_ "NetworkRequest" SG_ 3221225472 PSM_PSU_GST_Byte6 0;
BA_ "NetworkRequestHoldingTime" SG_ 3221225472 PSM_PSU_GST_Byte6 5000;
BA_ "Version" SG_ 3221225472 PSM_PSU_GST_Byte6 "18.01.09";
BA_ "UsrSigPurpose" SG_ 3221225472 PSM_PSU_GST_Byte7 2;
BA_ "GenSigSendType" SG_ 3221225472 PSM_PSU_GST_Byte7 2;
BA_ "UserSigValidity" SG_ 3221225472 PSM_PSU_GST_Byte7 0;
BA_ "GenSigTimeoutTime" SG_ 3221225472 PSM_PSU_GST_Byte7 0;
BA_ "NetworkRequest" SG_ 3221225472 PSM_PSU_GST_Byte7 0;
BA_ "NetworkRequestHoldingTime" SG_ 3221225472 PSM_PSU_GST_Byte7 5000;
BA_ "Version" SG_ 3221225472 PSM_PSU_GST_Byte7 "18.01.09";
BA_ "Description" SG_ 3221225472 BCM_Crc6Val "The CRC checking process calculates the CRC over the entire data block, including the CRC result CRC Polynomial (0x1D) ,

Initial Value : 0x00, XOR value : 0x00

The mathematical expression to 8 bit CRC polynomial is given here. G(x) = x8 + x4 + x3 + x2 ";
BA_ "GenSigSendType" SG_ 3221225472 BCM_Crc6Val 4;
BA_ "GenSigStartValue" SG_ 3221225472 BCM_Crc6Val 255;
BA_ "UserSigValidity" SG_ 3221225472 BCM_Crc6Val 0;
BA_ "GenSigTimeoutTime" SG_ 3221225472 BCM_Crc6Val 1500;
BA_ "Version" SG_ 3221225472 BCM_Crc6Val "17.11.00";
BA_ "Description" SG_ 3221225472 BCM_AlvCnt6Val "For the first transmission request for a data element the counter shall be initialized with 0 and shall be incremented by 1

for every subsequent send request. When the counter reaches the maximum value(0xE), then it shall restart with ? for the next sen";
BA_ "GenSigSendType" SG_ 3221225472 BCM_AlvCnt6Val 4;
BA_ "UserSigValidity" SG_ 3221225472 BCM_AlvCnt6Val 0;
BA_ "GenSigTimeoutTime" SG_ 3221225472 BCM_AlvCnt6Val 1500;
BA_ "Version" SG_ 3221225472 BCM_AlvCnt6Val "17.11.00";
BA_ "Description" SG_ 3221225472 PDW_RrCtrWrngLvlDis "-Rear center display";
BA_ "GenSigSendType" SG_ 3221225472 PDW_RrCtrWrngLvlDis 4;
BA_ "UserSigValidity" SG_ 3221225472 PDW_RrCtrWrngLvlDis 0;
BA_ "GenSigTimeoutTime" SG_ 3221225472 PDW_RrCtrWrngLvlDis 1500;
BA_ "NetworkRequest" SG_ 3221225472 PDW_RrCtrWrngLvlDis 0;
BA_ "NetworkRequestHoldingTime" SG_ 3221225472 PDW_RrCtrWrngLvlDis 5000;
BA_ "Version" SG_ 3221225472 PDW_RrCtrWrngLvlDis "17.12.00";
BA_ "Description" SG_ 3221225472 PDW_RrCtrWrngSndSta "-Pas Warning Sound for AMP Speaker output";
BA_ "GenSigSendType" SG_ 3221225472 PDW_RrCtrWrngSndSta 4;
BA_ "UserSigValidity" SG_ 3221225472 PDW_RrCtrWrngSndSta 0;
BA_ "GenSigTimeoutTime" SG_ 3221225472 PDW_RrCtrWrngSndSta 1500;
BA_ "NetworkRequest" SG_ 3221225472 PDW_RrCtrWrngSndSta 0;
BA_ "NetworkRequestHoldingTime" SG_ 3221225472 PDW_RrCtrWrngSndSta 5000;
BA_ "Version" SG_ 3221225472 PDW_RrCtrWrngSndSta "17.12.00";
BA_ "Description" SG_ 3221225472 PDW_RrLftWrngLvlDis "-Rear Left display";
BA_ "GenSigSendType" SG_ 3221225472 PDW_RrLftWrngLvlDis 4;
BA_ "UserSigValidity" SG_ 3221225472 PDW_RrLftWrngLvlDis 0;
BA_ "GenSigTimeoutTime" SG_ 3221225472 PDW_RrLftWrngLvlDis 1500;
BA_ "NetworkRequest" SG_ 3221225472 PDW_RrLftWrngLvlDis 0;
BA_ "NetworkRequestHoldingTime" SG_ 3221225472 PDW_RrLftWrngLvlDis 5000;
BA_ "Version" SG_ 3221225472 PDW_RrLftWrngLvlDis "17.12.00";
BA_ "Description" SG_ 3221225472 PDW_RrLftWrngSndSta "-Pas Warning Sound for AMP Speaker output";
BA_ "GenSigSendType" SG_ 3221225472 PDW_RrLftWrngSndSta 4;
BA_ "UserSigValidity" SG_ 3221225472 PDW_RrLftWrngSndSta 0;
BA_ "GenSigTimeoutTime" SG_ 3221225472 PDW_RrLftWrngSndSta 1500;
BA_ "NetworkRequest" SG_ 3221225472 PDW_RrLftWrngSndSta 0;
BA_ "NetworkRequestHoldingTime" SG_ 3221225472 PDW_RrLftWrngSndSta 5000;
BA_ "Version" SG_ 3221225472 PDW_RrLftWrngSndSta "17.12.00";
BA_ "Description" SG_ 3221225472 PDW_RrRtWrngLvlDis "-Rear Right display";
BA_ "GenSigSendType" SG_ 3221225472 PDW_RrRtWrngLvlDis 4;
BA_ "UserSigValidity" SG_ 3221225472 PDW_RrRtWrngLvlDis 0;
BA_ "GenSigTimeoutTime" SG_ 3221225472 PDW_RrRtWrngLvlDis 1500;
BA_ "NetworkRequest" SG_ 3221225472 PDW_RrRtWrngLvlDis 0;
BA_ "NetworkRequestHoldingTime" SG_ 3221225472 PDW_RrRtWrngLvlDis 5000;
BA_ "Version" SG_ 3221225472 PDW_RrRtWrngLvlDis "17.12.00";
BA_ "Description" SG_ 3221225472 PDW_RrRtWrngSndSta "-Pas Warning Sound for AMP Speaker output";
BA_ "GenSigSendType" SG_ 3221225472 PDW_RrRtWrngSndSta 4;
BA_ "UserSigValidity" SG_ 3221225472 PDW_RrRtWrngSndSta 0;
BA_ "GenSigTimeoutTime" SG_ 3221225472 PDW_RrRtWrngSndSta 1500;
BA_ "NetworkRequest" SG_ 3221225472 PDW_RrRtWrngSndSta 0;
BA_ "NetworkRequestHoldingTime" SG_ 3221225472 PDW_RrRtWrngSndSta 5000;
BA_ "Version" SG_ 3221225472 PDW_RrRtWrngSndSta "17.12.00";
BA_ "Description" SG_ 3221225472 PDW_RrSnsrWrngLvlSta "-Rear Sensor warning";
BA_ "GenSigSendType" SG_ 3221225472 PDW_RrSnsrWrngLvlSta 4;
BA_ "UserSigValidity" SG_ 3221225472 PDW_RrSnsrWrngLvlSta 0;
BA_ "GenSigTimeoutTime" SG_ 3221225472 PDW_RrSnsrWrngLvlSta 1500;
BA_ "NetworkRequest" SG_ 3221225472 PDW_RrSnsrWrngLvlSta 0;
BA_ "NetworkRequestHoldingTime" SG_ 3221225472 PDW_RrSnsrWrngLvlSta 5000;
BA_ "Version" SG_ 3221225472 PDW_RrSnsrWrngLvlSta "17.12.00";
BA_ "UsrSigPurpose" SG_ 3221225472 GST_APSU_Byte0 2;
BA_ "GenSigSendType" SG_ 3221225472 GST_APSU_Byte0 2;
BA_ "UserSigValidity" SG_ 3221225472 GST_APSU_Byte0 0;
BA_ "GenSigTimeoutTime" SG_ 3221225472 GST_APSU_Byte0 0;
BA_ "NetworkRequest" SG_ 3221225472 GST_APSU_Byte0 0;
BA_ "NetworkRequestHoldingTime" SG_ 3221225472 GST_APSU_Byte0 5000;
BA_ "Version" SG_ 3221225472 GST_APSU_Byte0 "18.03.03";
BA_ "UsrSigPurpose" SG_ 3221225472 GST_APSU_Byte1 2;
BA_ "GenSigSendType" SG_ 3221225472 GST_APSU_Byte1 2;
BA_ "UserSigValidity" SG_ 3221225472 GST_APSU_Byte1 0;
BA_ "GenSigTimeoutTime" SG_ 3221225472 GST_APSU_Byte1 0;
BA_ "NetworkRequest" SG_ 3221225472 GST_APSU_Byte1 0;
BA_ "NetworkRequestHoldingTime" SG_ 3221225472 GST_APSU_Byte1 5000;
BA_ "Version" SG_ 3221225472 GST_APSU_Byte1 "18.03.03";
BA_ "UsrSigPurpose" SG_ 3221225472 GST_APSU_Byte2 2;
BA_ "GenSigSendType" SG_ 3221225472 GST_APSU_Byte2 2;
BA_ "UserSigValidity" SG_ 3221225472 GST_APSU_Byte2 0;
BA_ "GenSigTimeoutTime" SG_ 3221225472 GST_APSU_Byte2 0;
BA_ "NetworkRequest" SG_ 3221225472 GST_APSU_Byte2 0;
BA_ "NetworkRequestHoldingTime" SG_ 3221225472 GST_APSU_Byte2 5000;
BA_ "Version" SG_ 3221225472 GST_APSU_Byte2 "18.03.03";
BA_ "UsrSigPurpose" SG_ 3221225472 GST_APSU_Byte3 2;
BA_ "GenSigSendType" SG_ 3221225472 GST_APSU_Byte3 2;
BA_ "UserSigValidity" SG_ 3221225472 GST_APSU_Byte3 0;
BA_ "GenSigTimeoutTime" SG_ 3221225472 GST_APSU_Byte3 0;
BA_ "NetworkRequest" SG_ 3221225472 GST_APSU_Byte3 0;
BA_ "NetworkRequestHoldingTime" SG_ 3221225472 GST_APSU_Byte3 5000;
BA_ "Version" SG_ 3221225472 GST_APSU_Byte3 "18.03.03";
BA_ "UsrSigPurpose" SG_ 3221225472 GST_APSU_Byte4 2;
BA_ "GenSigSendType" SG_ 3221225472 GST_APSU_Byte4 2;
BA_ "UserSigValidity" SG_ 3221225472 GST_APSU_Byte4 0;
BA_ "GenSigTimeoutTime" SG_ 3221225472 GST_APSU_Byte4 0;
BA_ "NetworkRequest" SG_ 3221225472 GST_APSU_Byte4 0;
BA_ "NetworkRequestHoldingTime" SG_ 3221225472 GST_APSU_Byte4 5000;
BA_ "Version" SG_ 3221225472 GST_APSU_Byte4 "18.03.03";
BA_ "UsrSigPurpose" SG_ 3221225472 GST_APSU_Byte5 2;
BA_ "GenSigSendType" SG_ 3221225472 GST_APSU_Byte5 2;
BA_ "UserSigValidity" SG_ 3221225472 GST_APSU_Byte5 0;
BA_ "GenSigTimeoutTime" SG_ 3221225472 GST_APSU_Byte5 0;
BA_ "NetworkRequest" SG_ 3221225472 GST_APSU_Byte5 0;
BA_ "NetworkRequestHoldingTime" SG_ 3221225472 GST_APSU_Byte5 5000;
BA_ "Version" SG_ 3221225472 GST_APSU_Byte5 "18.03.03";
BA_ "UsrSigPurpose" SG_ 3221225472 GST_APSU_Byte6 2;
BA_ "GenSigSendType" SG_ 3221225472 GST_APSU_Byte6 2;
BA_ "UserSigValidity" SG_ 3221225472 GST_APSU_Byte6 0;
BA_ "GenSigTimeoutTime" SG_ 3221225472 GST_APSU_Byte6 0;
BA_ "NetworkRequest" SG_ 3221225472 GST_APSU_Byte6 0;
BA_ "NetworkRequestHoldingTime" SG_ 3221225472 GST_APSU_Byte6 5000;
BA_ "Version" SG_ 3221225472 GST_APSU_Byte6 "18.03.03";
BA_ "UsrSigPurpose" SG_ 3221225472 GST_APSU_Byte7 2;
BA_ "GenSigSendType" SG_ 3221225472 GST_APSU_Byte7 2;
BA_ "UserSigValidity" SG_ 3221225472 GST_APSU_Byte7 0;
BA_ "GenSigTimeoutTime" SG_ 3221225472 GST_APSU_Byte7 0;
BA_ "NetworkRequest" SG_ 3221225472 GST_APSU_Byte7 0;
BA_ "NetworkRequestHoldingTime" SG_ 3221225472 GST_APSU_Byte7 5000;
BA_ "Version" SG_ 3221225472 GST_APSU_Byte7 "18.03.03";
BA_ "UsrSigPurpose" SG_ 3221225472 APSU_GST_Byte0 2;
BA_ "GenSigSendType" SG_ 3221225472 APSU_GST_Byte0 2;
BA_ "UserSigValidity" SG_ 3221225472 APSU_GST_Byte0 0;
BA_ "GenSigTimeoutTime" SG_ 3221225472 APSU_GST_Byte0 0;
BA_ "NetworkRequest" SG_ 3221225472 APSU_GST_Byte0 0;
BA_ "NetworkRequestHoldingTime" SG_ 3221225472 APSU_GST_Byte0 5000;
BA_ "Version" SG_ 3221225472 APSU_GST_Byte0 "18.03.03";
BA_ "UsrSigPurpose" SG_ 3221225472 APSU_GST_Byte1 2;
BA_ "GenSigSendType" SG_ 3221225472 APSU_GST_Byte1 2;
BA_ "UserSigValidity" SG_ 3221225472 APSU_GST_Byte1 0;
BA_ "GenSigTimeoutTime" SG_ 3221225472 APSU_GST_Byte1 0;
BA_ "NetworkRequest" SG_ 3221225472 APSU_GST_Byte1 0;
BA_ "NetworkRequestHoldingTime" SG_ 3221225472 APSU_GST_Byte1 5000;
BA_ "Version" SG_ 3221225472 APSU_GST_Byte1 "18.03.03";
BA_ "UsrSigPurpose" SG_ 3221225472 APSU_GST_Byte2 2;
BA_ "GenSigSendType" SG_ 3221225472 APSU_GST_Byte2 2;
BA_ "UserSigValidity" SG_ 3221225472 APSU_GST_Byte2 0;
BA_ "GenSigTimeoutTime" SG_ 3221225472 APSU_GST_Byte2 0;
BA_ "NetworkRequest" SG_ 3221225472 APSU_GST_Byte2 0;
BA_ "NetworkRequestHoldingTime" SG_ 3221225472 APSU_GST_Byte2 5000;
BA_ "Version" SG_ 3221225472 APSU_GST_Byte2 "18.03.03";
BA_ "UsrSigPurpose" SG_ 3221225472 APSU_GST_Byte3 2;
BA_ "GenSigSendType" SG_ 3221225472 APSU_GST_Byte3 2;
BA_ "UserSigValidity" SG_ 3221225472 APSU_GST_Byte3 0;
BA_ "GenSigTimeoutTime" SG_ 3221225472 APSU_GST_Byte3 0;
BA_ "NetworkRequest" SG_ 3221225472 APSU_GST_Byte3 0;
BA_ "NetworkRequestHoldingTime" SG_ 3221225472 APSU_GST_Byte3 5000;
BA_ "Version" SG_ 3221225472 APSU_GST_Byte3 "18.03.03";
BA_ "UsrSigPurpose" SG_ 3221225472 APSU_GST_Byte4 2;
BA_ "GenSigSendType" SG_ 3221225472 APSU_GST_Byte4 2;
BA_ "UserSigValidity" SG_ 3221225472 APSU_GST_Byte4 0;
BA_ "GenSigTimeoutTime" SG_ 3221225472 APSU_GST_Byte4 0;
BA_ "NetworkRequest" SG_ 3221225472 APSU_GST_Byte4 0;
BA_ "NetworkRequestHoldingTime" SG_ 3221225472 APSU_GST_Byte4 5000;
BA_ "Version" SG_ 3221225472 APSU_GST_Byte4 "18.03.03";
BA_ "UsrSigPurpose" SG_ 3221225472 APSU_GST_Byte5 2;
BA_ "GenSigSendType" SG_ 3221225472 APSU_GST_Byte5 2;
BA_ "UserSigValidity" SG_ 3221225472 APSU_GST_Byte5 0;
BA_ "GenSigTimeoutTime" SG_ 3221225472 APSU_GST_Byte5 0;
BA_ "NetworkRequest" SG_ 3221225472 APSU_GST_Byte5 0;
BA_ "NetworkRequestHoldingTime" SG_ 3221225472 APSU_GST_Byte5 5000;
BA_ "Version" SG_ 3221225472 APSU_GST_Byte5 "18.03.03";
BA_ "UsrSigPurpose" SG_ 3221225472 APSU_GST_Byte6 2;
BA_ "GenSigSendType" SG_ 3221225472 APSU_GST_Byte6 2;
BA_ "UserSigValidity" SG_ 3221225472 APSU_GST_Byte6 0;
BA_ "GenSigTimeoutTime" SG_ 3221225472 APSU_GST_Byte6 0;
BA_ "NetworkRequest" SG_ 3221225472 APSU_GST_Byte6 0;
BA_ "NetworkRequestHoldingTime" SG_ 3221225472 APSU_GST_Byte6 5000;
BA_ "Version" SG_ 3221225472 APSU_GST_Byte6 "18.03.03";
BA_ "UsrSigPurpose" SG_ 3221225472 APSU_GST_Byte7 2;
BA_ "GenSigSendType" SG_ 3221225472 APSU_GST_Byte7 2;
BA_ "UserSigValidity" SG_ 3221225472 APSU_GST_Byte7 0;
BA_ "GenSigTimeoutTime" SG_ 3221225472 APSU_GST_Byte7 0;
BA_ "NetworkRequest" SG_ 3221225472 APSU_GST_Byte7 0;
BA_ "NetworkRequestHoldingTime" SG_ 3221225472 APSU_GST_Byte7 5000;
BA_ "Version" SG_ 3221225472 APSU_GST_Byte7 "18.03.03";
BA_ "Description" SG_ 3221225472 EPB_Crc1Val "The CRC checking process calculates the CRC over the entire data block, including the CRC result.

- CRC Polynomial (0x1021) , Initial Value : 0xFFFF, XOR value : 0x0000

- The mathematical expression to 16 bit CRC polynomial is given here. G(x) = x16 + ";
BA_ "GenSigStartValue" SG_ 3221225472 EPB_Crc1Val 65535;
BA_ "UserSigValidity" SG_ 3221225472 EPB_Crc1Val 3;
BA_ "GenSigTimeoutTime" SG_ 3221225472 EPB_Crc1Val 1500;
BA_ "RoutingFactor" SG_ 3221225472 EPB_Crc1Val 3;
BA_ "Version" SG_ 3221225472 EPB_Crc1Val "17.11.00";
BA_ "Description" SG_ 3221225472 EPB_AlvCnt1Val "For the first transmission request for a data element the counter shall be initialized with 0 and shall be incremented by 1

for every subsequent send request. When the counter reaches the maximum value(0xFF), then it shall restart with ? for the next se";
BA_ "UserSigValidity" SG_ 3221225472 EPB_AlvCnt1Val 3;
BA_ "GenSigTimeoutTime" SG_ 3221225472 EPB_AlvCnt1Val 1500;
BA_ "RoutingFactor" SG_ 3221225472 EPB_AlvCnt1Val 3;
BA_ "Version" SG_ 3221225472 EPB_AlvCnt1Val "17.11.00";
BA_ "Description" SG_ 3221225472 EPB_LmpStaDis "This signal indicates status lamp request from EPB to lamp control unit.

- The lamp shall be turned on during initialization. The initialization lasts for 3 seconds after IG-key on.

- If a lamp control unit can not get this signal via CAN due to any er";
BA_ "UserSigValidity" SG_ 3221225472 EPB_LmpStaDis 3;
BA_ "GenSigTimeoutTime" SG_ 3221225472 EPB_LmpStaDis 1500;
BA_ "RoutingFactor" SG_ 3221225472 EPB_LmpStaDis 3;
BA_ "Version" SG_ 3221225472 EPB_LmpStaDis "17.12.00";
BA_ "Description" SG_ 3221225472 EPB_FlrLmpStaDis "Information about the failure lamp request from EPB to lamp control unit.



EPB_F_LAMP(0H) - Yellow failure lamp status(Off)

EPB_F_LAMP(1H) - Yellow failure lamp status(On)

EPB_F_LAMP(2H) - Yellow failure lamp status(Blinking at 1 Hz)";
BA_ "UserSigValidity" SG_ 3221225472 EPB_FlrLmpStaDis 3;
BA_ "GenSigTimeoutTime" SG_ 3221225472 EPB_FlrLmpStaDis 1500;
BA_ "RoutingFactor" SG_ 3221225472 EPB_FlrLmpStaDis 3;
BA_ "Version" SG_ 3221225472 EPB_FlrLmpStaDis "17.12.00";
BA_ "Description" SG_ 3221225472 EPB_OutDataDis "An EPB can show its information message to driver on a cluster or a display module with this signal. ※ 0x4 is for China";
BA_ "UserSigValidity" SG_ 3221225472 EPB_OutDataDis 3;
BA_ "GenSigTimeoutTime" SG_ 3221225472 EPB_OutDataDis 1500;
BA_ "RoutingFactor" SG_ 3221225472 EPB_OutDataDis 3;
BA_ "Version" SG_ 3221225472 EPB_OutDataDis "17.12.00";
BA_ "Description" SG_ 3221225472 EPB_AlrmReq "This signal indicates that an EPB requests cluster or tone controller to ring the alarm according to the status of an EPB.



Conversion [Condition]

0H : Normal operation

1H : EPB_CLU = 2 or 3

(send signals three time in a row & 1st signal should be s";
BA_ "UserSigValidity" SG_ 3221225472 EPB_AlrmReq 3;
BA_ "GenSigTimeoutTime" SG_ 3221225472 EPB_AlrmReq 1500;
BA_ "RoutingFactor" SG_ 3221225472 EPB_AlrmReq 3;
BA_ "Version" SG_ 3221225472 EPB_AlrmReq "17.12.00";
BA_ "Description" SG_ 3221225472 EPB_SwPosSta "Information about the EPB control switch state";
BA_ "UserSigValidity" SG_ 3221225472 EPB_SwPosSta 3;
BA_ "GenSigTimeoutTime" SG_ 3221225472 EPB_SwPosSta 1500;
BA_ "RoutingFactor" SG_ 3221225472 EPB_SwPosSta 3;
BA_ "Version" SG_ 3221225472 EPB_SwPosSta "17.12.00";
BA_ "Description" SG_ 3221225472 EPB_RrBrkLtActvReq "If an EPB acts braking and the vehicle speed is higher than pre-defined condition then rear brake lamp shall be turned on. This signal requests ESC or brake lamp controller to turn on rear brake lamp.";
BA_ "UserSigValidity" SG_ 3221225472 EPB_RrBrkLtActvReq 3;
BA_ "GenSigTimeoutTime" SG_ 3221225472 EPB_RrBrkLtActvReq 1500;
BA_ "RoutingFactor" SG_ 3221225472 EPB_RrBrkLtActvReq 3;
BA_ "Version" SG_ 3221225472 EPB_RrBrkLtActvReq "17.12.00";
BA_ "Description" SG_ 3221225472 EPB_FrcErrSta "Detail descriptions of error status of EPB force if EPB_FrcErrSta = 00H";
BA_ "UserSigValidity" SG_ 3221225472 EPB_FrcErrSta 3;
BA_ "GenSigTimeoutTime" SG_ 3221225472 EPB_FrcErrSta 1500;
BA_ "RoutingFactor" SG_ 3221225472 EPB_FrcErrSta 3;
BA_ "Version" SG_ 3221225472 EPB_FrcErrSta "17.12.00";
BA_ "Description" SG_ 3221225472 EPB_DynmBrkFrcReqSigSta "This signal indicates the validity of EPB_DynmBrkFrcReqSigSta (EPB request for ESP to activate Dynamic Brake Function) signal.";
BA_ "GenSigStartValue" SG_ 3221225472 EPB_DynmBrkFrcReqSigSta 1;
BA_ "UserSigValidity" SG_ 3221225472 EPB_DynmBrkFrcReqSigSta 3;
BA_ "GenSigTimeoutTime" SG_ 3221225472 EPB_DynmBrkFrcReqSigSta 1500;
BA_ "RoutingFactor" SG_ 3221225472 EPB_DynmBrkFrcReqSigSta 3;
BA_ "Version" SG_ 3221225472 EPB_DynmBrkFrcReqSigSta "17.12.00";
BA_ "Description" SG_ 3221225472 EPB_FrcSta "Information about the force status of the EPB";
BA_ "UserSigValidity" SG_ 3221225472 EPB_FrcSta 3;
BA_ "GenSigTimeoutTime" SG_ 3221225472 EPB_FrcSta 1500;
BA_ "RoutingFactor" SG_ 3221225472 EPB_FrcSta 3;
BA_ "Version" SG_ 3221225472 EPB_FrcSta "17.12.00";
BA_ "Description" SG_ 3221225472 EPB_FlSta "Information about availability of EPB. If this bit is set (EPB is not available), EPB motor control is not possible, e.g. by external AVH request.";
BA_ "GenSigStartValue" SG_ 3221225472 EPB_FlSta 2;
BA_ "UserSigValidity" SG_ 3221225472 EPB_FlSta 3;
BA_ "GenSigTimeoutTime" SG_ 3221225472 EPB_FlSta 1500;
BA_ "RoutingFactor" SG_ 3221225472 EPB_FlSta 3;
BA_ "Version" SG_ 3221225472 EPB_FlSta "17.12.00";
BA_ "Description" SG_ 3221225472 EPB_EscReqAckSta "Acknowledge signal for ESC request (e.g. AVH).



ESC sends request to release (1) or clamping (2) via signal REQ_EPB_ACT. The EPB acknowledges this request with EPB_EscReqAckSta = 1 within the time tESP_REQ_OK (value tbd) and performs according to the r";
BA_ "UserSigValidity" SG_ 3221225472 EPB_EscReqAckSta 3;
BA_ "GenSigTimeoutTime" SG_ 3221225472 EPB_EscReqAckSta 1500;
BA_ "RoutingFactor" SG_ 3221225472 EPB_EscReqAckSta 3;
BA_ "Version" SG_ 3221225472 EPB_EscReqAckSta "17.12.00";
BA_ "Description" SG_ 3221225472 EPB_DynmBrkFrcReq "EPB dynamic Braking Request";
BA_ "UserSigValidity" SG_ 3221225472 EPB_DynmBrkFrcReq 3;
BA_ "GenSigTimeoutTime" SG_ 3221225472 EPB_DynmBrkFrcReq 1500;
BA_ "RoutingFactor" SG_ 3221225472 EPB_DynmBrkFrcReq 3;
BA_ "Version" SG_ 3221225472 EPB_DynmBrkFrcReq "17.12.00";
BA_ "Description" SG_ 3221225472 EPB_ActlFrcVal "Actual braking force measured by EPB force sensor.";
BA_ "GenSigStartValue" SG_ 3221225472 EPB_ActlFrcVal 1000;
BA_ "UserSigValidity" SG_ 3221225472 EPB_ActlFrcVal 3;
BA_ "GenSigTimeoutTime" SG_ 3221225472 EPB_ActlFrcVal 1500;
BA_ "RoutingFactor" SG_ 3221225472 EPB_ActlFrcVal 3;
BA_ "Version" SG_ 3221225472 EPB_ActlFrcVal "17.12.00";
BA_ "Description" SG_ 3221225472 EPB_DynmBrkFrcDclReq "Requested deceleration for DBF. The ESC must consider this value if EPB_DynmBrkFrcReq is equal to 1.";
BA_ "UserSigValidity" SG_ 3221225472 EPB_DynmBrkFrcDclReq 3;
BA_ "GenSigTimeoutTime" SG_ 3221225472 EPB_DynmBrkFrcDclReq 1500;
BA_ "RoutingFactor" SG_ 3221225472 EPB_DynmBrkFrcDclReq 3;
BA_ "Version" SG_ 3221225472 EPB_DynmBrkFrcDclReq "17.12.00";
BA_ "Description" SG_ 3221225472 MFSW_Crc2Val "The CRC checking process calculates the CRC over the entire data block, including the CRC result CRC Polynomial (0x1D) ,

Initial Value : 0x00, XOR value : 0x00

The mathematical expression to 8 bit CRC polynomial is given here. G(x) = x8 + x4 + x3 + x2 ";
BA_ "GenSigSendType" SG_ 3221225472 MFSW_Crc2Val 4;
BA_ "GenSigStartValue" SG_ 3221225472 MFSW_Crc2Val 255;
BA_ "UserSigValidity" SG_ 3221225472 MFSW_Crc2Val 0;
BA_ "GenSigTimeoutTime" SG_ 3221225472 MFSW_Crc2Val 1500;
BA_ "Version" SG_ 3221225472 MFSW_Crc2Val "17.12.08";
BA_ "Description" SG_ 3221225472 MFSW_AlvCnt2Val "For the first transmission request for a data element the counter shall be initialized with 0 and shall be incremented by 1

for every subsequent send request. When the counter reaches the maximum value(0xE), then it shall restart with ? for the next sen";
BA_ "GenSigSendType" SG_ 3221225472 MFSW_AlvCnt2Val 4;
BA_ "UserSigValidity" SG_ 3221225472 MFSW_AlvCnt2Val 0;
BA_ "GenSigTimeoutTime" SG_ 3221225472 MFSW_AlvCnt2Val 1500;
BA_ "Version" SG_ 3221225472 MFSW_AlvCnt2Val "17.12.08";
BA_ "Description" SG_ 3221225472 Wiper_FrWiperSwSta "Multifuction Front Wiper Switch Status



The value '0x1' means 'Int Sw On' or 'Auto Sw on' and its status determined by 'C_RainSnsOption' signal



0x1 : Wiper Int Sw on (C_RainSnsOption = 0x0)



0x1 : Wiper Auto Sw on (C_RainSnsOption = 0x1)";
BA_ "GenSigSendType" SG_ 3221225472 Wiper_FrWiperSwSta 4;
BA_ "UserSigValidity" SG_ 3221225472 Wiper_FrWiperSwSta 0;
BA_ "GenSigTimeoutTime" SG_ 3221225472 Wiper_FrWiperSwSta 1500;
BA_ "NetworkRequest" SG_ 3221225472 Wiper_FrWiperSwSta 0;
BA_ "NetworkRequestHoldingTime" SG_ 3221225472 Wiper_FrWiperSwSta 5000;
BA_ "Version" SG_ 3221225472 Wiper_FrWiperSwSta "17.12.08";
BA_ "GenSigSendType" SG_ 3221225472 Wiper_IntStepSta 4;
BA_ "UserSigValidity" SG_ 3221225472 Wiper_IntStepSta 0;
BA_ "GenSigTimeoutTime" SG_ 3221225472 Wiper_IntStepSta 1500;
BA_ "NetworkRequest" SG_ 3221225472 Wiper_IntStepSta 0;
BA_ "NetworkRequestHoldingTime" SG_ 3221225472 Wiper_IntStepSta 5000;
BA_ "Version" SG_ 3221225472 Wiper_IntStepSta "17.12.08";
BA_ "GenSigSendType" SG_ 3221225472 Wiper_MstSwSta 4;
BA_ "UserSigValidity" SG_ 3221225472 Wiper_MstSwSta 0;
BA_ "GenSigTimeoutTime" SG_ 3221225472 Wiper_MstSwSta 1500;
BA_ "NetworkRequest" SG_ 3221225472 Wiper_MstSwSta 0;
BA_ "NetworkRequestHoldingTime" SG_ 3221225472 Wiper_MstSwSta 5000;
BA_ "Version" SG_ 3221225472 Wiper_MstSwSta "17.12.08";
BA_ "Description" SG_ 3221225472 Wiper_RrWiperSwSta "Multifunction Rear Wiper Switch Status";
BA_ "GenSigSendType" SG_ 3221225472 Wiper_RrWiperSwSta 4;
BA_ "UserSigValidity" SG_ 3221225472 Wiper_RrWiperSwSta 0;
BA_ "GenSigTimeoutTime" SG_ 3221225472 Wiper_RrWiperSwSta 1500;
BA_ "NetworkRequest" SG_ 3221225472 Wiper_RrWiperSwSta 0;
BA_ "NetworkRequestHoldingTime" SG_ 3221225472 Wiper_RrWiperSwSta 5000;
BA_ "Version" SG_ 3221225472 Wiper_RrWiperSwSta "17.12.08";
BA_ "Description" SG_ 3221225472 Wiper_FrWiperWshSwSta "Multifunction Front Wiper Washer Switch Status";
BA_ "GenSigSendType" SG_ 3221225472 Wiper_FrWiperWshSwSta 4;
BA_ "UserSigValidity" SG_ 3221225472 Wiper_FrWiperWshSwSta 0;
BA_ "GenSigTimeoutTime" SG_ 3221225472 Wiper_FrWiperWshSwSta 1500;
BA_ "NetworkRequest" SG_ 3221225472 Wiper_FrWiperWshSwSta 0;
BA_ "NetworkRequestHoldingTime" SG_ 3221225472 Wiper_FrWiperWshSwSta 5000;
BA_ "Version" SG_ 3221225472 Wiper_FrWiperWshSwSta "17.12.08";
BA_ "GenSigSendType" SG_ 3221225472 Wiper_RrWiperWshSwSta 4;
BA_ "UserSigValidity" SG_ 3221225472 Wiper_RrWiperWshSwSta 0;
BA_ "GenSigTimeoutTime" SG_ 3221225472 Wiper_RrWiperWshSwSta 1500;
BA_ "NetworkRequest" SG_ 3221225472 Wiper_RrWiperWshSwSta 0;
BA_ "NetworkRequestHoldingTime" SG_ 3221225472 Wiper_RrWiperWshSwSta 5000;
BA_ "Version" SG_ 3221225472 Wiper_RrWiperWshSwSta "17.12.08";
BA_ "Description" SG_ 3221225472 MFSW_Info "Mulitfunction switch information 

This signal is used to determine 'CAN type Multifunction switch' is applied or not in this vehicle.



0x0 : CAN type MFSW is Not Applied

0x1 : CAN type MFSW Applied



G/WAY Signal from MFSW (C_MFSW_Info)

- Follow to";
BA_ "GenSigSendType" SG_ 3221225472 MFSW_Info 4;
BA_ "UserSigValidity" SG_ 3221225472 MFSW_Info 0;
BA_ "GenSigTimeoutTime" SG_ 3221225472 MFSW_Info 1500;
BA_ "NetworkRequest" SG_ 3221225472 MFSW_Info 0;
BA_ "NetworkRequestHoldingTime" SG_ 3221225472 MFSW_Info 5000;
BA_ "Version" SG_ 3221225472 MFSW_Info "17.12.08";
BA_ "Description" SG_ 3221225472 RCCA_Deccel_Req "This value is defined the time to stop the vehicle.





(PH) = 0.04 * (Hex)s";
BA_ "UserSigValidity" SG_ 3221225472 RCCA_Deccel_Req 3;
BA_ "GenSigTimeoutTime" SG_ 3221225472 RCCA_Deccel_Req 1500;
BA_ "RoutingFactor" SG_ 3221225472 RCCA_Deccel_Req 3;
BA_ "Version" SG_ 3221225472 RCCA_Deccel_Req "18.01.10";
BA_ "Description" SG_ 3221225472 RCCA_BrkCmdSta "RCCA Function Brake Command";
BA_ "UserSigValidity" SG_ 3221225472 RCCA_BrkCmdSta 3;
BA_ "GenSigTimeoutTime" SG_ 3221225472 RCCA_BrkCmdSta 1500;
BA_ "RoutingFactor" SG_ 3221225472 RCCA_BrkCmdSta 3;
BA_ "Version" SG_ 3221225472 RCCA_BrkCmdSta "17.12.00";
BA_ "Description" SG_ 3221225472 RCCA_LftWrngSta "This signal Indicates RCCA Warning state for HMI(Cluster)";
BA_ "UserSigValidity" SG_ 3221225472 RCCA_LftWrngSta 3;
BA_ "GenSigTimeoutTime" SG_ 3221225472 RCCA_LftWrngSta 1500;
BA_ "RoutingFactor" SG_ 3221225472 RCCA_LftWrngSta 3;
BA_ "Version" SG_ 3221225472 RCCA_LftWrngSta "17.12.00";
BA_ "Description" SG_ 3221225472 RCCA_RtWrngSta "This signal Indicates RCCA Warning state for HMI";
BA_ "UserSigValidity" SG_ 3221225472 RCCA_RtWrngSta 3;
BA_ "GenSigTimeoutTime" SG_ 3221225472 RCCA_RtWrngSta 1500;
BA_ "RoutingFactor" SG_ 3221225472 RCCA_RtWrngSta 3;
BA_ "Version" SG_ 3221225472 RCCA_RtWrngSta "17.12.00";
BA_ "Description" SG_ 3221225472 RCCA_FuncStat "ESC state";
BA_ "UserSigValidity" SG_ 3221225472 RCCA_FuncStat 3;
BA_ "GenSigTimeoutTime" SG_ 3221225472 RCCA_FuncStat 1500;
BA_ "RoutingFactor" SG_ 3221225472 RCCA_FuncStat 3;
BA_ "Version" SG_ 3221225472 RCCA_FuncStat "17.12.00";
BA_ "Description" SG_ 3221225472 RCCA_Sta "This signal indicates the Status of RCCA";
BA_ "UserSigValidity" SG_ 3221225472 RCCA_Sta 3;
BA_ "GenSigTimeoutTime" SG_ 3221225472 RCCA_Sta 1500;
BA_ "RoutingFactor" SG_ 3221225472 RCCA_Sta 3;
BA_ "Version" SG_ 3221225472 RCCA_Sta "17.11.00";
BA_ "Description" SG_ 3221225472 SEA_Sta "SEA tells Body control unit to operate Child door lock to lock";
BA_ "UserSigValidity" SG_ 3221225472 SEA_Sta 0;
BA_ "GenSigTimeoutTime" SG_ 3221225472 SEA_Sta 1500;
BA_ "RoutingFactor" SG_ 3221225472 SEA_Sta 3;
BA_ "Version" SG_ 3221225472 SEA_Sta "17.11.00";
BA_ "Description" SG_ 3221225472 SEA_OnOffEquipSta "This signal indicates the on/off status of SEA";
BA_ "UserSigValidity" SG_ 3221225472 SEA_OnOffEquipSta 0;
BA_ "GenSigTimeoutTime" SG_ 3221225472 SEA_OnOffEquipSta 1500;
BA_ "RoutingFactor" SG_ 3221225472 SEA_OnOffEquipSta 3;
BA_ "Version" SG_ 3221225472 SEA_OnOffEquipSta "17.12.00";
BA_ "Description" SG_ 3221225472 SEA_LftWrngSta "This signal carries the information which message shall be displayed to the driver when the system must activate SEA";
BA_ "UserSigValidity" SG_ 3221225472 SEA_LftWrngSta 0;
BA_ "GenSigTimeoutTime" SG_ 3221225472 SEA_LftWrngSta 1500;
BA_ "RoutingFactor" SG_ 3221225472 SEA_LftWrngSta 3;
BA_ "Version" SG_ 3221225472 SEA_LftWrngSta "17.12.00";
BA_ "Description" SG_ 3221225472 SEA_RtWrngSta "This signal carries the information which message shall be displayed to the driver when the system must activate SEA";
BA_ "UserSigValidity" SG_ 3221225472 SEA_RtWrngSta 0;
BA_ "GenSigTimeoutTime" SG_ 3221225472 SEA_RtWrngSta 1500;
BA_ "RoutingFactor" SG_ 3221225472 SEA_RtWrngSta 3;
BA_ "Version" SG_ 3221225472 SEA_RtWrngSta "17.12.00";
BA_ "Description" SG_ 3221225472 RR_C_RDR_Equip "Corner Radar Sensor Type";
BA_ "UserSigValidity" SG_ 3221225472 RR_C_RDR_Equip 3;
BA_ "GenSigTimeoutTime" SG_ 3221225472 RR_C_RDR_Equip 1500;
BA_ "RoutingFactor" SG_ 3221225472 RR_C_RDR_Equip 3;
BA_ "Version" SG_ 3221225472 RR_C_RDR_Equip "18.02.00";
BA_ "Description" SG_ 3221225472 MFSW_Crc1Val "The CRC checking process calculates the CRC over the entire data block, including the CRC result CRC Polynomial (0x1D) ,

Initial Value : 0x00, XOR value : 0x00

The mathematical expression to 8 bit CRC polynomial is given here. G(x) = x8 + x4 + x3 + x2 ";
BA_ "GenSigSendType" SG_ 3221225472 MFSW_Crc1Val 4;
BA_ "GenSigStartValue" SG_ 3221225472 MFSW_Crc1Val 255;
BA_ "UserSigValidity" SG_ 3221225472 MFSW_Crc1Val 0;
BA_ "GenSigTimeoutTime" SG_ 3221225472 MFSW_Crc1Val 1500;
BA_ "Version" SG_ 3221225472 MFSW_Crc1Val "17.12.08";
BA_ "Description" SG_ 3221225472 MFSW_AlvCnt1Val "For the first transmission request for a data element the counter shall be initialized with 0 and shall be incremented by 1

for every subsequent send request. When the counter reaches the maximum value(0xE), then it shall restart with ? for the next sen";
BA_ "GenSigSendType" SG_ 3221225472 MFSW_AlvCnt1Val 4;
BA_ "UserSigValidity" SG_ 3221225472 MFSW_AlvCnt1Val 0;
BA_ "GenSigTimeoutTime" SG_ 3221225472 MFSW_AlvCnt1Val 1500;
BA_ "Version" SG_ 3221225472 MFSW_AlvCnt1Val "17.12.08";
BA_ "GenSigSendType" SG_ 3221225472 Lamp_HdLmpHiSwSta 4;
BA_ "UserSigValidity" SG_ 3221225472 Lamp_HdLmpHiSwSta 0;
BA_ "GenSigTimeoutTime" SG_ 3221225472 Lamp_HdLmpHiSwSta 1500;
BA_ "NetworkRequest" SG_ 3221225472 Lamp_HdLmpHiSwSta 0;
BA_ "NetworkRequestHoldingTime" SG_ 3221225472 Lamp_HdLmpHiSwSta 5000;
BA_ "Version" SG_ 3221225472 Lamp_HdLmpHiSwSta "17.12.08";
BA_ "GenSigSendType" SG_ 3221225472 Lamp_LtSwSta 4;
BA_ "UserSigValidity" SG_ 3221225472 Lamp_LtSwSta 0;
BA_ "GenSigTimeoutTime" SG_ 3221225472 Lamp_LtSwSta 1500;
BA_ "NetworkRequest" SG_ 3221225472 Lamp_LtSwSta 0;
BA_ "NetworkRequestHoldingTime" SG_ 3221225472 Lamp_LtSwSta 5000;
BA_ "Version" SG_ 3221225472 Lamp_LtSwSta "17.12.08";
BA_ "GenSigSendType" SG_ 3221225472 Lamp_PassingLmpSwSta 4;
BA_ "UserSigValidity" SG_ 3221225472 Lamp_PassingLmpSwSta 0;
BA_ "GenSigTimeoutTime" SG_ 3221225472 Lamp_PassingLmpSwSta 1500;
BA_ "NetworkRequest" SG_ 3221225472 Lamp_PassingLmpSwSta 0;
BA_ "NetworkRequestHoldingTime" SG_ 3221225472 Lamp_PassingLmpSwSta 5000;
BA_ "Version" SG_ 3221225472 Lamp_PassingLmpSwSta "17.12.08";
BA_ "GenSigSendType" SG_ 3221225472 Lamp_RrFogLmpSwSta 4;
BA_ "UserSigValidity" SG_ 3221225472 Lamp_RrFogLmpSwSta 0;
BA_ "GenSigTimeoutTime" SG_ 3221225472 Lamp_RrFogLmpSwSta 1500;
BA_ "NetworkRequest" SG_ 3221225472 Lamp_RrFogLmpSwSta 0;
BA_ "NetworkRequestHoldingTime" SG_ 3221225472 Lamp_RrFogLmpSwSta 5000;
BA_ "Version" SG_ 3221225472 Lamp_RrFogLmpSwSta "17.12.08";
BA_ "GenSigSendType" SG_ 3221225472 Lamp_TrnSigLftSwSta 4;
BA_ "UserSigValidity" SG_ 3221225472 Lamp_TrnSigLftSwSta 0;
BA_ "GenSigTimeoutTime" SG_ 3221225472 Lamp_TrnSigLftSwSta 1500;
BA_ "NetworkRequest" SG_ 3221225472 Lamp_TrnSigLftSwSta 0;
BA_ "NetworkRequestHoldingTime" SG_ 3221225472 Lamp_TrnSigLftSwSta 5000;
BA_ "Version" SG_ 3221225472 Lamp_TrnSigLftSwSta "17.12.08";
BA_ "GenSigSendType" SG_ 3221225472 Lamp_TrnSigRtSwSta 4;
BA_ "UserSigValidity" SG_ 3221225472 Lamp_TrnSigRtSwSta 0;
BA_ "GenSigTimeoutTime" SG_ 3221225472 Lamp_TrnSigRtSwSta 1500;
BA_ "NetworkRequest" SG_ 3221225472 Lamp_TrnSigRtSwSta 0;
BA_ "NetworkRequestHoldingTime" SG_ 3221225472 Lamp_TrnSigRtSwSta 5000;
BA_ "Version" SG_ 3221225472 Lamp_TrnSigRtSwSta "17.12.08";
BA_ "Description" SG_ 3221225472 Lamp_LaneChgTrnSigLftSwSta "LANE CHANGE TURN SIGNAL FOR LH";
BA_ "GenSigSendType" SG_ 3221225472 Lamp_LaneChgTrnSigLftSwSta 4;
BA_ "UserSigValidity" SG_ 3221225472 Lamp_LaneChgTrnSigLftSwSta 0;
BA_ "GenSigTimeoutTime" SG_ 3221225472 Lamp_LaneChgTrnSigLftSwSta 1500;
BA_ "NetworkRequest" SG_ 3221225472 Lamp_LaneChgTrnSigLftSwSta 0;
BA_ "NetworkRequestHoldingTime" SG_ 3221225472 Lamp_LaneChgTrnSigLftSwSta 5000;
BA_ "Version" SG_ 3221225472 Lamp_LaneChgTrnSigLftSwSta "18.01.00";
BA_ "Description" SG_ 3221225472 Lamp_LaneChgTrnSigRtSwSta "LANE CHANGE TURN SIGNAL FOR RH";
BA_ "GenSigSendType" SG_ 3221225472 Lamp_LaneChgTrnSigRtSwSta 4;
BA_ "UserSigValidity" SG_ 3221225472 Lamp_LaneChgTrnSigRtSwSta 0;
BA_ "GenSigTimeoutTime" SG_ 3221225472 Lamp_LaneChgTrnSigRtSwSta 1500;
BA_ "NetworkRequest" SG_ 3221225472 Lamp_LaneChgTrnSigRtSwSta 0;
BA_ "NetworkRequestHoldingTime" SG_ 3221225472 Lamp_LaneChgTrnSigRtSwSta 5000;
BA_ "Version" SG_ 3221225472 Lamp_LaneChgTrnSigRtSwSta "18.01.00";
BA_ "Description" SG_ 3221225472 RR_C_RDR_Crc1Val "The CRC checking process calculates the CRC over the entire data block, including the CRC result.

- CRC Polynomial (0x1021) , Initial Value : 0xFFFF, XOR value : 0x0000

- The mathematical expression to 16 bit CRC polynomial is given here. G(x) = x16 + ";
BA_ "GenSigStartValue" SG_ 3221225472 RR_C_RDR_Crc1Val 65535;
BA_ "UserSigValidity" SG_ 3221225472 RR_C_RDR_Crc1Val 3;
BA_ "GenSigTimeoutTime" SG_ 3221225472 RR_C_RDR_Crc1Val 1500;
BA_ "RoutingFactor" SG_ 3221225472 RR_C_RDR_Crc1Val 3;
BA_ "Version" SG_ 3221225472 RR_C_RDR_Crc1Val "17.11.00";
BA_ "Description" SG_ 3221225472 RR_C_RDR_AlvCnt1Val "For the first transmission request for a data element the counter shall be initialized with 0 and shall be incremented by 1

for every subsequent send request. When the counter reaches the maximum value(0xFF), then it shall restart with ? for the next se";
BA_ "UserSigValidity" SG_ 3221225472 RR_C_RDR_AlvCnt1Val 3;
BA_ "GenSigTimeoutTime" SG_ 3221225472 RR_C_RDR_AlvCnt1Val 1500;
BA_ "RoutingFactor" SG_ 3221225472 RR_C_RDR_AlvCnt1Val 3;
BA_ "Version" SG_ 3221225472 RR_C_RDR_AlvCnt1Val "17.11.00";
BA_ "Description" SG_ 3221225472 RCCW_Sta "This signal indicates the Status of RCCW";
BA_ "UserSigValidity" SG_ 3221225472 RCCW_Sta 3;
BA_ "GenSigTimeoutTime" SG_ 3221225472 RCCW_Sta 1500;
BA_ "RoutingFactor" SG_ 3221225472 RCCW_Sta 3;
BA_ "Version" SG_ 3221225472 RCCW_Sta "17.12.00";
BA_ "Description" SG_ 3221225472 RCCW_OnOffEquipSt "This signal indicates the on/off status of RCCW";
BA_ "UserSigValidity" SG_ 3221225472 RCCW_OnOffEquipSt 3;
BA_ "GenSigTimeoutTime" SG_ 3221225472 RCCW_OnOffEquipSt 1500;
BA_ "RoutingFactor" SG_ 3221225472 RCCW_OnOffEquipSt 3;
BA_ "Version" SG_ 3221225472 RCCW_OnOffEquipSt "17.12.00";
BA_ "Description" SG_ 3221225472 RCCW_LftIndSta "This signal Indicates RCCW Warning Indicator mode for Left side";
BA_ "UserSigValidity" SG_ 3221225472 RCCW_LftIndSta 3;
BA_ "GenSigTimeoutTime" SG_ 3221225472 RCCW_LftIndSta 1500;
BA_ "RoutingFactor" SG_ 3221225472 RCCW_LftIndSta 3;
BA_ "Version" SG_ 3221225472 RCCW_LftIndSta "17.12.00";
BA_ "Description" SG_ 3221225472 RCCW_RtIndSta "This signal Indicates RCCW Warning Indicator mode for Right side";
BA_ "UserSigValidity" SG_ 3221225472 RCCW_RtIndSta 3;
BA_ "GenSigTimeoutTime" SG_ 3221225472 RCCW_RtIndSta 1500;
BA_ "RoutingFactor" SG_ 3221225472 RCCW_RtIndSta 3;
BA_ "Version" SG_ 3221225472 RCCW_RtIndSta "17.12.00";
BA_ "Description" SG_ 3221225472 RCCW_LftSndWrngSta "This signal indicates RCCW Sound Warning for Rear Left Speaker";
BA_ "UserSigValidity" SG_ 3221225472 RCCW_LftSndWrngSta 3;
BA_ "GenSigTimeoutTime" SG_ 3221225472 RCCW_LftSndWrngSta 1500;
BA_ "RoutingFactor" SG_ 3221225472 RCCW_LftSndWrngSta 3;
BA_ "Version" SG_ 3221225472 RCCW_LftSndWrngSta "17.12.00";
BA_ "Description" SG_ 3221225472 RCCW_RtSndWrngSta "This signal indicates RCCW Sound Warning for Rear Right Speaker";
BA_ "UserSigValidity" SG_ 3221225472 RCCW_RtSndWrngSta 3;
BA_ "GenSigTimeoutTime" SG_ 3221225472 RCCW_RtSndWrngSta 1500;
BA_ "RoutingFactor" SG_ 3221225472 RCCW_RtSndWrngSta 3;
BA_ "Version" SG_ 3221225472 RCCW_RtSndWrngSta "17.12.00";
BA_ "Description" SG_ 3221225472 RCCW_LftWrngIndBriLvlVal "0x00~FF : Indicator Brightness level of RCCW";
BA_ "UserSigValidity" SG_ 3221225472 RCCW_LftWrngIndBriLvlVal 3;
BA_ "GenSigTimeoutTime" SG_ 3221225472 RCCW_LftWrngIndBriLvlVal 1500;
BA_ "RoutingFactor" SG_ 3221225472 RCCW_LftWrngIndBriLvlVal 3;
BA_ "Version" SG_ 3221225472 RCCW_LftWrngIndBriLvlVal "17.12.00";
BA_ "Description" SG_ 3221225472 RCCW_RtWrngIndBriLvlVal "0x00~FF : Indicator Brightness level of RCCW";
BA_ "UserSigValidity" SG_ 3221225472 RCCW_RtWrngIndBriLvlVal 3;
BA_ "GenSigTimeoutTime" SG_ 3221225472 RCCW_RtWrngIndBriLvlVal 1500;
BA_ "RoutingFactor" SG_ 3221225472 RCCW_RtWrngIndBriLvlVal 3;
BA_ "Version" SG_ 3221225472 RCCW_RtWrngIndBriLvlVal "17.12.00";
BA_ "Description" SG_ 1051 BCM_Crc8Val "The CRC checking process calculates the CRC over the entire data block, including the CRC result CRC Polynomial (0x1D) ,

Initial Value : 0x00, XOR value : 0x00

The mathematical expression to 8 bit CRC polynomial is given here. G(x) = x8 + x4 + x3 + x2 ";
BA_ "GenSigSendType" SG_ 1051 BCM_Crc8Val 4;
BA_ "GenSigStartValue" SG_ 1051 BCM_Crc8Val 255;
BA_ "UserSigValidity" SG_ 1051 BCM_Crc8Val 0;
BA_ "GenSigTimeoutTime" SG_ 1051 BCM_Crc8Val 1500;
BA_ "Version" SG_ 1051 BCM_Crc8Val "17.11.00";
BA_ "Description" SG_ 1051 BCM_AlvCnt8Val "For the first transmission request for a data element the counter shall be initialized with 0 and shall be incremented by 1

for every subsequent send request. When the counter reaches the maximum value(0xE), then it shall restart with ? for the next sen";
BA_ "GenSigSendType" SG_ 1051 BCM_AlvCnt8Val 4;
BA_ "UserSigValidity" SG_ 1051 BCM_AlvCnt8Val 0;
BA_ "GenSigTimeoutTime" SG_ 1051 BCM_AlvCnt8Val 1500;
BA_ "Version" SG_ 1051 BCM_AlvCnt8Val "17.11.00";
BA_ "Description" SG_ 1051 Lamp_HbaCtrlModTyp "This signal headlamp high control by BCM or HBA";
BA_ "GenSigSendType" SG_ 1051 Lamp_HbaCtrlModTyp 4;
BA_ "UserSigValidity" SG_ 1051 Lamp_HbaCtrlModTyp 0;
BA_ "GenSigTimeoutTime" SG_ 1051 Lamp_HbaCtrlModTyp 1500;
BA_ "NetworkRequest" SG_ 1051 Lamp_HbaCtrlModTyp 0;
BA_ "NetworkRequestHoldingTime" SG_ 1051 Lamp_HbaCtrlModTyp 5000;
BA_ "Version" SG_ 1051 Lamp_HbaCtrlModTyp "17.12.00";
BA_ "Description" SG_ 1051 Lamp_IFSCtrlModTyp "This signal headlamp high control by BCM or IFS";
BA_ "GenSigSendType" SG_ 1051 Lamp_IFSCtrlModTyp 4;
BA_ "UserSigValidity" SG_ 1051 Lamp_IFSCtrlModTyp 0;
BA_ "GenSigTimeoutTime" SG_ 1051 Lamp_IFSCtrlModTyp 1500;
BA_ "NetworkRequest" SG_ 1051 Lamp_IFSCtrlModTyp 0;
BA_ "NetworkRequestHoldingTime" SG_ 1051 Lamp_IFSCtrlModTyp 5000;
BA_ "Version" SG_ 1051 Lamp_IFSCtrlModTyp "17.12.00";
BA_ "GenSigSendType" SG_ 1051 Lamp_RrFogLmpOnReq 4;
BA_ "UserSigValidity" SG_ 1051 Lamp_RrFogLmpOnReq 0;
BA_ "GenSigTimeoutTime" SG_ 1051 Lamp_RrFogLmpOnReq 1500;
BA_ "NetworkRequest" SG_ 1051 Lamp_RrFogLmpOnReq 0;
BA_ "NetworkRequestHoldingTime" SG_ 1051 Lamp_RrFogLmpOnReq 5000;
BA_ "Version" SG_ 1051 Lamp_RrFogLmpOnReq "17.12.00";
BA_ "Description" SG_ 1051 Lamp_TailLmpWlcmCmd "TailWelcome Cmd 

- receiver : ICU (CGW)";
BA_ "GenSigSendType" SG_ 1051 Lamp_TailLmpWlcmCmd 4;
BA_ "UserSigValidity" SG_ 1051 Lamp_TailLmpWlcmCmd 0;
BA_ "GenSigTimeoutTime" SG_ 1051 Lamp_TailLmpWlcmCmd 1500;
BA_ "NetworkRequest" SG_ 1051 Lamp_TailLmpWlcmCmd 0;
BA_ "NetworkRequestHoldingTime" SG_ 1051 Lamp_TailLmpWlcmCmd 5000;
BA_ "Version" SG_ 1051 Lamp_TailLmpWlcmCmd "17.12.00";
BA_ "Description" SG_ 1051 Lamp_HdLmpWlcmCmd "HeadLamp Welcome Cmd 

- receiver : ICU (CGW)";
BA_ "GenSigSendType" SG_ 1051 Lamp_HdLmpWlcmCmd 4;
BA_ "UserSigValidity" SG_ 1051 Lamp_HdLmpWlcmCmd 0;
BA_ "GenSigTimeoutTime" SG_ 1051 Lamp_HdLmpWlcmCmd 1500;
BA_ "NetworkRequest" SG_ 1051 Lamp_HdLmpWlcmCmd 0;
BA_ "NetworkRequestHoldingTime" SG_ 1051 Lamp_HdLmpWlcmCmd 5000;
BA_ "Version" SG_ 1051 Lamp_HdLmpWlcmCmd "17.12.00";
BA_ "Description" SG_ 1051 Lamp_PuddleLmpOnReq "Puddle Lamp command";
BA_ "GenSigSendType" SG_ 1051 Lamp_PuddleLmpOnReq 4;
BA_ "UserSigValidity" SG_ 1051 Lamp_PuddleLmpOnReq 0;
BA_ "GenSigTimeoutTime" SG_ 1051 Lamp_PuddleLmpOnReq 1500;
BA_ "NetworkRequest" SG_ 1051 Lamp_PuddleLmpOnReq 0;
BA_ "NetworkRequestHoldingTime" SG_ 1051 Lamp_PuddleLmpOnReq 5000;
BA_ "Version" SG_ 1051 Lamp_PuddleLmpOnReq "17.12.00";
BA_ "Description" SG_ 1050 BCM_Crc7Val "The CRC checking process calculates the CRC over the entire data block, including the CRC result CRC Polynomial (0x1D) ,

Initial Value : 0x00, XOR value : 0x00

The mathematical expression to 8 bit CRC polynomial is given here. G(x) = x8 + x4 + x3 + x2 ";
BA_ "GenSigSendType" SG_ 1050 BCM_Crc7Val 4;
BA_ "GenSigStartValue" SG_ 1050 BCM_Crc7Val 255;
BA_ "UserSigValidity" SG_ 1050 BCM_Crc7Val 0;
BA_ "GenSigTimeoutTime" SG_ 1050 BCM_Crc7Val 1500;
BA_ "Version" SG_ 1050 BCM_Crc7Val "17.11.00";
BA_ "Description" SG_ 1050 BCM_AlvCnt7Val "For the first transmission request for a data element the counter shall be initialized with 0 and shall be incremented by 1

for every subsequent send request. When the counter reaches the maximum value(0xE), then it shall restart with ? for the next sen";
BA_ "GenSigSendType" SG_ 1050 BCM_AlvCnt7Val 4;
BA_ "UserSigValidity" SG_ 1050 BCM_AlvCnt7Val 0;
BA_ "GenSigTimeoutTime" SG_ 1050 BCM_AlvCnt7Val 1500;
BA_ "Version" SG_ 1050 BCM_AlvCnt7Val "17.11.00";
BA_ "Description" SG_ 1050 Lamp_HiPrioHzrdReq "-Higher priority than SJB hazard

-Diag/Arm/DisArm/Balarm/Panic/MTS

-Initial Value: 2";
BA_ "GenSigSendType" SG_ 1050 Lamp_HiPrioHzrdReq 4;
BA_ "GenSigStartValue" SG_ 1050 Lamp_HiPrioHzrdReq 2;
BA_ "UserSigValidity" SG_ 1050 Lamp_HiPrioHzrdReq 0;
BA_ "GenSigTimeoutTime" SG_ 1050 Lamp_HiPrioHzrdReq 1500;
BA_ "NetworkRequest" SG_ 1050 Lamp_HiPrioHzrdReq 0;
BA_ "NetworkRequestHoldingTime" SG_ 1050 Lamp_HiPrioHzrdReq 5000;
BA_ "Version" SG_ 1050 Lamp_HiPrioHzrdReq "17.12.00";
BA_ "Description" SG_ 1050 Lamp_LoPrioHzrdReq "-Lower priority than SJB hazard

-TrunkOpenClose/CrashUnlock/RemoteStart

-Initial Value: 2";
BA_ "GenSigSendType" SG_ 1050 Lamp_LoPrioHzrdReq 4;
BA_ "GenSigStartValue" SG_ 1050 Lamp_LoPrioHzrdReq 2;
BA_ "UserSigValidity" SG_ 1050 Lamp_LoPrioHzrdReq 0;
BA_ "GenSigTimeoutTime" SG_ 1050 Lamp_LoPrioHzrdReq 1500;
BA_ "NetworkRequest" SG_ 1050 Lamp_LoPrioHzrdReq 0;
BA_ "NetworkRequestHoldingTime" SG_ 1050 Lamp_LoPrioHzrdReq 5000;
BA_ "Version" SG_ 1050 Lamp_LoPrioHzrdReq "17.12.00";
BA_ "Description" SG_ 1050 Lamp_DedicatedDrlOnReq "-Lamp on command for dedicated DRL headlamp";
BA_ "GenSigSendType" SG_ 1050 Lamp_DedicatedDrlOnReq 4;
BA_ "UserSigValidity" SG_ 1050 Lamp_DedicatedDrlOnReq 0;
BA_ "GenSigTimeoutTime" SG_ 1050 Lamp_DedicatedDrlOnReq 1500;
BA_ "NetworkRequest" SG_ 1050 Lamp_DedicatedDrlOnReq 0;
BA_ "NetworkRequestHoldingTime" SG_ 1050 Lamp_DedicatedDrlOnReq 5000;
BA_ "Version" SG_ 1050 Lamp_DedicatedDrlOnReq "17.12.00";
BA_ "Description" SG_ 1050 Lamp_IntTailLmpOnReq "-(Old)C_INTTailOn";
BA_ "GenSigSendType" SG_ 1050 Lamp_IntTailLmpOnReq 4;
BA_ "UserSigValidity" SG_ 1050 Lamp_IntTailLmpOnReq 0;
BA_ "GenSigTimeoutTime" SG_ 1050 Lamp_IntTailLmpOnReq 1500;
BA_ "NetworkRequest" SG_ 1050 Lamp_IntTailLmpOnReq 0;
BA_ "NetworkRequestHoldingTime" SG_ 1050 Lamp_IntTailLmpOnReq 5000;
BA_ "Version" SG_ 1050 Lamp_IntTailLmpOnReq "17.12.00";
BA_ "Description" SG_ 1050 Lamp_ExtrnlTailLmpOnReq "-(Old)C_EXTTailOn";
BA_ "GenSigSendType" SG_ 1050 Lamp_ExtrnlTailLmpOnReq 4;
BA_ "UserSigValidity" SG_ 1050 Lamp_ExtrnlTailLmpOnReq 0;
BA_ "GenSigTimeoutTime" SG_ 1050 Lamp_ExtrnlTailLmpOnReq 1500;
BA_ "NetworkRequest" SG_ 1050 Lamp_ExtrnlTailLmpOnReq 0;
BA_ "NetworkRequestHoldingTime" SG_ 1050 Lamp_ExtrnlTailLmpOnReq 5000;
BA_ "Version" SG_ 1050 Lamp_ExtrnlTailLmpOnReq "17.12.00";
BA_ "Description" SG_ 1050 Lamp_HdLmpLoOnReq "-(Old)C_HLampLowON";
BA_ "GenSigSendType" SG_ 1050 Lamp_HdLmpLoOnReq 4;
BA_ "UserSigValidity" SG_ 1050 Lamp_HdLmpLoOnReq 0;
BA_ "GenSigTimeoutTime" SG_ 1050 Lamp_HdLmpLoOnReq 1500;
BA_ "NetworkRequest" SG_ 1050 Lamp_HdLmpLoOnReq 0;
BA_ "NetworkRequestHoldingTime" SG_ 1050 Lamp_HdLmpLoOnReq 5000;
BA_ "Version" SG_ 1050 Lamp_HdLmpLoOnReq "17.12.00";
BA_ "Description" SG_ 1050 Lamp_HdLmpHiOnReq "-(Old)C_HLampHighON";
BA_ "GenSigSendType" SG_ 1050 Lamp_HdLmpHiOnReq 4;
BA_ "UserSigValidity" SG_ 1050 Lamp_HdLmpHiOnReq 0;
BA_ "GenSigTimeoutTime" SG_ 1050 Lamp_HdLmpHiOnReq 1500;
BA_ "NetworkRequest" SG_ 1050 Lamp_HdLmpHiOnReq 0;
BA_ "NetworkRequestHoldingTime" SG_ 1050 Lamp_HdLmpHiOnReq 5000;
BA_ "Version" SG_ 1050 Lamp_HdLmpHiOnReq "17.12.00";
BA_ "Description" SG_ 1050 Lamp_AvTailLmpSta "-Send with at the same time with C_IntTailOn

-Initiail Value: 1";
BA_ "GenSigSendType" SG_ 1050 Lamp_AvTailLmpSta 4;
BA_ "GenSigStartValue" SG_ 1050 Lamp_AvTailLmpSta 1;
BA_ "UserSigValidity" SG_ 1050 Lamp_AvTailLmpSta 0;
BA_ "GenSigTimeoutTime" SG_ 1050 Lamp_AvTailLmpSta 1500;
BA_ "NetworkRequest" SG_ 1050 Lamp_AvTailLmpSta 0;
BA_ "NetworkRequestHoldingTime" SG_ 1050 Lamp_AvTailLmpSta 5000;
BA_ "Version" SG_ 1050 Lamp_AvTailLmpSta "17.12.00";
BA_ "Description" SG_ 1050 Lamp_ExtrnlLpWlcmSta "External Lamp Welcome Status for Dynamic Welcome";
BA_ "GenSigSendType" SG_ 1050 Lamp_ExtrnlLpWlcmSta 4;
BA_ "UserSigValidity" SG_ 1050 Lamp_ExtrnlLpWlcmSta 0;
BA_ "GenSigTimeoutTime" SG_ 1050 Lamp_ExtrnlLpWlcmSta 1500;
BA_ "NetworkRequest" SG_ 1050 Lamp_ExtrnlLpWlcmSta 0;
BA_ "NetworkRequestHoldingTime" SG_ 1050 Lamp_ExtrnlLpWlcmSta 5000;
BA_ "Version" SG_ 1050 Lamp_ExtrnlLpWlcmSta "18.03.06";
BA_ "GenSigSendType" SG_ 1043 ExtLamp_TrnSigLmpLftBlnkngSta 4;
BA_ "UserSigValidity" SG_ 1043 ExtLamp_TrnSigLmpLftBlnkngSta 0;
BA_ "GenSigTimeoutTime" SG_ 1043 ExtLamp_TrnSigLmpLftBlnkngSta 1500;
BA_ "NetworkRequest" SG_ 1043 ExtLamp_TrnSigLmpLftBlnkngSta 0;
BA_ "NetworkRequestHoldingTime" SG_ 1043 ExtLamp_TrnSigLmpLftBlnkngSta 5000;
BA_ "Version" SG_ 1043 ExtLamp_TrnSigLmpLftBlnkngSta "17.12.00";
BA_ "GenSigSendType" SG_ 1043 ExtLamp_TrnSigLmpRtBlnkngSta 4;
BA_ "UserSigValidity" SG_ 1043 ExtLamp_TrnSigLmpRtBlnkngSta 0;
BA_ "GenSigTimeoutTime" SG_ 1043 ExtLamp_TrnSigLmpRtBlnkngSta 1500;
BA_ "NetworkRequest" SG_ 1043 ExtLamp_TrnSigLmpRtBlnkngSta 0;
BA_ "NetworkRequestHoldingTime" SG_ 1043 ExtLamp_TrnSigLmpRtBlnkngSta 5000;
BA_ "Version" SG_ 1043 ExtLamp_TrnSigLmpRtBlnkngSta "17.12.00";
BA_ "Description" SG_ 1043 ExtLamp_ExtrnlTailLmpSta "-(Old)C_EXTTail_Act";
BA_ "GenSigSendType" SG_ 1043 ExtLamp_ExtrnlTailLmpSta 4;
BA_ "UserSigValidity" SG_ 1043 ExtLamp_ExtrnlTailLmpSta 0;
BA_ "GenSigTimeoutTime" SG_ 1043 ExtLamp_ExtrnlTailLmpSta 1500;
BA_ "NetworkRequest" SG_ 1043 ExtLamp_ExtrnlTailLmpSta 0;
BA_ "NetworkRequestHoldingTime" SG_ 1043 ExtLamp_ExtrnlTailLmpSta 5000;
BA_ "Version" SG_ 1043 ExtLamp_ExtrnlTailLmpSta "17.12.00";
BA_ "GenSigSendType" SG_ 1043 ExtLamp_HzrdSwSta 4;
BA_ "UserSigValidity" SG_ 1043 ExtLamp_HzrdSwSta 0;
BA_ "GenSigTimeoutTime" SG_ 1043 ExtLamp_HzrdSwSta 1500;
BA_ "NetworkRequest" SG_ 1043 ExtLamp_HzrdSwSta 0;
BA_ "NetworkRequestHoldingTime" SG_ 1043 ExtLamp_HzrdSwSta 5000;
BA_ "Version" SG_ 1043 ExtLamp_HzrdSwSta "17.12.00";
BA_ "Description" SG_ 1043 ExtLamp_RrFgLmpSta "-(Old)C_RearFog_Act";
BA_ "GenSigSendType" SG_ 1043 ExtLamp_RrFgLmpSta 4;
BA_ "UserSigValidity" SG_ 1043 ExtLamp_RrFgLmpSta 0;
BA_ "GenSigTimeoutTime" SG_ 1043 ExtLamp_RrFgLmpSta 1500;
BA_ "NetworkRequest" SG_ 1043 ExtLamp_RrFgLmpSta 0;
BA_ "NetworkRequestHoldingTime" SG_ 1043 ExtLamp_RrFgLmpSta 5000;
BA_ "Version" SG_ 1043 ExtLamp_RrFgLmpSta "17.12.00";
BA_ "Description" SG_ 1043 IntLamp_InlTailLmpSta "-(Old)C_INTTail_Act";
BA_ "GenSigSendType" SG_ 1043 IntLamp_InlTailLmpSta 4;
BA_ "UserSigValidity" SG_ 1043 IntLamp_InlTailLmpSta 0;
BA_ "GenSigTimeoutTime" SG_ 1043 IntLamp_InlTailLmpSta 1500;
BA_ "NetworkRequest" SG_ 1043 IntLamp_InlTailLmpSta 0;
BA_ "NetworkRequestHoldingTime" SG_ 1043 IntLamp_InlTailLmpSta 5000;
BA_ "Version" SG_ 1043 IntLamp_InlTailLmpSta "17.12.00";
BA_ "GenSigSendType" SG_ 1043 Lamp_TrnSigLmpLftOnReq 4;
BA_ "UserSigValidity" SG_ 1043 Lamp_TrnSigLmpLftOnReq 0;
BA_ "GenSigTimeoutTime" SG_ 1043 Lamp_TrnSigLmpLftOnReq 1500;
BA_ "NetworkRequest" SG_ 1043 Lamp_TrnSigLmpLftOnReq 0;
BA_ "NetworkRequestHoldingTime" SG_ 1043 Lamp_TrnSigLmpLftOnReq 5000;
BA_ "Version" SG_ 1043 Lamp_TrnSigLmpLftOnReq "17.12.05";
BA_ "GenSigSendType" SG_ 1043 Lamp_TrnSigLmpRtOnReq 4;
BA_ "UserSigValidity" SG_ 1043 Lamp_TrnSigLmpRtOnReq 0;
BA_ "GenSigTimeoutTime" SG_ 1043 Lamp_TrnSigLmpRtOnReq 1500;
BA_ "NetworkRequest" SG_ 1043 Lamp_TrnSigLmpRtOnReq 0;
BA_ "NetworkRequestHoldingTime" SG_ 1043 Lamp_TrnSigLmpRtOnReq 5000;
BA_ "Version" SG_ 1043 Lamp_TrnSigLmpRtOnReq "17.12.05";
VAL_ 3221225472 SCC_NSCCOnOffSta 0 "Default" 1 "Off" 2 "On" 3 "Invalid" ;
VAL_ 3221225472 SCC_ObjSta 0 "No in-path object detected" 1 "In-path object detected (uncontrollable)" 2 "In-path object detected (controllable: longitudinal)" 3 "In-path object detected (controllable: longitudinal & lateral)" 4 "Reserved" 5 "Reserved" 6 "Reserved" 7 "Reserved" ;
VAL_ 3221225472 SCC_SnstvtyModRetVal 0 "Default" 1 "Comford Mode" 2 "Normal Mode" 3 "Dynamic Mode" 4 "Reserved" 5 "Reserved" 6 "Reserved" 7 "Invalid" ;
VAL_ 3221225472 SCC_TrgtDstVal 1501 "0x5DD~0x7FF:Reserved" 2047 "0x5DD~0x7FF:Reserved" 2046 "Default" 2047 "Error" ;
VAL_ 3221225472 DATC_TempDispUnitSta 0 "Centigrade(℃)" 1 "Fahrenheit(℉)" 2 "Not used" 3 "Error Indicator" ;
VAL_ 3221225472 DATC_IntakeSta 0 "Default" 1 "REC (Fresh off)" 2 "FRE (REC off)" 3 "Error Indicator" ;
VAL_ 3221225472 SWRC_CrsSwSta 0 "Idle Position" 1 "Plus/Set" 2 "Minus/Set" 3 "Time gap (Distance, SCC only)" 4 "Resume/Cancel" 5 "Reserved" 6 "Reserved" 7 "Reserved" ;
VAL_ 3221225472 SWRC_CrsMainSwSta 0 "Off" 1 "Key On" 2 "Reserved" 3 "Invalid" ;
VAL_ 3221225472 SWRC_LFASwSta 0 "Off" 1 "Key On" 2 "Reserved" 3 "Invalid" ;
VAL_ 3221225472 SWRC_PaddleUpSwSta 0 "Off" 1 "Key On" 2 "Reserved" 3 "Invalid" ;
VAL_ 3221225472 SWRC_PaddleDnSwSta 0 "Off" 1 "Key On" 2 "Reserved" 3 "Invalid" ;
VAL_ 3221225472 SWRC_Info 0 "Off" 1 "ON(CAN Type)" 2 "Not Used" 3 "Error Indicator" ;
VAL_ 3221225472 SBR_StBltWrngBzrSta 0 "Warning Off" 1 "Buzzer Hold" 2 "Buzzer On" 3 "Reserved" 4 "Reserved" 5 "Reseved" 6 "Not Used" 7 "Error Indicator" ;
VAL_ 3221225472 SBR_DrvStBltIndSta 0 "Off" 1 "On" 2 "Not Used" 3 "Error Indicator" ;
VAL_ 3221225472 SBR_RrLftStBltWrngIndSta 0 "Off" 1 "On" 2 "Not Used" 3 "Error Indicator" ;
VAL_ 3221225472 SBR_RrRtStBltWrngIndSta 0 "Off" 1 "On" 2 "Not Used" 3 "Error Indicator" ;
VAL_ 3221225472 SBR_RrCtrStBltIndSta 0 "Off" 1 "On" 2 "Not Used" 3 "Error Indicator" ;
VAL_ 3221225472 SBR_3rdLftStBltWrngIndSta 0 "Off" 1 "On" 2 "Not Used" 3 "Error Indicator" ;
VAL_ 3221225472 SBR_3rdRtStBltWrngIndSta 0 "Off" 1 "On" 2 "Not Used" 3 "Error Indicator" ;
VAL_ 3221225472 BAlarm_BglrAlrmCurrentSta 0 "Off" 1 "DisArm" 2 "Arm" 3 "PreArm" 4 "ArmWait" 5 "ArmHold(Trunk)" 6 "ReArm" 7 "AutoLockTimer1" 8 "AutoLockTimer2" 9 "Alarm" 10 "Default" 11 "AutoLockTimer3(Tailgate)" 12 "Reserved" 13 "Reserved" 14 "Not Used" 15 "Error Indicator" ;
VAL_ 3221225472 BAlarm_BglrAlrmSta 0 "DIS-,PRE-,AUTOLOCKTIMER1,2,3(TG)" 1 "ARM,-WAIT,RE-,ALARM,-HD(Trunk)" 2 "Not Used" 3 "Error Indicator" ;
VAL_ 3221225472 BAlarm_PncAlrmSta 0 "Off" 1 "On (Panic Alarm ON)" 2 "Not Used" 3 "Error Indicator" ;
VAL_ 3221225472 BAlarm_BrglrHrnRlySta 0 "Off" 1 "On" 2 "Not Used" 3 "Error Indicator" ;
VAL_ 3221225472 BCM_AccInSta 0 "Acc Off" 1 "Acc On" 2 "Not Used" 3 "Error Indicator" ;
VAL_ 3221225472 BCM_Ign1InSta 0 "IGN1 Off" 1 "IGN1 On" 2 "Not Used" 3 "Error Indicator" ;
VAL_ 3221225472 BCM_Ign2InSta 0 "IGN2 Off" 1 "IGN2 On" 2 "Not Used" 3 "Error Indicator" ;
VAL_ 3221225472 BCM_IgnSwSta 0 "KeyOff" 1 "KeyIn" 2 "Acc" 3 "Ign" 4 "St" 5 "Reseved" 6 "Not Used" 7 "Error Indicator" ;
VAL_ 3221225472 Warn_BzrWrngSta 0 "Off" 1 "SeatBelt Warning" 2 "Key Operated Warning" 3 "Parking Brake Warning" 4 "Sun Roof Open Warning" 5 "Key Learning Sound(NoSMKOption" 6 "ICE Warning" 7 "Rear Fog Warning" 8 "Reserved" 9 "Reserved" 10 "Reserved" 11 "Reserved" 12 "Reserved" 13 "Reserved" 14 "Not Used" 15 "Error Indicator" ;
VAL_ 3221225472 Warn_BCMWrngSta 0 "Off" 1 "Power off request warning" 2 "Shift P request Warning" 3 "Reserved" 4 "Reserved" 5 "Reseved" 6 "Reseved" 7 "Reserved" 8 "Reserved" 9 "Reserved" 10 "Reserved" 11 "Reserved" 12 "Reserved" 13 "Reserved" 14 "Not Used" 15 "Error Indicator" ;
VAL_ 3221225472 Warn_RrStRmndOpt 0 "Not apply RrSeatRemind" 1 "Apply RrSeatRemind" 2 "Not Used" 3 "Error Indicator" ;
VAL_ 3221225472 Warn_RrStRmndAlrmOnReq 0 "Off" 1 "On(Alarm)" 2 "Not Used" 3 "Error Indicator" ;
VAL_ 3221225472 Warn_RrStRmndSysSta 0 "Default" 1 "System ON" 2 "System OFF" 3 "Error Indicator" ;
VAL_ 3221225472 Warn_RrStRmndAlrmInfo 0 "Off" 1 "Rear Seat Reminder Warning1" 2 "Reserved" 3 "Reserved" 4 "Reserved" 5 "Reseved" 6 "Not Used" 7 "Error Indicator" ;
VAL_ 3221225472 PDW_OptTyp 0 "Non" 1 "PDW R" 2 "PDW FR" 3 "Reserved" 4 "Reserved" 5 "Reseved" 6 "Not Used" 7 "Error Indicator" ;
VAL_ 3221225472 PDW_SysChkSndSta 0 "Off" 1 "R_Confirm" 2 "Error" 3 "Reserved" 4 "Reserved" 5 "Reseved" 6 "Not Used" 7 "Error Indicator" ;
VAL_ 3221225472 PDW_SwIndOnReq 0 "Indicator Off" 1 "Indicator On" 2 "Not Used" 3 "Error Indicator" ;
VAL_ 3221225472 PDW_SysOnSta 0 "Off" 1 "On" 2 "Reserved" 3 "Reserved" 4 "Reserved" 5 "Reseved" 6 "Not Used" 7 "Error Indicator" ;
VAL_ 3221225472 PDW_FrCtrWrngLvlDis 0 "Off" 1 "1st warning" 2 "2nd warning" 3 "3rd warning" 4 "Error" 5 "Reseved" 6 "Not Used" 7 "Error Indicator" ;
VAL_ 3221225472 PDW_FrCtrWrngSndSta 0 "Off" 1 "1st warning" 2 "2nd warning" 3 "3rd warning" 4 "Reserved" 5 "Reseved" 6 "Not Used" 7 "Error Indicator" ;
VAL_ 3221225472 PDW_FrLftWrngLvlDis 0 "Off" 1 "1st warning" 2 "2nd warning" 3 "3rd warning" 4 "Error" 5 "Reseved" 6 "Not Used" 7 "Error Indicator" ;
VAL_ 3221225472 PDW_FrLftWrngSndSta 0 "Off" 1 "1st warning" 2 "2nd warning" 3 "3rd warning" 4 "Reserved" 5 "Reseved" 6 "Not Used" 7 "Error Indicator" ;
VAL_ 3221225472 PDW_FrRtWrngLvlDis 0 "Off" 1 "1st warning" 2 "2nd warning" 3 "3rd warning" 4 "Error" 5 "Reseved" 6 "Not Used" 7 "Error Indicator" ;
VAL_ 3221225472 PDW_FrRtWrngSndSta 0 "Off" 1 "1st warning" 2 "2nd warning" 3 "3rd warning" 4 "Reserved" 5 "Reseved" 6 "Not Used" 7 "Error Indicator" ;
VAL_ 3221225472 PDW_FrSnsrWrngLvlSta 0 "Off" 1 "1st Waring" 2 "2nd Waring" 3 "3rd Warning" 4 "Reserved" 5 "Reseved" 6 "Not Used" 7 "Error Indicator" ;
VAL_ 3221225472 PDW_RrCtrWrngLvlDis 0 "Off" 1 "1st warning" 2 "2nd warning" 3 "3rd warning" 4 "Error" 5 "Reseved" 6 "Not Used" 7 "Error Indicator" ;
VAL_ 3221225472 PDW_RrCtrWrngSndSta 0 "Off" 1 "1st warning" 2 "2nd warning" 3 "3rd warning" 4 "Reserved" 5 "Reseved" 6 "Not Used" 7 "Error Indicator" ;
VAL_ 3221225472 PDW_RrLftWrngLvlDis 0 "Off" 1 "1st warning" 2 "2nd warning" 3 "3rd warning" 4 "Error" 5 "Reseved" 6 "Not Used" 7 "Error Indicator" ;
VAL_ 3221225472 PDW_RrLftWrngSndSta 0 "Off" 1 "1st warning" 2 "2nd warning" 3 "3rd warning" 4 "Reserved" 5 "Reseved" 6 "Not Used" 7 "Error Indicator" ;
VAL_ 3221225472 PDW_RrRtWrngLvlDis 0 "Off" 1 "1st warning" 2 "2nd warning" 3 "3rd warning" 4 "Error" 5 "Reseved" 6 "Not Used" 7 "Error Indicator" ;
VAL_ 3221225472 PDW_RrRtWrngSndSta 0 "Off" 1 "1st warning" 2 "2nd warning" 3 "3rd warning" 4 "Reserved" 5 "Reseved" 6 "Not Used" 7 "Error Indicator" ;
VAL_ 3221225472 PDW_RrSnsrWrngLvlSta 0 "Off" 1 "1st Waring" 2 "2nd Waring" 3 "3rd Warning" 4 "Reserved" 5 "Reseved" 6 "Not Used" 7 "Error Indicator" ;
VAL_ 3221225472 EPB_LmpStaDis 0 "Release State (EPB AVH)" 1 "Apply State (EPB)" 2 "Dynamic Braking (EPB) or Driver Action Requested" ;
VAL_ 3221225472 EPB_FlrLmpStaDis 0 "No failure" 1 "Failure detected or in diagnosis mode" 2 "EOL configuration not done or Emergency released" 3 "Reserved" 4 "Reserved" 5 "Reserved" 6 "Reserved" 7 "Reserved" 8 "Reserved" 9 "Reserved" 10 "Reserved" 11 "Reserved" 12 "Reserved" 13 "Reserved" 14 "Not used" 15 "Error Indicator" ;
VAL_ 3221225472 EPB_OutDataDis 0 "Off" 1 "EPB is in maintenance mode" 2 "Driver tries to DAR but safety condition is not satisfied" 3 "EPB applies by ESC request" 4 "Driver tries to DAR but safety condition is not satisfied for China" ;
VAL_ 3221225472 EPB_AlrmReq 0 "Off" 1 "Comfortable tone (Sound once)" 2 "Uncomfortable tone" 3 "Error Indicator" ;
VAL_ 3221225472 EPB_SwPosSta 0 "Neutral position" 1 "Apply position (pull)" 2 "Release position (push)" 3 "Switch failure" ;
VAL_ 3221225472 EPB_RrBrkLtActvReq 0 "No request" 1 "Request to turn on rear brake lights" 2 "Not used" 3 "Error Indicator" ;
VAL_ 3221225472 EPB_FrcErrSta 0 "No failure" 1 "Clamp position not reached" 2 "Emergency release" 3 "Force not measurable (e.g. sensor failure)" ;
VAL_ 3221225472 EPB_DynmBrkFrcReqSigSta 0 "EPB_DynmBrkFrcReqSigSta signal is invalid" 1 "EPB_DynmBrkFrcReqSigSta signal is valid" 2 "Not used" 3 "Error Indicator" ;
VAL_ 3221225472 EPB_FrcSta 0 "See details in EPB_FRC_ERR" 1 "Released" 2 "Clamped" 3 "Clamping in progress" 4 "Releasing in progress" 5 "Dynamic braking via EPB" 6 "Releasing in progress by switch" 7 "Clamping in progress by switch" ;
VAL_ 3221225472 EPB_FlSta 0 "Not valid" 1 "EPB No failure" 2 "EPB Initialization State" 3 "EPB Diagnostic" 4 "EPB Temporarily Not Available" 5 "EPB Permanently Not Available" ;
VAL_ 3221225472 EPB_EscReqAckSta 0 "Idle / No acknowledge" 1 "Acknowledge for external ESC request" 2 "Not used" 3 "Error Indicator" ;
VAL_ 3221225472 EPB_DynmBrkFrcReq 0 "No Request" 1 "Dynamic braking request" 2 "Not used" 3 "Error Indicator" ;
VAL_ 3221225472 EPB_ActlFrcVal 0 "EPB Fully released" ;
VAL_ 3221225472 Wiper_FrWiperSwSta 0 "Wiper Sw Off" 1 "Wiper Int or Auto Sw On(Refer to C_RainSnsOption)" 2 "Wiper Low Sw On" 3 "Wiper High Sw On" 4 "Reserved" 5 "Reserved" 6 "Not Used" 7 "Error Indicator" ;
VAL_ 3221225472 Wiper_IntStepSta 0 "STEP1(SLOW)" 1 "STEP2" 2 "STEP3" 3 "STEP4" 4 "STEP5(FAST)" ;
VAL_ 3221225472 Wiper_MstSwSta 0 "Off" 1 "On" 2 "Not Used" 3 "Error Indicator" ;
VAL_ 3221225472 Wiper_RrWiperSwSta 0 "Rear Wiper Sw Off" 1 "Rear Wiper Low Sw On" 2 "Rear Wiper High Sw On" 3 "Reserved" ;
VAL_ 3221225472 Wiper_FrWiperWshSwSta 0 "Off" 1 "On" 2 "Not Used" 3 "Error Indicator" ;
VAL_ 3221225472 Wiper_RrWiperWshSwSta 0 "Off" 1 "On" 2 "Not Used" 3 "Error Indicator" ;
VAL_ 3221225472 MFSW_Info 0 "Off" 1 "ON(CAN Type)" 2 "Not Used" 3 "Error Indicator" ;
VAL_ 3221225472 RCCA_BrkCmdSta 0 "RCCA Brake off" 1 "RCCA Brake on" 2 "Not used" 3 "Error Indicator" ;
VAL_ 3221225472 RCCA_LftWrngSta 0 "RCCA Left Warning is Off" 1 "RCCA Left Warning is On" 2 "Not used" 3 "Error Indicator" ;
VAL_ 3221225472 RCCA_RtWrngSta 0 "RCCA Right Warning is Off" 1 "RCCA Right Warning is On" 2 "Not used" 3 "Error Indicator" ;
VAL_ 3221225472 RCCA_FuncStat 0 "ESC Normal" 1 "Not support (ESC failure)" 2 "Not used" 3 "Error Indicator" ;
VAL_ 3221225472 RCCA_Sta 0 "Default" 1 "RCCA is Off" 2 "RCCA Passive" 3 "RCCA Active" 4 "RCCA Failure" 5 "RCCA Blockage" 6 "RCCA Minor Failure" 7 "Reserved" 8 "Reserved" 9 "Reserved" 10 "Reserved" 11 "Reserved" 12 "Reserved" 13 "Reserved" 14 "Reserved" ;
VAL_ 3221225472 SEA_Sta 0 "Default" 1 "SEA Function is off" 2 "SEA Function is passive" 3 "SEA Function active" 4 "SEA Function failure" 5 "SEA Function Blockage" 6 "SEA Function minor failure" 7 "Reserved" 8 "Reserved" 9 "Reserved" 10 "Reserved" 11 "Reserved" 12 "Reserved" 13 "Reserved" 14 "Reserved" ;
VAL_ 3221225472 SEA_OnOffEquipSta 0 "Default" 1 "Off" 2 "Warning" 3 "?Invalid" ;
VAL_ 3221225472 SEA_LftWrngSta 0 "SEA Left Warning OFF" 1 "SEA Left Warning ON" 2 "Not used" 3 "Error Indicator" ;
VAL_ 3221225472 SEA_RtWrngSta 0 "SEA Right Warning OFF" 1 "SEA Right Warning ON" 2 "Not used" 3 "Error Indicator" ;
VAL_ 3221225472 RR_C_RDR_Equip 0 "No Coding" 1 "Two Corner Radar" 2 "Four Corner Radar" 3 "Reserved" 4 "Reserved" 5 "Reserved" 6 "Reserved" 7 "Error indicator" ;
VAL_ 3221225472 Lamp_HdLmpHiSwSta 0 "Off" 1 "On" 2 "Not Used" 3 "Error Indicator" ;
VAL_ 3221225472 Lamp_LtSwSta 0 "Light Sw Off" 1 "Tail Sw On" 2 "HeadLamp Low Sw On" 3 "AutoLight Sw On" ;
VAL_ 3221225472 Lamp_PassingLmpSwSta 0 "Off" 1 "On" 2 "Not Used" 3 "Error Indicator" ;
VAL_ 3221225472 Lamp_RrFogLmpSwSta 0 "Off" 1 "On" 2 "Not Used" 3 "Error Indicator" ;
VAL_ 3221225472 Lamp_TrnSigLftSwSta 0 "Off" 1 "On" 2 "Not Used" 3 "Error Indicator" ;
VAL_ 3221225472 Lamp_TrnSigRtSwSta 0 "Off" 1 "On" 2 "Not Used" 3 "Error Indicator" ;
VAL_ 3221225472 Lamp_LaneChgTrnSigLftSwSta 0 "Off" 1 "On" 2 "Not Used" 3 "Error Indicator" ;
VAL_ 3221225472 Lamp_LaneChgTrnSigRtSwSta 0 "Off" 1 "On" 2 "Not Used" 3 "Error Indicator" ;
VAL_ 3221225472 RCCW_Sta 0 "Default" 1 "RCCW is Off" 2 "RCCW Passive" 3 "RCCW Active" 4 "RCCW Failure" 5 "RCCW Blockage" 6 "RCCW Minor Failure" 7 "Reserved" 8 "Reserved" 9 "Reserved" 10 "Reserved" 11 "Reserved" 12 "Reserved" 13 "Reserved" 14 "Reserved" ;
VAL_ 3221225472 RCCW_OnOffEquipSt 0 "Default" 1 "Off" 2 "Warning" 3 "?Invalid" ;
VAL_ 3221225472 RCCW_LftIndSta 0 "Indicator output off" 1 "Indicator on (information)" 2 "Indicator blinking(warning)" 3 "Indicator output check" ;
VAL_ 3221225472 RCCW_RtIndSta 0 "Indicator output off" 1 "Indicator on (information)" 2 "Indicator blinking(warning)" 3 "Indicator output check" ;
VAL_ 3221225472 RCCW_LftSndWrngSta 0 "Speaker is Off" 1 "Speaker On" 2 "Not used" 3 "Error Indicator" ;
VAL_ 3221225472 RCCW_RtSndWrngSta 0 "Speaker is Off" 1 "Speaker On" 2 "Not used" 3 "Error Indicator" ;
VAL_ 3221225472 NMSleepFlag_MLM 0 "Alive" 1 "SleepInd" 3 "SleepAck" ;
VAL_ 3221225472 NMCommandCode_MLM 1 "Alive" 2 "Ring" 4 "Limphome" ;
VAL_ 3221225472 NMSleepFlag_IBU_HS 0 "Alive" 1 "SleepInd" 3 "SleepAck" ;
VAL_ 3221225472 NMCommandCode_IBU_HS 1 "Alive" 2 "Ring" 4 "Limphome" ;
VAL_ 3221225472 NMSleepFlag_ILCU_RH 0 "Alive" 1 "SleepInd" 3 "SleepAck" ;
VAL_ 3221225472 NMCommandCode_ILCU_RH 1 "Alive" 2 "Ring" 4 "Limphome" ;
VAL_ 3221225472 NMSleepFlag_MFSW 0 "Alive" 1 "SleepInd" 3 "SleepAck" ;
VAL_ 3221225472 NMCommandCode_MFSW 1 "Alive" 2 "Ring" 4 "Limphome" ;
VAL_ 3221225472 NMSleepFlag_ILCU_LH 0 "Alive" 1 "SleepInd" 3 "SleepAck" ;
VAL_ 3221225472 NMCommandCode_ILCU_LH 1 "Alive" 2 "Ring" 4 "Limphome" ;
VAL_ 3221225472 NMSleepFlag_PSB 0 "Alive" 1 "SleepInd" 3 "SleepAck" ;
VAL_ 3221225472 NMCommandCode_PSB 1 "Alive" 2 "Ring" 4 "Limphome" ;
VAL_ 3221225472 NMSleepFlag_APSU 0 "Alive" 1 "SleepInd" 3 "SleepAck" ;
VAL_ 3221225472 NMCommandCode_APSU 1 "Alive" 2 "Ring" 4 "Limphome" ;
VAL_ 3221225472 NMSleepFlag_DPSS 0 "Alive" 1 "SleepInd" 3 "SleepAck" ;
VAL_ 3221225472 NMCommandCode_DPSS 1 "Alive" 2 "Ring" 4 "Limphome" ;
VAL_ 3221225472 NMSleepFlag_SWRC 0 "Alive" 1 "SleepInd" 3 "SleepAck" ;
VAL_ 3221225472 NMCommandCode_SWRC 1 "Alive" 2 "Ring" 4 "Limphome" ;
VAL_ 3221225472 NMSleepFlag_CGW 0 "Alive" 1 "SleepInd" 3 "SleepAck" ;
VAL_ 3221225472 NMCommandCode_CGW 1 "Alive" 2 "Ring" 4 "Limphome" ;
VAL_ 3221225472 NMSleepFlag_PTGM 0 "Alive" 1 "SleepInd" 3 "SleepAck" ;
VAL_ 3221225472 NMCommandCode_PTGM 1 "Alive" 2 "Ring" 4 "Limphome" ;
VAL_ 3221225472 NMSleepFlag_DLBCU 0 "Alive" 1 "SleepInd" 3 "SleepAck" ;
VAL_ 3221225472 NMCommandCode_DLBCU 1 "Alive" 2 "Ring" 4 "Limphome" ;
VAL_ 3221225472 NMSleepFlag_SCM 0 "Alive" 1 "SleepInd" 3 "SleepAck" ;
VAL_ 3221225472 NMCommandCode_SCM 1 "Alive" 2 "Ring" 4 "Limphome" ;
VAL_ 3221225472 NMSleepFlag_DAU 0 "Alive" 1 "SleepInd" 3 "SleepAck" ;
VAL_ 3221225472 NMCommandCode_DAU 1 "Alive" 2 "Ring" 4 "Limphome" ;
VAL_ 3221225472 NMSleepFlag_WPC 0 "Alive" 1 "SleepInd" 3 "SleepAck" ;
VAL_ 3221225472 NMCommandCode_WPC 1 "Alive" 2 "Ring" 4 "Limphome" ;
VAL_ 3221225472 NMSleepFlag_IAU 0 "Alive" 1 "SleepInd" 3 "SleepAck" ;
VAL_ 3221225472 NMCommandCode_IAU 1 "Alive" 2 "Ring" 4 "Limphome" ;
VAL_ 3221225472 NMSleepFlag_PFSU 0 "Alive" 1 "SleepInd" 3 "SleepAck" ;
VAL_ 3221225472 NMCommandCode_PFSU 1 "Alive" 2 "Ring" 4 "Limphome" ;
VAL_ 3221225472 NMSleepFlag_PSM 0 "Alive" 1 "SleepInd" 3 "SleepAck" ;
VAL_ 3221225472 NMCommandCode_PSM 1 "Alive" 2 "Ring" 4 "Limphome" ;
VAL_ 1051 Lamp_HbaCtrlModTyp 0 "H/Lamp High control Mode by BCM" 1 "H/Lamp High control Mode by HBA" 2 "Not Used" 3 "Error Indicator" ;
VAL_ 1051 Lamp_IFSCtrlModTyp 0 "H/Lamp High control Mode by BCM" 1 "H/Lamp High control Mode by IFS" 2 "Not Used" 3 "Error Indicator" ;
VAL_ 1051 Lamp_RrFogLmpOnReq 0 "Off" 1 "On" 2 "Not Used" 3 "Error Indicator" ;
VAL_ 1051 Lamp_TailLmpWlcmCmd 0 "Off" 1 "On" 2 "Not Used" 3 "Error Indicator" ;
VAL_ 1051 Lamp_HdLmpWlcmCmd 0 "Off" 1 "On" 2 "Not Used" 3 "Error Indicator" ;
VAL_ 1051 Lamp_PuddleLmpOnReq 0 "Off" 1 "On" 2 "Not Used" 3 "Error Indicator" ;
VAL_ 1050 Lamp_HiPrioHzrdReq 0 "Off" 1 "High On" 2 "High Inactive" 3 "Reserved" 4 "Reserved" 5 "Reseved" 6 "Not Used" 7 "Error Indicator" ;
VAL_ 1050 Lamp_LoPrioHzrdReq 0 "Off" 1 "Low On" 2 "Low Inactive" 3 "Reserved" 4 "Reserved" 5 "Reseved" 6 "Not Used" 7 "Error Indicator" ;
VAL_ 1050 Lamp_DedicatedDrlOnReq 0 "Off" 1 "On" 2 "Not Used" 3 "Error Indicator" ;
VAL_ 1050 Lamp_IntTailLmpOnReq 0 "Off" 1 "On" 2 "Not Used" 3 "Error Indicator" ;
VAL_ 1050 Lamp_ExtrnlTailLmpOnReq 0 "Off" 1 "On" 2 "Not Used" 3 "Error Indicator" ;
VAL_ 1050 Lamp_HdLmpLoOnReq 0 "Off" 1 "On" 2 "Not Used" 3 "Error Indicator" ;
VAL_ 1050 Lamp_HdLmpHiOnReq 0 "Off" 1 "On" 2 "Not Used" 3 "Error Indicator" ;
VAL_ 1050 Lamp_AvTailLmpSta 0 "Off" 1 "On" 2 "Not Used" 3 "Error Indicator" ;
VAL_ 1050 Lamp_ExtrnlLpWlcmSta 0 "Off" 1 "On by RKE Unlock" 2 "On by RKE Lock" 3 "Error Indicator" ;
VAL_ 1043 ExtLamp_TrnSigLmpLftBlnkngSta 0 "Off" 1 "On" 2 "Not Used" 3 "Error Indicator" ;
VAL_ 1043 ExtLamp_TrnSigLmpRtBlnkngSta 0 "Off" 1 "On" 2 "Not Used" 3 "Error Indicator" ;
VAL_ 1043 ExtLamp_ExtrnlTailLmpSta 0 "Off" 1 "On" 2 "Not Used" 3 "Error Indicator" ;
VAL_ 1043 ExtLamp_HzrdSwSta 0 "Off" 1 "On" 2 "Not Used" 3 "Error Indicator" ;
VAL_ 1043 ExtLamp_RrFgLmpSta 0 "Off" 1 "On" 2 "Not Used" 3 "Error Indicator" ;
VAL_ 1043 IntLamp_InlTailLmpSta 0 "Off" 1 "On" 2 "Not Used" 3 "Error Indicator" ;
VAL_ 1043 Lamp_TrnSigLmpLftOnReq 0 "Inactive" 1 "Active Off(Flasher Off)" 2 "Active On(Flasher On)" 3 "reserved" ;
VAL_ 1043 Lamp_TrnSigLmpRtOnReq 0 "Inactive" 1 "Active Off(Flasher Off)" 2 "Active On(Flasher On)" 3 "reserved" ;
